[part 4 of 12: package /AUTOSAR_Dem/SwComponentTypes]
AUTOSAR XML (schema 4-2-2)
package /AUTOSAR_Dem/SwComponentTypes  (continued)
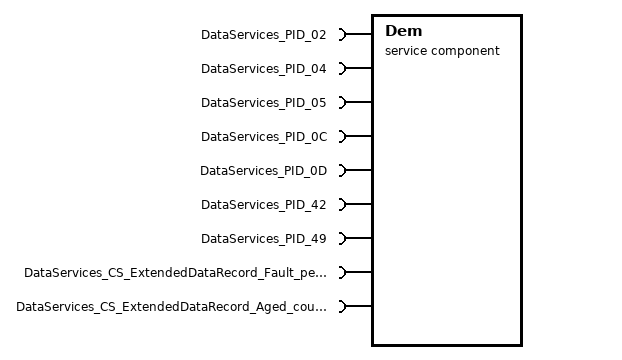
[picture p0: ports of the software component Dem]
  service sw component type Dem  (continued)
    2013 x provide port:  (continued)
      EvtInfo_DemEventParameter_ECU5_DTC09: provided-interface=DiagnosticInfo
        provided-com-specs:
          operation=DiagnosticInfo/GetEventStatus, queue-length=1
          operation=DiagnosticInfo/GetEventFailed, queue-length=1
          operation=DiagnosticInfo/GetEventTested, queue-length=1
          operation=DiagnosticInfo/GetDTCOfEvent, queue-length=1
          operation=DiagnosticInfo/GetDebouncingOfEvent, queue-length=1
          operation=DiagnosticInfo/GetFaultDetectionCounter, queue-length=1
          operation=DiagnosticInfo/GetEventExtendedDataRecord, queue-length=1
          operation=DiagnosticInfo/GetEventExtendedDataRecordEx, queue-length=1
          operation=DiagnosticInfo/GetEventFreezeFrameData, queue-length=1
          operation=DiagnosticInfo/GetEventFreezeFrameDataEx, queue-length=1
      EvtInfo_DemEventParameter_ECU5_DTC10: provided-interface=DiagnosticInfo
        provided-com-specs:
          operation=DiagnosticInfo/GetEventStatus, queue-length=1
          operation=DiagnosticInfo/GetEventFailed, queue-length=1
          operation=DiagnosticInfo/GetEventTested, queue-length=1
          operation=DiagnosticInfo/GetDTCOfEvent, queue-length=1
          operation=DiagnosticInfo/GetDebouncingOfEvent, queue-length=1
          operation=DiagnosticInfo/GetFaultDetectionCounter, queue-length=1
          operation=DiagnosticInfo/GetEventExtendedDataRecord, queue-length=1
          operation=DiagnosticInfo/GetEventExtendedDataRecordEx, queue-length=1
          operation=DiagnosticInfo/GetEventFreezeFrameData, queue-length=1
          operation=DiagnosticInfo/GetEventFreezeFrameDataEx, queue-length=1
      EvtInfo_DemEventParameter_ECU5_DTC11: provided-interface=DiagnosticInfo
        provided-com-specs:
          operation=DiagnosticInfo/GetEventStatus, queue-length=1
          operation=DiagnosticInfo/GetEventFailed, queue-length=1
          operation=DiagnosticInfo/GetEventTested, queue-length=1
          operation=DiagnosticInfo/GetDTCOfEvent, queue-length=1
          operation=DiagnosticInfo/GetDebouncingOfEvent, queue-length=1
          operation=DiagnosticInfo/GetFaultDetectionCounter, queue-length=1
          operation=DiagnosticInfo/GetEventExtendedDataRecord, queue-length=1
          operation=DiagnosticInfo/GetEventExtendedDataRecordEx, queue-length=1
          operation=DiagnosticInfo/GetEventFreezeFrameData, queue-length=1
          operation=DiagnosticInfo/GetEventFreezeFrameDataEx, queue-length=1
      EvtInfo_DemEventParameter_ECU5_DTC12: provided-interface=DiagnosticInfo
        provided-com-specs:
          operation=DiagnosticInfo/GetEventStatus, queue-length=1
          operation=DiagnosticInfo/GetEventFailed, queue-length=1
          operation=DiagnosticInfo/GetEventTested, queue-length=1
          operation=DiagnosticInfo/GetDTCOfEvent, queue-length=1
          operation=DiagnosticInfo/GetDebouncingOfEvent, queue-length=1
          operation=DiagnosticInfo/GetFaultDetectionCounter, queue-length=1
          operation=DiagnosticInfo/GetEventExtendedDataRecord, queue-length=1
          operation=DiagnosticInfo/GetEventExtendedDataRecordEx, queue-length=1
          operation=DiagnosticInfo/GetEventFreezeFrameData, queue-length=1
          operation=DiagnosticInfo/GetEventFreezeFrameDataEx, queue-length=1
      EvtInfo_DemEventParameter_ECU5_DTC13: provided-interface=DiagnosticInfo
        provided-com-specs:
          operation=DiagnosticInfo/GetEventStatus, queue-length=1
          operation=DiagnosticInfo/GetEventFailed, queue-length=1
          operation=DiagnosticInfo/GetEventTested, queue-length=1
          operation=DiagnosticInfo/GetDTCOfEvent, queue-length=1
          operation=DiagnosticInfo/GetDebouncingOfEvent, queue-length=1
          operation=DiagnosticInfo/GetFaultDetectionCounter, queue-length=1
          operation=DiagnosticInfo/GetEventExtendedDataRecord, queue-length=1
          operation=DiagnosticInfo/GetEventExtendedDataRecordEx, queue-length=1
          operation=DiagnosticInfo/GetEventFreezeFrameData, queue-length=1
          operation=DiagnosticInfo/GetEventFreezeFrameDataEx, queue-length=1
      EvtInfo_DemEventParameter_ECU5_DTC14: provided-interface=DiagnosticInfo
        provided-com-specs:
          operation=DiagnosticInfo/GetEventStatus, queue-length=1
          operation=DiagnosticInfo/GetEventFailed, queue-length=1
          operation=DiagnosticInfo/GetEventTested, queue-length=1
          operation=DiagnosticInfo/GetDTCOfEvent, queue-length=1
          operation=DiagnosticInfo/GetDebouncingOfEvent, queue-length=1
          operation=DiagnosticInfo/GetFaultDetectionCounter, queue-length=1
          operation=DiagnosticInfo/GetEventExtendedDataRecord, queue-length=1
          operation=DiagnosticInfo/GetEventExtendedDataRecordEx, queue-length=1
          operation=DiagnosticInfo/GetEventFreezeFrameData, queue-length=1
          operation=DiagnosticInfo/GetEventFreezeFrameDataEx, queue-length=1
      EvtInfo_DemEventParameter_ECU5_DTC15: provided-interface=DiagnosticInfo
        provided-com-specs:
          operation=DiagnosticInfo/GetEventStatus, queue-length=1
          operation=DiagnosticInfo/GetEventFailed, queue-length=1
          operation=DiagnosticInfo/GetEventTested, queue-length=1
          operation=DiagnosticInfo/GetDTCOfEvent, queue-length=1
          operation=DiagnosticInfo/GetDebouncingOfEvent, queue-length=1
          operation=DiagnosticInfo/GetFaultDetectionCounter, queue-length=1
          operation=DiagnosticInfo/GetEventExtendedDataRecord, queue-length=1
          operation=DiagnosticInfo/GetEventExtendedDataRecordEx, queue-length=1
          operation=DiagnosticInfo/GetEventFreezeFrameData, queue-length=1
          operation=DiagnosticInfo/GetEventFreezeFrameDataEx, queue-length=1
      EvtInfo_DemEventParameter_ECU5_DTC16: provided-interface=DiagnosticInfo
        provided-com-specs:
          operation=DiagnosticInfo/GetEventStatus, queue-length=1
          operation=DiagnosticInfo/GetEventFailed, queue-length=1
          operation=DiagnosticInfo/GetEventTested, queue-length=1
          operation=DiagnosticInfo/GetDTCOfEvent, queue-length=1
          operation=DiagnosticInfo/GetDebouncingOfEvent, queue-length=1
          operation=DiagnosticInfo/GetFaultDetectionCounter, queue-length=1
          operation=DiagnosticInfo/GetEventExtendedDataRecord, queue-length=1
          operation=DiagnosticInfo/GetEventExtendedDataRecordEx, queue-length=1
          operation=DiagnosticInfo/GetEventFreezeFrameData, queue-length=1
          operation=DiagnosticInfo/GetEventFreezeFrameDataEx, queue-length=1
      EvtInfo_DemEventParameter_ECU5_DTC17: provided-interface=DiagnosticInfo
        provided-com-specs:
          operation=DiagnosticInfo/GetEventStatus, queue-length=1
          operation=DiagnosticInfo/GetEventFailed, queue-length=1
          operation=DiagnosticInfo/GetEventTested, queue-length=1
          operation=DiagnosticInfo/GetDTCOfEvent, queue-length=1
          operation=DiagnosticInfo/GetDebouncingOfEvent, queue-length=1
          operation=DiagnosticInfo/GetFaultDetectionCounter, queue-length=1
          operation=DiagnosticInfo/GetEventExtendedDataRecord, queue-length=1
          operation=DiagnosticInfo/GetEventExtendedDataRecordEx, queue-length=1
          operation=DiagnosticInfo/GetEventFreezeFrameData, queue-length=1
          operation=DiagnosticInfo/GetEventFreezeFrameDataEx, queue-length=1
      EvtInfo_DemEventParameter_ECU5_DTC18: provided-interface=DiagnosticInfo
        provided-com-specs:
          operation=DiagnosticInfo/GetEventStatus, queue-length=1
          operation=DiagnosticInfo/GetEventFailed, queue-length=1
          operation=DiagnosticInfo/GetEventTested, queue-length=1
          operation=DiagnosticInfo/GetDTCOfEvent, queue-length=1
          operation=DiagnosticInfo/GetDebouncingOfEvent, queue-length=1
          operation=DiagnosticInfo/GetFaultDetectionCounter, queue-length=1
          operation=DiagnosticInfo/GetEventExtendedDataRecord, queue-length=1
          operation=DiagnosticInfo/GetEventExtendedDataRecordEx, queue-length=1
          operation=DiagnosticInfo/GetEventFreezeFrameData, queue-length=1
          operation=DiagnosticInfo/GetEventFreezeFrameDataEx, queue-length=1
      EvtInfo_DemEventParameter_ECU5_DTC19: provided-interface=DiagnosticInfo
        provided-com-specs:
          operation=DiagnosticInfo/GetEventStatus, queue-length=1
          operation=DiagnosticInfo/GetEventFailed, queue-length=1
          operation=DiagnosticInfo/GetEventTested, queue-length=1
          operation=DiagnosticInfo/GetDTCOfEvent, queue-length=1
          operation=DiagnosticInfo/GetDebouncingOfEvent, queue-length=1
          operation=DiagnosticInfo/GetFaultDetectionCounter, queue-length=1
          operation=DiagnosticInfo/GetEventExtendedDataRecord, queue-length=1
          operation=DiagnosticInfo/GetEventExtendedDataRecordEx, queue-length=1
          operation=DiagnosticInfo/GetEventFreezeFrameData, queue-length=1
          operation=DiagnosticInfo/GetEventFreezeFrameDataEx, queue-length=1
      EvtInfo_DemEventParameter_ECU5_DTC20: provided-interface=DiagnosticInfo
        provided-com-specs:
          operation=DiagnosticInfo/GetEventStatus, queue-length=1
          operation=DiagnosticInfo/GetEventFailed, queue-length=1
          operation=DiagnosticInfo/GetEventTested, queue-length=1
          operation=DiagnosticInfo/GetDTCOfEvent, queue-length=1
          operation=DiagnosticInfo/GetDebouncingOfEvent, queue-length=1
          operation=DiagnosticInfo/GetFaultDetectionCounter, queue-length=1
          operation=DiagnosticInfo/GetEventExtendedDataRecord, queue-length=1
          operation=DiagnosticInfo/GetEventExtendedDataRecordEx, queue-length=1
          operation=DiagnosticInfo/GetEventFreezeFrameData, queue-length=1
          operation=DiagnosticInfo/GetEventFreezeFrameDataEx, queue-length=1
      EvtInfo_DemEventParameter_ECU5_DTC21: provided-interface=DiagnosticInfo
        provided-com-specs:
          operation=DiagnosticInfo/GetEventStatus, queue-length=1
          operation=DiagnosticInfo/GetEventFailed, queue-length=1
          operation=DiagnosticInfo/GetEventTested, queue-length=1
          operation=DiagnosticInfo/GetDTCOfEvent, queue-length=1
          operation=DiagnosticInfo/GetDebouncingOfEvent, queue-length=1
          operation=DiagnosticInfo/GetFaultDetectionCounter, queue-length=1
          operation=DiagnosticInfo/GetEventExtendedDataRecord, queue-length=1
          operation=DiagnosticInfo/GetEventExtendedDataRecordEx, queue-length=1
          operation=DiagnosticInfo/GetEventFreezeFrameData, queue-length=1
          operation=DiagnosticInfo/GetEventFreezeFrameDataEx, queue-length=1
      EvtInfo_DemEventParameter_ECU5_DTC22: provided-interface=DiagnosticInfo
        provided-com-specs:
          operation=DiagnosticInfo/GetEventStatus, queue-length=1
          operation=DiagnosticInfo/GetEventFailed, queue-length=1
          operation=DiagnosticInfo/GetEventTested, queue-length=1
          operation=DiagnosticInfo/GetDTCOfEvent, queue-length=1
          operation=DiagnosticInfo/GetDebouncingOfEvent, queue-length=1
          operation=DiagnosticInfo/GetFaultDetectionCounter, queue-length=1
          operation=DiagnosticInfo/GetEventExtendedDataRecord, queue-length=1
          operation=DiagnosticInfo/GetEventExtendedDataRecordEx, queue-length=1
          operation=DiagnosticInfo/GetEventFreezeFrameData, queue-length=1
          operation=DiagnosticInfo/GetEventFreezeFrameDataEx, queue-length=1
      EvtInfo_DemEventParameter_ECU5_DTC23: provided-interface=DiagnosticInfo
        provided-com-specs:
          operation=DiagnosticInfo/GetEventStatus, queue-length=1
          operation=DiagnosticInfo/GetEventFailed, queue-length=1
          operation=DiagnosticInfo/GetEventTested, queue-length=1
          operation=DiagnosticInfo/GetDTCOfEvent, queue-length=1
          operation=DiagnosticInfo/GetDebouncingOfEvent, queue-length=1
          operation=DiagnosticInfo/GetFaultDetectionCounter, queue-length=1
          operation=DiagnosticInfo/GetEventExtendedDataRecord, queue-length=1
          operation=DiagnosticInfo/GetEventExtendedDataRecordEx, queue-length=1
          operation=DiagnosticInfo/GetEventFreezeFrameData, queue-length=1
          operation=DiagnosticInfo/GetEventFreezeFrameDataEx, queue-length=1
      EvtInfo_DemEventParameter_ECU5_DTC24: provided-interface=DiagnosticInfo
        provided-com-specs:
          operation=DiagnosticInfo/GetEventStatus, queue-length=1
          operation=DiagnosticInfo/GetEventFailed, queue-length=1
          operation=DiagnosticInfo/GetEventTested, queue-length=1
          operation=DiagnosticInfo/GetDTCOfEvent, queue-length=1
          operation=DiagnosticInfo/GetDebouncingOfEvent, queue-length=1
          operation=DiagnosticInfo/GetFaultDetectionCounter, queue-length=1
          operation=DiagnosticInfo/GetEventExtendedDataRecord, queue-length=1
          operation=DiagnosticInfo/GetEventExtendedDataRecordEx, queue-length=1
          operation=DiagnosticInfo/GetEventFreezeFrameData, queue-length=1
          operation=DiagnosticInfo/GetEventFreezeFrameDataEx, queue-length=1
      EvtInfo_DemEventParameter_ECU5_DTC25: provided-interface=DiagnosticInfo
        provided-com-specs:
          operation=DiagnosticInfo/GetEventStatus, queue-length=1
          operation=DiagnosticInfo/GetEventFailed, queue-length=1
          operation=DiagnosticInfo/GetEventTested, queue-length=1
          operation=DiagnosticInfo/GetDTCOfEvent, queue-length=1
          operation=DiagnosticInfo/GetDebouncingOfEvent, queue-length=1
          operation=DiagnosticInfo/GetFaultDetectionCounter, queue-length=1
          operation=DiagnosticInfo/GetEventExtendedDataRecord, queue-length=1
          operation=DiagnosticInfo/GetEventExtendedDataRecordEx, queue-length=1
          operation=DiagnosticInfo/GetEventFreezeFrameData, queue-length=1
          operation=DiagnosticInfo/GetEventFreezeFrameDataEx, queue-length=1
      EvtInfo_DemEventParameter_ECU5_DTC26: provided-interface=DiagnosticInfo
        provided-com-specs:
          operation=DiagnosticInfo/GetEventStatus, queue-length=1
          operation=DiagnosticInfo/GetEventFailed, queue-length=1
          operation=DiagnosticInfo/GetEventTested, queue-length=1
          operation=DiagnosticInfo/GetDTCOfEvent, queue-length=1
          operation=DiagnosticInfo/GetDebouncingOfEvent, queue-length=1
          operation=DiagnosticInfo/GetFaultDetectionCounter, queue-length=1
          operation=DiagnosticInfo/GetEventExtendedDataRecord, queue-length=1
          operation=DiagnosticInfo/GetEventExtendedDataRecordEx, queue-length=1
          operation=DiagnosticInfo/GetEventFreezeFrameData, queue-length=1
          operation=DiagnosticInfo/GetEventFreezeFrameDataEx, queue-length=1
      EvtInfo_DemEventParameter_ECU5_DTC27: provided-interface=DiagnosticInfo
        provided-com-specs:
          operation=DiagnosticInfo/GetEventStatus, queue-length=1
          operation=DiagnosticInfo/GetEventFailed, queue-length=1
          operation=DiagnosticInfo/GetEventTested, queue-length=1
          operation=DiagnosticInfo/GetDTCOfEvent, queue-length=1
          operation=DiagnosticInfo/GetDebouncingOfEvent, queue-length=1
          operation=DiagnosticInfo/GetFaultDetectionCounter, queue-length=1
          operation=DiagnosticInfo/GetEventExtendedDataRecord, queue-length=1
          operation=DiagnosticInfo/GetEventExtendedDataRecordEx, queue-length=1
          operation=DiagnosticInfo/GetEventFreezeFrameData, queue-length=1
          operation=DiagnosticInfo/GetEventFreezeFrameDataEx, queue-length=1
      EvtInfo_DemEventParameter_ECU5_DTC28: provided-interface=DiagnosticInfo
        provided-com-specs:
          operation=DiagnosticInfo/GetEventStatus, queue-length=1
          operation=DiagnosticInfo/GetEventFailed, queue-length=1
          operation=DiagnosticInfo/GetEventTested, queue-length=1
          operation=DiagnosticInfo/GetDTCOfEvent, queue-length=1
          operation=DiagnosticInfo/GetDebouncingOfEvent, queue-length=1
          operation=DiagnosticInfo/GetFaultDetectionCounter, queue-length=1
          operation=DiagnosticInfo/GetEventExtendedDataRecord, queue-length=1
          operation=DiagnosticInfo/GetEventExtendedDataRecordEx, queue-length=1
          operation=DiagnosticInfo/GetEventFreezeFrameData, queue-length=1
          operation=DiagnosticInfo/GetEventFreezeFrameDataEx, queue-length=1
      EvtInfo_DemEventParameter_ECU5_DTC29: provided-interface=DiagnosticInfo
        provided-com-specs:
          operation=DiagnosticInfo/GetEventStatus, queue-length=1
          operation=DiagnosticInfo/GetEventFailed, queue-length=1
          operation=DiagnosticInfo/GetEventTested, queue-length=1
          operation=DiagnosticInfo/GetDTCOfEvent, queue-length=1
          operation=DiagnosticInfo/GetDebouncingOfEvent, queue-length=1
          operation=DiagnosticInfo/GetFaultDetectionCounter, queue-length=1
          operation=DiagnosticInfo/GetEventExtendedDataRecord, queue-length=1
          operation=DiagnosticInfo/GetEventExtendedDataRecordEx, queue-length=1
          operation=DiagnosticInfo/GetEventFreezeFrameData, queue-length=1
          operation=DiagnosticInfo/GetEventFreezeFrameDataEx, queue-length=1
      EvtInfo_DemEventParameter_ECU5_DTC30: provided-interface=DiagnosticInfo
        provided-com-specs:
          operation=DiagnosticInfo/GetEventStatus, queue-length=1
          operation=DiagnosticInfo/GetEventFailed, queue-length=1
          operation=DiagnosticInfo/GetEventTested, queue-length=1
          operation=DiagnosticInfo/GetDTCOfEvent, queue-length=1
          operation=DiagnosticInfo/GetDebouncingOfEvent, queue-length=1
          operation=DiagnosticInfo/GetFaultDetectionCounter, queue-length=1
          operation=DiagnosticInfo/GetEventExtendedDataRecord, queue-length=1
          operation=DiagnosticInfo/GetEventExtendedDataRecordEx, queue-length=1
          operation=DiagnosticInfo/GetEventFreezeFrameData, queue-length=1
          operation=DiagnosticInfo/GetEventFreezeFrameDataEx, queue-length=1
      EvtInfo_DemEventParameter_ECU5_DTC31: provided-interface=DiagnosticInfo
        provided-com-specs:
          operation=DiagnosticInfo/GetEventStatus, queue-length=1
          operation=DiagnosticInfo/GetEventFailed, queue-length=1
          operation=DiagnosticInfo/GetEventTested, queue-length=1
          operation=DiagnosticInfo/GetDTCOfEvent, queue-length=1
          operation=DiagnosticInfo/GetDebouncingOfEvent, queue-length=1
          operation=DiagnosticInfo/GetFaultDetectionCounter, queue-length=1
          operation=DiagnosticInfo/GetEventExtendedDataRecord, queue-length=1
          operation=DiagnosticInfo/GetEventExtendedDataRecordEx, queue-length=1
          operation=DiagnosticInfo/GetEventFreezeFrameData, queue-length=1
          operation=DiagnosticInfo/GetEventFreezeFrameDataEx, queue-length=1
      EvtInfo_DemEventParameter_ECU5_DTC32: provided-interface=DiagnosticInfo
        provided-com-specs:
          operation=DiagnosticInfo/GetEventStatus, queue-length=1
          operation=DiagnosticInfo/GetEventFailed, queue-length=1
          operation=DiagnosticInfo/GetEventTested, queue-length=1
          operation=DiagnosticInfo/GetDTCOfEvent, queue-length=1
          operation=DiagnosticInfo/GetDebouncingOfEvent, queue-length=1
          operation=DiagnosticInfo/GetFaultDetectionCounter, queue-length=1
          operation=DiagnosticInfo/GetEventExtendedDataRecord, queue-length=1
          operation=DiagnosticInfo/GetEventExtendedDataRecordEx, queue-length=1
          operation=DiagnosticInfo/GetEventFreezeFrameData, queue-length=1
          operation=DiagnosticInfo/GetEventFreezeFrameDataEx, queue-length=1
      EvtInfo_DemEventParameter_ECU5_DTC33: provided-interface=DiagnosticInfo
        provided-com-specs:
          operation=DiagnosticInfo/GetEventStatus, queue-length=1
          operation=DiagnosticInfo/GetEventFailed, queue-length=1
          operation=DiagnosticInfo/GetEventTested, queue-length=1
          operation=DiagnosticInfo/GetDTCOfEvent, queue-length=1
          operation=DiagnosticInfo/GetDebouncingOfEvent, queue-length=1
          operation=DiagnosticInfo/GetFaultDetectionCounter, queue-length=1
          operation=DiagnosticInfo/GetEventExtendedDataRecord, queue-length=1
          operation=DiagnosticInfo/GetEventExtendedDataRecordEx, queue-length=1
          operation=DiagnosticInfo/GetEventFreezeFrameData, queue-length=1
          operation=DiagnosticInfo/GetEventFreezeFrameDataEx, queue-length=1
      EvtInfo_DemEventParameter_ECU5_DTC34: provided-interface=DiagnosticInfo
        provided-com-specs:
          operation=DiagnosticInfo/GetEventStatus, queue-length=1
          operation=DiagnosticInfo/GetEventFailed, queue-length=1
          operation=DiagnosticInfo/GetEventTested, queue-length=1
          operation=DiagnosticInfo/GetDTCOfEvent, queue-length=1
          operation=DiagnosticInfo/GetDebouncingOfEvent, queue-length=1
          operation=DiagnosticInfo/GetFaultDetectionCounter, queue-length=1
          operation=DiagnosticInfo/GetEventExtendedDataRecord, queue-length=1
          operation=DiagnosticInfo/GetEventExtendedDataRecordEx, queue-length=1
          operation=DiagnosticInfo/GetEventFreezeFrameData, queue-length=1
          operation=DiagnosticInfo/GetEventFreezeFrameDataEx, queue-length=1
      EvtInfo_DemEventParameter_ECU5_DTC35: provided-interface=DiagnosticInfo
        provided-com-specs:
          operation=DiagnosticInfo/GetEventStatus, queue-length=1
          operation=DiagnosticInfo/GetEventFailed, queue-length=1
          operation=DiagnosticInfo/GetEventTested, queue-length=1
          operation=DiagnosticInfo/GetDTCOfEvent, queue-length=1
          operation=DiagnosticInfo/GetDebouncingOfEvent, queue-length=1
          operation=DiagnosticInfo/GetFaultDetectionCounter, queue-length=1
          operation=DiagnosticInfo/GetEventExtendedDataRecord, queue-length=1
          operation=DiagnosticInfo/GetEventExtendedDataRecordEx, queue-length=1
          operation=DiagnosticInfo/GetEventFreezeFrameData, queue-length=1
          operation=DiagnosticInfo/GetEventFreezeFrameDataEx, queue-length=1
      EvtInfo_DemEventParameter_ECU5_DTC36: provided-interface=DiagnosticInfo
        provided-com-specs:
          operation=DiagnosticInfo/GetEventStatus, queue-length=1
          operation=DiagnosticInfo/GetEventFailed, queue-length=1
          operation=DiagnosticInfo/GetEventTested, queue-length=1
          operation=DiagnosticInfo/GetDTCOfEvent, queue-length=1
          operation=DiagnosticInfo/GetDebouncingOfEvent, queue-length=1
          operation=DiagnosticInfo/GetFaultDetectionCounter, queue-length=1
          operation=DiagnosticInfo/GetEventExtendedDataRecord, queue-length=1
          operation=DiagnosticInfo/GetEventExtendedDataRecordEx, queue-length=1
          operation=DiagnosticInfo/GetEventFreezeFrameData, queue-length=1
          operation=DiagnosticInfo/GetEventFreezeFrameDataEx, queue-length=1
      EvtInfo_DemEventParameter_ECU5_DTC37: provided-interface=DiagnosticInfo
        provided-com-specs:
          operation=DiagnosticInfo/GetEventStatus, queue-length=1
          operation=DiagnosticInfo/GetEventFailed, queue-length=1
          operation=DiagnosticInfo/GetEventTested, queue-length=1
          operation=DiagnosticInfo/GetDTCOfEvent, queue-length=1
          operation=DiagnosticInfo/GetDebouncingOfEvent, queue-length=1
          operation=DiagnosticInfo/GetFaultDetectionCounter, queue-length=1
          operation=DiagnosticInfo/GetEventExtendedDataRecord, queue-length=1
          operation=DiagnosticInfo/GetEventExtendedDataRecordEx, queue-length=1
          operation=DiagnosticInfo/GetEventFreezeFrameData, queue-length=1
          operation=DiagnosticInfo/GetEventFreezeFrameDataEx, queue-length=1
      EvtInfo_DemEventParameter_ECU5_DTC38: provided-interface=DiagnosticInfo
        provided-com-specs:
          operation=DiagnosticInfo/GetEventStatus, queue-length=1
          operation=DiagnosticInfo/GetEventFailed, queue-length=1
          operation=DiagnosticInfo/GetEventTested, queue-length=1
          operation=DiagnosticInfo/GetDTCOfEvent, queue-length=1
          operation=DiagnosticInfo/GetDebouncingOfEvent, queue-length=1
          operation=DiagnosticInfo/GetFaultDetectionCounter, queue-length=1
          operation=DiagnosticInfo/GetEventExtendedDataRecord, queue-length=1
          operation=DiagnosticInfo/GetEventExtendedDataRecordEx, queue-length=1
          operation=DiagnosticInfo/GetEventFreezeFrameData, queue-length=1
          operation=DiagnosticInfo/GetEventFreezeFrameDataEx, queue-length=1
      EvtInfo_DemEventParameter_ECU5_DTC39: provided-interface=DiagnosticInfo
        provided-com-specs:
          operation=DiagnosticInfo/GetEventStatus, queue-length=1
          operation=DiagnosticInfo/GetEventFailed, queue-length=1
          operation=DiagnosticInfo/GetEventTested, queue-length=1
          operation=DiagnosticInfo/GetDTCOfEvent, queue-length=1
          operation=DiagnosticInfo/GetDebouncingOfEvent, queue-length=1
          operation=DiagnosticInfo/GetFaultDetectionCounter, queue-length=1
          operation=DiagnosticInfo/GetEventExtendedDataRecord, queue-length=1
          operation=DiagnosticInfo/GetEventExtendedDataRecordEx, queue-length=1
          operation=DiagnosticInfo/GetEventFreezeFrameData, queue-length=1
          operation=DiagnosticInfo/GetEventFreezeFrameDataEx, queue-length=1
      EvtInfo_DemEventParameter_ECU5_DTC40: provided-interface=DiagnosticInfo
        provided-com-specs:
          operation=DiagnosticInfo/GetEventStatus, queue-length=1
          operation=DiagnosticInfo/GetEventFailed, queue-length=1
          operation=DiagnosticInfo/GetEventTested, queue-length=1
          operation=DiagnosticInfo/GetDTCOfEvent, queue-length=1
          operation=DiagnosticInfo/GetDebouncingOfEvent, queue-length=1
          operation=DiagnosticInfo/GetFaultDetectionCounter, queue-length=1
          operation=DiagnosticInfo/GetEventExtendedDataRecord, queue-length=1
          operation=DiagnosticInfo/GetEventExtendedDataRecordEx, queue-length=1
          operation=DiagnosticInfo/GetEventFreezeFrameData, queue-length=1
          operation=DiagnosticInfo/GetEventFreezeFrameDataEx, queue-length=1
      EvtInfo_DemEventParameter_ECU5_DTC41: provided-interface=DiagnosticInfo
        provided-com-specs:
          operation=DiagnosticInfo/GetEventStatus, queue-length=1
          operation=DiagnosticInfo/GetEventFailed, queue-length=1
          operation=DiagnosticInfo/GetEventTested, queue-length=1
          operation=DiagnosticInfo/GetDTCOfEvent, queue-length=1
          operation=DiagnosticInfo/GetDebouncingOfEvent, queue-length=1
          operation=DiagnosticInfo/GetFaultDetectionCounter, queue-length=1
          operation=DiagnosticInfo/GetEventExtendedDataRecord, queue-length=1
          operation=DiagnosticInfo/GetEventExtendedDataRecordEx, queue-length=1
          operation=DiagnosticInfo/GetEventFreezeFrameData, queue-length=1
          operation=DiagnosticInfo/GetEventFreezeFrameDataEx, queue-length=1
      EvtInfo_DemEventParameter_ECU5_DTC42: provided-interface=DiagnosticInfo
        provided-com-specs:
          operation=DiagnosticInfo/GetEventStatus, queue-length=1
          operation=DiagnosticInfo/GetEventFailed, queue-length=1
          operation=DiagnosticInfo/GetEventTested, queue-length=1
          operation=DiagnosticInfo/GetDTCOfEvent, queue-length=1
          operation=DiagnosticInfo/GetDebouncingOfEvent, queue-length=1
          operation=DiagnosticInfo/GetFaultDetectionCounter, queue-length=1
          operation=DiagnosticInfo/GetEventExtendedDataRecord, queue-length=1
          operation=DiagnosticInfo/GetEventExtendedDataRecordEx, queue-length=1
          operation=DiagnosticInfo/GetEventFreezeFrameData, queue-length=1
          operation=DiagnosticInfo/GetEventFreezeFrameDataEx, queue-length=1
      EvtInfo_DemEventParameter_ECU5_DTC43: provided-interface=DiagnosticInfo
        provided-com-specs:
          operation=DiagnosticInfo/GetEventStatus, queue-length=1
          operation=DiagnosticInfo/GetEventFailed, queue-length=1
          operation=DiagnosticInfo/GetEventTested, queue-length=1
          operation=DiagnosticInfo/GetDTCOfEvent, queue-length=1
          operation=DiagnosticInfo/GetDebouncingOfEvent, queue-length=1
          operation=DiagnosticInfo/GetFaultDetectionCounter, queue-length=1
          operation=DiagnosticInfo/GetEventExtendedDataRecord, queue-length=1
          operation=DiagnosticInfo/GetEventExtendedDataRecordEx, queue-length=1
          operation=DiagnosticInfo/GetEventFreezeFrameData, queue-length=1
          operation=DiagnosticInfo/GetEventFreezeFrameDataEx, queue-length=1
      EvtInfo_DemEventParameter_ECU5_DTC44: provided-interface=DiagnosticInfo
        provided-com-specs:
          operation=DiagnosticInfo/GetEventStatus, queue-length=1
          operation=DiagnosticInfo/GetEventFailed, queue-length=1
          operation=DiagnosticInfo/GetEventTested, queue-length=1
          operation=DiagnosticInfo/GetDTCOfEvent, queue-length=1
          operation=DiagnosticInfo/GetDebouncingOfEvent, queue-length=1
          operation=DiagnosticInfo/GetFaultDetectionCounter, queue-length=1
          operation=DiagnosticInfo/GetEventExtendedDataRecord, queue-length=1
          operation=DiagnosticInfo/GetEventExtendedDataRecordEx, queue-length=1
          operation=DiagnosticInfo/GetEventFreezeFrameData, queue-length=1
          operation=DiagnosticInfo/GetEventFreezeFrameDataEx, queue-length=1
      EvtInfo_DemEventParameter_ECU5_DTC45: provided-interface=DiagnosticInfo
        provided-com-specs:
          operation=DiagnosticInfo/GetEventStatus, queue-length=1
          operation=DiagnosticInfo/GetEventFailed, queue-length=1
          operation=DiagnosticInfo/GetEventTested, queue-length=1
          operation=DiagnosticInfo/GetDTCOfEvent, queue-length=1
          operation=DiagnosticInfo/GetDebouncingOfEvent, queue-length=1
          operation=DiagnosticInfo/GetFaultDetectionCounter, queue-length=1
          operation=DiagnosticInfo/GetEventExtendedDataRecord, queue-length=1
          operation=DiagnosticInfo/GetEventExtendedDataRecordEx, queue-length=1
          operation=DiagnosticInfo/GetEventFreezeFrameData, queue-length=1
          operation=DiagnosticInfo/GetEventFreezeFrameDataEx, queue-length=1
      EvtInfo_DemEventParameter_ECU5_DTC46: provided-interface=DiagnosticInfo
        provided-com-specs:
          operation=DiagnosticInfo/GetEventStatus, queue-length=1
          operation=DiagnosticInfo/GetEventFailed, queue-length=1
          operation=DiagnosticInfo/GetEventTested, queue-length=1
          operation=DiagnosticInfo/GetDTCOfEvent, queue-length=1
          operation=DiagnosticInfo/GetDebouncingOfEvent, queue-length=1
          operation=DiagnosticInfo/GetFaultDetectionCounter, queue-length=1
          operation=DiagnosticInfo/GetEventExtendedDataRecord, queue-length=1
          operation=DiagnosticInfo/GetEventExtendedDataRecordEx, queue-length=1
          operation=DiagnosticInfo/GetEventFreezeFrameData, queue-length=1
          operation=DiagnosticInfo/GetEventFreezeFrameDataEx, queue-length=1
      EvtInfo_DemEventParameter_ECU5_DTC47: provided-interface=DiagnosticInfo
        provided-com-specs:
          operation=DiagnosticInfo/GetEventStatus, queue-length=1
          operation=DiagnosticInfo/GetEventFailed, queue-length=1
          operation=DiagnosticInfo/GetEventTested, queue-length=1
          operation=DiagnosticInfo/GetDTCOfEvent, queue-length=1
          operation=DiagnosticInfo/GetDebouncingOfEvent, queue-length=1
          operation=DiagnosticInfo/GetFaultDetectionCounter, queue-length=1
          operation=DiagnosticInfo/GetEventExtendedDataRecord, queue-length=1
          operation=DiagnosticInfo/GetEventExtendedDataRecordEx, queue-length=1
          operation=DiagnosticInfo/GetEventFreezeFrameData, queue-length=1
          operation=DiagnosticInfo/GetEventFreezeFrameDataEx, queue-length=1
      EvtInfo_DemEventParameter_ECU5_DTC48: provided-interface=DiagnosticInfo
        provided-com-specs:
          operation=DiagnosticInfo/GetEventStatus, queue-length=1
          operation=DiagnosticInfo/GetEventFailed, queue-length=1
          operation=DiagnosticInfo/GetEventTested, queue-length=1
          operation=DiagnosticInfo/GetDTCOfEvent, queue-length=1
          operation=DiagnosticInfo/GetDebouncingOfEvent, queue-length=1
          operation=DiagnosticInfo/GetFaultDetectionCounter, queue-length=1
          operation=DiagnosticInfo/GetEventExtendedDataRecord, queue-length=1
          operation=DiagnosticInfo/GetEventExtendedDataRecordEx, queue-length=1
          operation=DiagnosticInfo/GetEventFreezeFrameData, queue-length=1
          operation=DiagnosticInfo/GetEventFreezeFrameDataEx, queue-length=1
      EvtInfo_DemEventParameter_ECU5_DTC49: provided-interface=DiagnosticInfo
        provided-com-specs:
          operation=DiagnosticInfo/GetEventStatus, queue-length=1
          operation=DiagnosticInfo/GetEventFailed, queue-length=1
          operation=DiagnosticInfo/GetEventTested, queue-length=1
          operation=DiagnosticInfo/GetDTCOfEvent, queue-length=1
          operation=DiagnosticInfo/GetDebouncingOfEvent, queue-length=1
          operation=DiagnosticInfo/GetFaultDetectionCounter, queue-length=1
          operation=DiagnosticInfo/GetEventExtendedDataRecord, queue-length=1
          operation=DiagnosticInfo/GetEventExtendedDataRecordEx, queue-length=1
          operation=DiagnosticInfo/GetEventFreezeFrameData, queue-length=1
          operation=DiagnosticInfo/GetEventFreezeFrameDataEx, queue-length=1
      EvtInfo_DemEventParameter_ECU5_DTC50: provided-interface=DiagnosticInfo
        provided-com-specs:
          operation=DiagnosticInfo/GetEventStatus, queue-length=1
          operation=DiagnosticInfo/GetEventFailed, queue-length=1
          operation=DiagnosticInfo/GetEventTested, queue-length=1
          operation=DiagnosticInfo/GetDTCOfEvent, queue-length=1
          operation=DiagnosticInfo/GetDebouncingOfEvent, queue-length=1
          operation=DiagnosticInfo/GetFaultDetectionCounter, queue-length=1
          operation=DiagnosticInfo/GetEventExtendedDataRecord, queue-length=1
          operation=DiagnosticInfo/GetEventExtendedDataRecordEx, queue-length=1
          operation=DiagnosticInfo/GetEventFreezeFrameData, queue-length=1
          operation=DiagnosticInfo/GetEventFreezeFrameDataEx, queue-length=1
      EvtInfo_DemEventParameter_ECU5_DTC51: provided-interface=DiagnosticInfo
        provided-com-specs:
          operation=DiagnosticInfo/GetEventStatus, queue-length=1
          operation=DiagnosticInfo/GetEventFailed, queue-length=1
          operation=DiagnosticInfo/GetEventTested, queue-length=1
          operation=DiagnosticInfo/GetDTCOfEvent, queue-length=1
          operation=DiagnosticInfo/GetDebouncingOfEvent, queue-length=1
          operation=DiagnosticInfo/GetFaultDetectionCounter, queue-length=1
          operation=DiagnosticInfo/GetEventExtendedDataRecord, queue-length=1
          operation=DiagnosticInfo/GetEventExtendedDataRecordEx, queue-length=1
          operation=DiagnosticInfo/GetEventFreezeFrameData, queue-length=1
          operation=DiagnosticInfo/GetEventFreezeFrameDataEx, queue-length=1
      EvtInfo_DemEventParameter_ECU5_DTC52: provided-interface=DiagnosticInfo
        provided-com-specs:
          operation=DiagnosticInfo/GetEventStatus, queue-length=1
          operation=DiagnosticInfo/GetEventFailed, queue-length=1
          operation=DiagnosticInfo/GetEventTested, queue-length=1
          operation=DiagnosticInfo/GetDTCOfEvent, queue-length=1
          operation=DiagnosticInfo/GetDebouncingOfEvent, queue-length=1
          operation=DiagnosticInfo/GetFaultDetectionCounter, queue-length=1
          operation=DiagnosticInfo/GetEventExtendedDataRecord, queue-length=1
          operation=DiagnosticInfo/GetEventExtendedDataRecordEx, queue-length=1
          operation=DiagnosticInfo/GetEventFreezeFrameData, queue-length=1
          operation=DiagnosticInfo/GetEventFreezeFrameDataEx, queue-length=1
      EvtInfo_DemEventParameter_ECU5_DTC53: provided-interface=DiagnosticInfo
        provided-com-specs:
          operation=DiagnosticInfo/GetEventStatus, queue-length=1
          operation=DiagnosticInfo/GetEventFailed, queue-length=1
          operation=DiagnosticInfo/GetEventTested, queue-length=1
          operation=DiagnosticInfo/GetDTCOfEvent, queue-length=1
          operation=DiagnosticInfo/GetDebouncingOfEvent, queue-length=1
          operation=DiagnosticInfo/GetFaultDetectionCounter, queue-length=1
          operation=DiagnosticInfo/GetEventExtendedDataRecord, queue-length=1
          operation=DiagnosticInfo/GetEventExtendedDataRecordEx, queue-length=1
          operation=DiagnosticInfo/GetEventFreezeFrameData, queue-length=1
          operation=DiagnosticInfo/GetEventFreezeFrameDataEx, queue-length=1
      EvtInfo_DemEventParameter_ECU5_DTC54: provided-interface=DiagnosticInfo
        provided-com-specs:
          operation=DiagnosticInfo/GetEventStatus, queue-length=1
          operation=DiagnosticInfo/GetEventFailed, queue-length=1
          operation=DiagnosticInfo/GetEventTested, queue-length=1
          operation=DiagnosticInfo/GetDTCOfEvent, queue-length=1
          operation=DiagnosticInfo/GetDebouncingOfEvent, queue-length=1
          operation=DiagnosticInfo/GetFaultDetectionCounter, queue-length=1
          operation=DiagnosticInfo/GetEventExtendedDataRecord, queue-length=1
          operation=DiagnosticInfo/GetEventExtendedDataRecordEx, queue-length=1
          operation=DiagnosticInfo/GetEventFreezeFrameData, queue-length=1
          operation=DiagnosticInfo/GetEventFreezeFrameDataEx, queue-length=1
      EvtInfo_DemEventParameter_ECU5_DTC55: provided-interface=DiagnosticInfo
        provided-com-specs:
          operation=DiagnosticInfo/GetEventStatus, queue-length=1
          operation=DiagnosticInfo/GetEventFailed, queue-length=1
          operation=DiagnosticInfo/GetEventTested, queue-length=1
          operation=DiagnosticInfo/GetDTCOfEvent, queue-length=1
          operation=DiagnosticInfo/GetDebouncingOfEvent, queue-length=1
          operation=DiagnosticInfo/GetFaultDetectionCounter, queue-length=1
          operation=DiagnosticInfo/GetEventExtendedDataRecord, queue-length=1
          operation=DiagnosticInfo/GetEventExtendedDataRecordEx, queue-length=1
          operation=DiagnosticInfo/GetEventFreezeFrameData, queue-length=1
          operation=DiagnosticInfo/GetEventFreezeFrameDataEx, queue-length=1
      EvtInfo_DemEventParameter_ECU5_DTC56: provided-interface=DiagnosticInfo
        provided-com-specs:
          operation=DiagnosticInfo/GetEventStatus, queue-length=1
          operation=DiagnosticInfo/GetEventFailed, queue-length=1
          operation=DiagnosticInfo/GetEventTested, queue-length=1
          operation=DiagnosticInfo/GetDTCOfEvent, queue-length=1
          operation=DiagnosticInfo/GetDebouncingOfEvent, queue-length=1
          operation=DiagnosticInfo/GetFaultDetectionCounter, queue-length=1
          operation=DiagnosticInfo/GetEventExtendedDataRecord, queue-length=1
          operation=DiagnosticInfo/GetEventExtendedDataRecordEx, queue-length=1
          operation=DiagnosticInfo/GetEventFreezeFrameData, queue-length=1
          operation=DiagnosticInfo/GetEventFreezeFrameDataEx, queue-length=1
      EvtInfo_DemEventParameter_ECU5_DTC57: provided-interface=DiagnosticInfo
        provided-com-specs:
          operation=DiagnosticInfo/GetEventStatus, queue-length=1
          operation=DiagnosticInfo/GetEventFailed, queue-length=1
          operation=DiagnosticInfo/GetEventTested, queue-length=1
          operation=DiagnosticInfo/GetDTCOfEvent, queue-length=1
          operation=DiagnosticInfo/GetDebouncingOfEvent, queue-length=1
          operation=DiagnosticInfo/GetFaultDetectionCounter, queue-length=1
          operation=DiagnosticInfo/GetEventExtendedDataRecord, queue-length=1
          operation=DiagnosticInfo/GetEventExtendedDataRecordEx, queue-length=1
          operation=DiagnosticInfo/GetEventFreezeFrameData, queue-length=1
          operation=DiagnosticInfo/GetEventFreezeFrameDataEx, queue-length=1
      EvtInfo_DemEventParameter_ECU5_DTC58: provided-interface=DiagnosticInfo
        provided-com-specs:
          operation=DiagnosticInfo/GetEventStatus, queue-length=1
          operation=DiagnosticInfo/GetEventFailed, queue-length=1
          operation=DiagnosticInfo/GetEventTested, queue-length=1
          operation=DiagnosticInfo/GetDTCOfEvent, queue-length=1
          operation=DiagnosticInfo/GetDebouncingOfEvent, queue-length=1
          operation=DiagnosticInfo/GetFaultDetectionCounter, queue-length=1
          operation=DiagnosticInfo/GetEventExtendedDataRecord, queue-length=1
          operation=DiagnosticInfo/GetEventExtendedDataRecordEx, queue-length=1
          operation=DiagnosticInfo/GetEventFreezeFrameData, queue-length=1
          operation=DiagnosticInfo/GetEventFreezeFrameDataEx, queue-length=1
      EvtInfo_DemEventParameter_ECU5_DTC59: provided-interface=DiagnosticInfo
        provided-com-specs:
          operation=DiagnosticInfo/GetEventStatus, queue-length=1
          operation=DiagnosticInfo/GetEventFailed, queue-length=1
          operation=DiagnosticInfo/GetEventTested, queue-length=1
          operation=DiagnosticInfo/GetDTCOfEvent, queue-length=1
          operation=DiagnosticInfo/GetDebouncingOfEvent, queue-length=1
          operation=DiagnosticInfo/GetFaultDetectionCounter, queue-length=1
          operation=DiagnosticInfo/GetEventExtendedDataRecord, queue-length=1
          operation=DiagnosticInfo/GetEventExtendedDataRecordEx, queue-length=1
          operation=DiagnosticInfo/GetEventFreezeFrameData, queue-length=1
          operation=DiagnosticInfo/GetEventFreezeFrameDataEx, queue-length=1
      EvtInfo_DemEventParameter_ECU5_DTC60: provided-interface=DiagnosticInfo
        provided-com-specs:
          operation=DiagnosticInfo/GetEventStatus, queue-length=1
          operation=DiagnosticInfo/GetEventFailed, queue-length=1
          operation=DiagnosticInfo/GetEventTested, queue-length=1
          operation=DiagnosticInfo/GetDTCOfEvent, queue-length=1
          operation=DiagnosticInfo/GetDebouncingOfEvent, queue-length=1
          operation=DiagnosticInfo/GetFaultDetectionCounter, queue-length=1
          operation=DiagnosticInfo/GetEventExtendedDataRecord, queue-length=1
          operation=DiagnosticInfo/GetEventExtendedDataRecordEx, queue-length=1
          operation=DiagnosticInfo/GetEventFreezeFrameData, queue-length=1
          operation=DiagnosticInfo/GetEventFreezeFrameDataEx, queue-length=1
      EvtInfo_DemEventParameter_ECU5_DTC61: provided-interface=DiagnosticInfo
        provided-com-specs:
          operation=DiagnosticInfo/GetEventStatus, queue-length=1
          operation=DiagnosticInfo/GetEventFailed, queue-length=1
          operation=DiagnosticInfo/GetEventTested, queue-length=1
          operation=DiagnosticInfo/GetDTCOfEvent, queue-length=1
          operation=DiagnosticInfo/GetDebouncingOfEvent, queue-length=1
          operation=DiagnosticInfo/GetFaultDetectionCounter, queue-length=1
          operation=DiagnosticInfo/GetEventExtendedDataRecord, queue-length=1
          operation=DiagnosticInfo/GetEventExtendedDataRecordEx, queue-length=1
          operation=DiagnosticInfo/GetEventFreezeFrameData, queue-length=1
          operation=DiagnosticInfo/GetEventFreezeFrameDataEx, queue-length=1
      EvtInfo_DemEventParameter_ECU5_DTC62: provided-interface=DiagnosticInfo
        provided-com-specs:
          operation=DiagnosticInfo/GetEventStatus, queue-length=1
          operation=DiagnosticInfo/GetEventFailed, queue-length=1
          operation=DiagnosticInfo/GetEventTested, queue-length=1
          operation=DiagnosticInfo/GetDTCOfEvent, queue-length=1
          operation=DiagnosticInfo/GetDebouncingOfEvent, queue-length=1
          operation=DiagnosticInfo/GetFaultDetectionCounter, queue-length=1
          operation=DiagnosticInfo/GetEventExtendedDataRecord, queue-length=1
          operation=DiagnosticInfo/GetEventExtendedDataRecordEx, queue-length=1
          operation=DiagnosticInfo/GetEventFreezeFrameData, queue-length=1
          operation=DiagnosticInfo/GetEventFreezeFrameDataEx, queue-length=1
      EvtInfo_DemEventParameter_ECU5_DTC63: provided-interface=DiagnosticInfo
        provided-com-specs:
          operation=DiagnosticInfo/GetEventStatus, queue-length=1
          operation=DiagnosticInfo/GetEventFailed, queue-length=1
          operation=DiagnosticInfo/GetEventTested, queue-length=1
          operation=DiagnosticInfo/GetDTCOfEvent, queue-length=1
          operation=DiagnosticInfo/GetDebouncingOfEvent, queue-length=1
          operation=DiagnosticInfo/GetFaultDetectionCounter, queue-length=1
          operation=DiagnosticInfo/GetEventExtendedDataRecord, queue-length=1
          operation=DiagnosticInfo/GetEventExtendedDataRecordEx, queue-length=1
          operation=DiagnosticInfo/GetEventFreezeFrameData, queue-length=1
          operation=DiagnosticInfo/GetEventFreezeFrameDataEx, queue-length=1
      EvtInfo_DemEventParameter_ECU5_DTC64: provided-interface=DiagnosticInfo
        provided-com-specs:
          operation=DiagnosticInfo/GetEventStatus, queue-length=1
          operation=DiagnosticInfo/GetEventFailed, queue-length=1
          operation=DiagnosticInfo/GetEventTested, queue-length=1
          operation=DiagnosticInfo/GetDTCOfEvent, queue-length=1
          operation=DiagnosticInfo/GetDebouncingOfEvent, queue-length=1
          operation=DiagnosticInfo/GetFaultDetectionCounter, queue-length=1
          operation=DiagnosticInfo/GetEventExtendedDataRecord, queue-length=1
          operation=DiagnosticInfo/GetEventExtendedDataRecordEx, queue-length=1
          operation=DiagnosticInfo/GetEventFreezeFrameData, queue-length=1
          operation=DiagnosticInfo/GetEventFreezeFrameDataEx, queue-length=1
      EvtInfo_DemEventParameter_ECU5_DTC65: provided-interface=DiagnosticInfo
        provided-com-specs:
          operation=DiagnosticInfo/GetEventStatus, queue-length=1
          operation=DiagnosticInfo/GetEventFailed, queue-length=1
          operation=DiagnosticInfo/GetEventTested, queue-length=1
          operation=DiagnosticInfo/GetDTCOfEvent, queue-length=1
          operation=DiagnosticInfo/GetDebouncingOfEvent, queue-length=1
          operation=DiagnosticInfo/GetFaultDetectionCounter, queue-length=1
          operation=DiagnosticInfo/GetEventExtendedDataRecord, queue-length=1
          operation=DiagnosticInfo/GetEventExtendedDataRecordEx, queue-length=1
          operation=DiagnosticInfo/GetEventFreezeFrameData, queue-length=1
          operation=DiagnosticInfo/GetEventFreezeFrameDataEx, queue-length=1
      EvtInfo_DemEventParameter_ECU5_DTC66: provided-interface=DiagnosticInfo
        provided-com-specs:
          operation=DiagnosticInfo/GetEventStatus, queue-length=1
          operation=DiagnosticInfo/GetEventFailed, queue-length=1
          operation=DiagnosticInfo/GetEventTested, queue-length=1
          operation=DiagnosticInfo/GetDTCOfEvent, queue-length=1
          operation=DiagnosticInfo/GetDebouncingOfEvent, queue-length=1
          operation=DiagnosticInfo/GetFaultDetectionCounter, queue-length=1
          operation=DiagnosticInfo/GetEventExtendedDataRecord, queue-length=1
          operation=DiagnosticInfo/GetEventExtendedDataRecordEx, queue-length=1
          operation=DiagnosticInfo/GetEventFreezeFrameData, queue-length=1
          operation=DiagnosticInfo/GetEventFreezeFrameDataEx, queue-length=1
      EvtInfo_DemEventParameter_ECU5_DTC67: provided-interface=DiagnosticInfo
        provided-com-specs:
          operation=DiagnosticInfo/GetEventStatus, queue-length=1
          operation=DiagnosticInfo/GetEventFailed, queue-length=1
          operation=DiagnosticInfo/GetEventTested, queue-length=1
          operation=DiagnosticInfo/GetDTCOfEvent, queue-length=1
          operation=DiagnosticInfo/GetDebouncingOfEvent, queue-length=1
          operation=DiagnosticInfo/GetFaultDetectionCounter, queue-length=1
          operation=DiagnosticInfo/GetEventExtendedDataRecord, queue-length=1
          operation=DiagnosticInfo/GetEventExtendedDataRecordEx, queue-length=1
          operation=DiagnosticInfo/GetEventFreezeFrameData, queue-length=1
          operation=DiagnosticInfo/GetEventFreezeFrameDataEx, queue-length=1
      EvtInfo_DemEventParameter_ECU5_DTC68: provided-interface=DiagnosticInfo
        provided-com-specs:
          operation=DiagnosticInfo/GetEventStatus, queue-length=1
          operation=DiagnosticInfo/GetEventFailed, queue-length=1
          operation=DiagnosticInfo/GetEventTested, queue-length=1
          operation=DiagnosticInfo/GetDTCOfEvent, queue-length=1
          operation=DiagnosticInfo/GetDebouncingOfEvent, queue-length=1
          operation=DiagnosticInfo/GetFaultDetectionCounter, queue-length=1
          operation=DiagnosticInfo/GetEventExtendedDataRecord, queue-length=1
          operation=DiagnosticInfo/GetEventExtendedDataRecordEx, queue-length=1
          operation=DiagnosticInfo/GetEventFreezeFrameData, queue-length=1
          operation=DiagnosticInfo/GetEventFreezeFrameDataEx, queue-length=1
      EvtInfo_DemEventParameter_ECU5_DTC69: provided-interface=DiagnosticInfo
        provided-com-specs:
          operation=DiagnosticInfo/GetEventStatus, queue-length=1
          operation=DiagnosticInfo/GetEventFailed, queue-length=1
          operation=DiagnosticInfo/GetEventTested, queue-length=1
          operation=DiagnosticInfo/GetDTCOfEvent, queue-length=1
          operation=DiagnosticInfo/GetDebouncingOfEvent, queue-length=1
          operation=DiagnosticInfo/GetFaultDetectionCounter, queue-length=1
          operation=DiagnosticInfo/GetEventExtendedDataRecord, queue-length=1
          operation=DiagnosticInfo/GetEventExtendedDataRecordEx, queue-length=1
          operation=DiagnosticInfo/GetEventFreezeFrameData, queue-length=1
          operation=DiagnosticInfo/GetEventFreezeFrameDataEx, queue-length=1
      EvtInfo_DemEventParameter_ECU5_DTC70: provided-interface=DiagnosticInfo
        provided-com-specs:
          operation=DiagnosticInfo/GetEventStatus, queue-length=1
          operation=DiagnosticInfo/GetEventFailed, queue-length=1
          operation=DiagnosticInfo/GetEventTested, queue-length=1
          operation=DiagnosticInfo/GetDTCOfEvent, queue-length=1
          operation=DiagnosticInfo/GetDebouncingOfEvent, queue-length=1
          operation=DiagnosticInfo/GetFaultDetectionCounter, queue-length=1
          operation=DiagnosticInfo/GetEventExtendedDataRecord, queue-length=1
          operation=DiagnosticInfo/GetEventExtendedDataRecordEx, queue-length=1
          operation=DiagnosticInfo/GetEventFreezeFrameData, queue-length=1
          operation=DiagnosticInfo/GetEventFreezeFrameDataEx, queue-length=1
      EvtInfo_DemEventParameter_ECU5_DTC71: provided-interface=DiagnosticInfo
        provided-com-specs:
          operation=DiagnosticInfo/GetEventStatus, queue-length=1
          operation=DiagnosticInfo/GetEventFailed, queue-length=1
          operation=DiagnosticInfo/GetEventTested, queue-length=1
          operation=DiagnosticInfo/GetDTCOfEvent, queue-length=1
          operation=DiagnosticInfo/GetDebouncingOfEvent, queue-length=1
          operation=DiagnosticInfo/GetFaultDetectionCounter, queue-length=1
          operation=DiagnosticInfo/GetEventExtendedDataRecord, queue-length=1
          operation=DiagnosticInfo/GetEventExtendedDataRecordEx, queue-length=1
          operation=DiagnosticInfo/GetEventFreezeFrameData, queue-length=1
          operation=DiagnosticInfo/GetEventFreezeFrameDataEx, queue-length=1
      EvtInfo_DemEventParameter_ECU5_DTC72: provided-interface=DiagnosticInfo
        provided-com-specs:
          operation=DiagnosticInfo/GetEventStatus, queue-length=1
          operation=DiagnosticInfo/GetEventFailed, queue-length=1
          operation=DiagnosticInfo/GetEventTested, queue-length=1
          operation=DiagnosticInfo/GetDTCOfEvent, queue-length=1
          operation=DiagnosticInfo/GetDebouncingOfEvent, queue-length=1
          operation=DiagnosticInfo/GetFaultDetectionCounter, queue-length=1
          operation=DiagnosticInfo/GetEventExtendedDataRecord, queue-length=1
          operation=DiagnosticInfo/GetEventExtendedDataRecordEx, queue-length=1
          operation=DiagnosticInfo/GetEventFreezeFrameData, queue-length=1
          operation=DiagnosticInfo/GetEventFreezeFrameDataEx, queue-length=1
      EvtInfo_DemEventParameter_ECU5_DTC73: provided-interface=DiagnosticInfo
        provided-com-specs:
          operation=DiagnosticInfo/GetEventStatus, queue-length=1
          operation=DiagnosticInfo/GetEventFailed, queue-length=1
          operation=DiagnosticInfo/GetEventTested, queue-length=1
          operation=DiagnosticInfo/GetDTCOfEvent, queue-length=1
          operation=DiagnosticInfo/GetDebouncingOfEvent, queue-length=1
          operation=DiagnosticInfo/GetFaultDetectionCounter, queue-length=1
          operation=DiagnosticInfo/GetEventExtendedDataRecord, queue-length=1
          operation=DiagnosticInfo/GetEventExtendedDataRecordEx, queue-length=1
          operation=DiagnosticInfo/GetEventFreezeFrameData, queue-length=1
          operation=DiagnosticInfo/GetEventFreezeFrameDataEx, queue-length=1
      EvtInfo_DemEventParameter_ECU5_DTC74: provided-interface=DiagnosticInfo
        provided-com-specs:
          operation=DiagnosticInfo/GetEventStatus, queue-length=1
          operation=DiagnosticInfo/GetEventFailed, queue-length=1
          operation=DiagnosticInfo/GetEventTested, queue-length=1
          operation=DiagnosticInfo/GetDTCOfEvent, queue-length=1
          operation=DiagnosticInfo/GetDebouncingOfEvent, queue-length=1
          operation=DiagnosticInfo/GetFaultDetectionCounter, queue-length=1
          operation=DiagnosticInfo/GetEventExtendedDataRecord, queue-length=1
          operation=DiagnosticInfo/GetEventExtendedDataRecordEx, queue-length=1
          operation=DiagnosticInfo/GetEventFreezeFrameData, queue-length=1
          operation=DiagnosticInfo/GetEventFreezeFrameDataEx, queue-length=1
      EvtInfo_DemEventParameter_ECU5_DTC75: provided-interface=DiagnosticInfo
        provided-com-specs:
          operation=DiagnosticInfo/GetEventStatus, queue-length=1
          operation=DiagnosticInfo/GetEventFailed, queue-length=1
          operation=DiagnosticInfo/GetEventTested, queue-length=1
          operation=DiagnosticInfo/GetDTCOfEvent, queue-length=1
          operation=DiagnosticInfo/GetDebouncingOfEvent, queue-length=1
          operation=DiagnosticInfo/GetFaultDetectionCounter, queue-length=1
          operation=DiagnosticInfo/GetEventExtendedDataRecord, queue-length=1
          operation=DiagnosticInfo/GetEventExtendedDataRecordEx, queue-length=1
          operation=DiagnosticInfo/GetEventFreezeFrameData, queue-length=1
          operation=DiagnosticInfo/GetEventFreezeFrameDataEx, queue-length=1
      EvtInfo_DemEventParameter_ECU5_DTC76: provided-interface=DiagnosticInfo
        provided-com-specs:
          operation=DiagnosticInfo/GetEventStatus, queue-length=1
          operation=DiagnosticInfo/GetEventFailed, queue-length=1
          operation=DiagnosticInfo/GetEventTested, queue-length=1
          operation=DiagnosticInfo/GetDTCOfEvent, queue-length=1
          operation=DiagnosticInfo/GetDebouncingOfEvent, queue-length=1
          operation=DiagnosticInfo/GetFaultDetectionCounter, queue-length=1
          operation=DiagnosticInfo/GetEventExtendedDataRecord, queue-length=1
          operation=DiagnosticInfo/GetEventExtendedDataRecordEx, queue-length=1
          operation=DiagnosticInfo/GetEventFreezeFrameData, queue-length=1
          operation=DiagnosticInfo/GetEventFreezeFrameDataEx, queue-length=1
      EvtInfo_DemEventParameter_ECU5_DTC77: provided-interface=DiagnosticInfo
        provided-com-specs:
          operation=DiagnosticInfo/GetEventStatus, queue-length=1
          operation=DiagnosticInfo/GetEventFailed, queue-length=1
          operation=DiagnosticInfo/GetEventTested, queue-length=1
          operation=DiagnosticInfo/GetDTCOfEvent, queue-length=1
          operation=DiagnosticInfo/GetDebouncingOfEvent, queue-length=1
          operation=DiagnosticInfo/GetFaultDetectionCounter, queue-length=1
          operation=DiagnosticInfo/GetEventExtendedDataRecord, queue-length=1
          operation=DiagnosticInfo/GetEventExtendedDataRecordEx, queue-length=1
          operation=DiagnosticInfo/GetEventFreezeFrameData, queue-length=1
          operation=DiagnosticInfo/GetEventFreezeFrameDataEx, queue-length=1
      EvtInfo_DemEventParameter_ECU5_DTC78: provided-interface=DiagnosticInfo
        provided-com-specs:
          operation=DiagnosticInfo/GetEventStatus, queue-length=1
          operation=DiagnosticInfo/GetEventFailed, queue-length=1
          operation=DiagnosticInfo/GetEventTested, queue-length=1
          operation=DiagnosticInfo/GetDTCOfEvent, queue-length=1
          operation=DiagnosticInfo/GetDebouncingOfEvent, queue-length=1
          operation=DiagnosticInfo/GetFaultDetectionCounter, queue-length=1
          operation=DiagnosticInfo/GetEventExtendedDataRecord, queue-length=1
          operation=DiagnosticInfo/GetEventExtendedDataRecordEx, queue-length=1
          operation=DiagnosticInfo/GetEventFreezeFrameData, queue-length=1
          operation=DiagnosticInfo/GetEventFreezeFrameDataEx, queue-length=1
      EvtInfo_DemEventParameter_ECU5_DTC79: provided-interface=DiagnosticInfo
        provided-com-specs:
          operation=DiagnosticInfo/GetEventStatus, queue-length=1
          operation=DiagnosticInfo/GetEventFailed, queue-length=1
          operation=DiagnosticInfo/GetEventTested, queue-length=1
          operation=DiagnosticInfo/GetDTCOfEvent, queue-length=1
          operation=DiagnosticInfo/GetDebouncingOfEvent, queue-length=1
          operation=DiagnosticInfo/GetFaultDetectionCounter, queue-length=1
          operation=DiagnosticInfo/GetEventExtendedDataRecord, queue-length=1
          operation=DiagnosticInfo/GetEventExtendedDataRecordEx, queue-length=1
          operation=DiagnosticInfo/GetEventFreezeFrameData, queue-length=1
          operation=DiagnosticInfo/GetEventFreezeFrameDataEx, queue-length=1
      EvtInfo_DemEventParameter_ECU5_DTC80: provided-interface=DiagnosticInfo
        provided-com-specs:
          operation=DiagnosticInfo/GetEventStatus, queue-length=1
          operation=DiagnosticInfo/GetEventFailed, queue-length=1
          operation=DiagnosticInfo/GetEventTested, queue-length=1
          operation=DiagnosticInfo/GetDTCOfEvent, queue-length=1
          operation=DiagnosticInfo/GetDebouncingOfEvent, queue-length=1
          operation=DiagnosticInfo/GetFaultDetectionCounter, queue-length=1
          operation=DiagnosticInfo/GetEventExtendedDataRecord, queue-length=1
          operation=DiagnosticInfo/GetEventExtendedDataRecordEx, queue-length=1
          operation=DiagnosticInfo/GetEventFreezeFrameData, queue-length=1
          operation=DiagnosticInfo/GetEventFreezeFrameDataEx, queue-length=1
      EvtInfo_DemEventParameter_ECU5_DTC81: provided-interface=DiagnosticInfo
        provided-com-specs:
          operation=DiagnosticInfo/GetEventStatus, queue-length=1
          operation=DiagnosticInfo/GetEventFailed, queue-length=1
          operation=DiagnosticInfo/GetEventTested, queue-length=1
          operation=DiagnosticInfo/GetDTCOfEvent, queue-length=1
          operation=DiagnosticInfo/GetDebouncingOfEvent, queue-length=1
          operation=DiagnosticInfo/GetFaultDetectionCounter, queue-length=1
          operation=DiagnosticInfo/GetEventExtendedDataRecord, queue-length=1
          operation=DiagnosticInfo/GetEventExtendedDataRecordEx, queue-length=1
          operation=DiagnosticInfo/GetEventFreezeFrameData, queue-length=1
          operation=DiagnosticInfo/GetEventFreezeFrameDataEx, queue-length=1
      EvtInfo_DemEventParameter_ECU5_DTC82: provided-interface=DiagnosticInfo
        provided-com-specs:
          operation=DiagnosticInfo/GetEventStatus, queue-length=1
          operation=DiagnosticInfo/GetEventFailed, queue-length=1
          operation=DiagnosticInfo/GetEventTested, queue-length=1
          operation=DiagnosticInfo/GetDTCOfEvent, queue-length=1
          operation=DiagnosticInfo/GetDebouncingOfEvent, queue-length=1
          operation=DiagnosticInfo/GetFaultDetectionCounter, queue-length=1
          operation=DiagnosticInfo/GetEventExtendedDataRecord, queue-length=1
          operation=DiagnosticInfo/GetEventExtendedDataRecordEx, queue-length=1
          operation=DiagnosticInfo/GetEventFreezeFrameData, queue-length=1
          operation=DiagnosticInfo/GetEventFreezeFrameDataEx, queue-length=1
      EvtInfo_DemEventParameter_ECU5_DTC83: provided-interface=DiagnosticInfo
        provided-com-specs:
          operation=DiagnosticInfo/GetEventStatus, queue-length=1
          operation=DiagnosticInfo/GetEventFailed, queue-length=1
          operation=DiagnosticInfo/GetEventTested, queue-length=1
          operation=DiagnosticInfo/GetDTCOfEvent, queue-length=1
          operation=DiagnosticInfo/GetDebouncingOfEvent, queue-length=1
          operation=DiagnosticInfo/GetFaultDetectionCounter, queue-length=1
          operation=DiagnosticInfo/GetEventExtendedDataRecord, queue-length=1
          operation=DiagnosticInfo/GetEventExtendedDataRecordEx, queue-length=1
          operation=DiagnosticInfo/GetEventFreezeFrameData, queue-length=1
          operation=DiagnosticInfo/GetEventFreezeFrameDataEx, queue-length=1
      EvtInfo_DemEventParameter_ECU5_DTC84: provided-interface=DiagnosticInfo
        provided-com-specs:
          operation=DiagnosticInfo/GetEventStatus, queue-length=1
          operation=DiagnosticInfo/GetEventFailed, queue-length=1
          operation=DiagnosticInfo/GetEventTested, queue-length=1
          operation=DiagnosticInfo/GetDTCOfEvent, queue-length=1
          operation=DiagnosticInfo/GetDebouncingOfEvent, queue-length=1
          operation=DiagnosticInfo/GetFaultDetectionCounter, queue-length=1
          operation=DiagnosticInfo/GetEventExtendedDataRecord, queue-length=1
          operation=DiagnosticInfo/GetEventExtendedDataRecordEx, queue-length=1
          operation=DiagnosticInfo/GetEventFreezeFrameData, queue-length=1
          operation=DiagnosticInfo/GetEventFreezeFrameDataEx, queue-length=1
      EvtInfo_DemEventParameter_ECU5_DTC85: provided-interface=DiagnosticInfo
        provided-com-specs:
          operation=DiagnosticInfo/GetEventStatus, queue-length=1
          operation=DiagnosticInfo/GetEventFailed, queue-length=1
          operation=DiagnosticInfo/GetEventTested, queue-length=1
          operation=DiagnosticInfo/GetDTCOfEvent, queue-length=1
          operation=DiagnosticInfo/GetDebouncingOfEvent, queue-length=1
          operation=DiagnosticInfo/GetFaultDetectionCounter, queue-length=1
          operation=DiagnosticInfo/GetEventExtendedDataRecord, queue-length=1
          operation=DiagnosticInfo/GetEventExtendedDataRecordEx, queue-length=1
          operation=DiagnosticInfo/GetEventFreezeFrameData, queue-length=1
          operation=DiagnosticInfo/GetEventFreezeFrameDataEx, queue-length=1
      EvtInfo_DemEventParameter_ECU5_DTC86: provided-interface=DiagnosticInfo
        provided-com-specs:
          operation=DiagnosticInfo/GetEventStatus, queue-length=1
          operation=DiagnosticInfo/GetEventFailed, queue-length=1
          operation=DiagnosticInfo/GetEventTested, queue-length=1
          operation=DiagnosticInfo/GetDTCOfEvent, queue-length=1
          operation=DiagnosticInfo/GetDebouncingOfEvent, queue-length=1
          operation=DiagnosticInfo/GetFaultDetectionCounter, queue-length=1
          operation=DiagnosticInfo/GetEventExtendedDataRecord, queue-length=1
          operation=DiagnosticInfo/GetEventExtendedDataRecordEx, queue-length=1
          operation=DiagnosticInfo/GetEventFreezeFrameData, queue-length=1
          operation=DiagnosticInfo/GetEventFreezeFrameDataEx, queue-length=1
      EvtInfo_DemEventParameter_ECU5_DTC87: provided-interface=DiagnosticInfo
        provided-com-specs:
          operation=DiagnosticInfo/GetEventStatus, queue-length=1
          operation=DiagnosticInfo/GetEventFailed, queue-length=1
          operation=DiagnosticInfo/GetEventTested, queue-length=1
          operation=DiagnosticInfo/GetDTCOfEvent, queue-length=1
          operation=DiagnosticInfo/GetDebouncingOfEvent, queue-length=1
          operation=DiagnosticInfo/GetFaultDetectionCounter, queue-length=1
          operation=DiagnosticInfo/GetEventExtendedDataRecord, queue-length=1
          operation=DiagnosticInfo/GetEventExtendedDataRecordEx, queue-length=1
          operation=DiagnosticInfo/GetEventFreezeFrameData, queue-length=1
          operation=DiagnosticInfo/GetEventFreezeFrameDataEx, queue-length=1
      EvtInfo_DemEventParameter_ECU5_DTC88: provided-interface=DiagnosticInfo
        provided-com-specs:
          operation=DiagnosticInfo/GetEventStatus, queue-length=1
          operation=DiagnosticInfo/GetEventFailed, queue-length=1
          operation=DiagnosticInfo/GetEventTested, queue-length=1
          operation=DiagnosticInfo/GetDTCOfEvent, queue-length=1
          operation=DiagnosticInfo/GetDebouncingOfEvent, queue-length=1
          operation=DiagnosticInfo/GetFaultDetectionCounter, queue-length=1
          operation=DiagnosticInfo/GetEventExtendedDataRecord, queue-length=1
          operation=DiagnosticInfo/GetEventExtendedDataRecordEx, queue-length=1
          operation=DiagnosticInfo/GetEventFreezeFrameData, queue-length=1
          operation=DiagnosticInfo/GetEventFreezeFrameDataEx, queue-length=1
      EvtInfo_DemEventParameter_ECU5_DTC89: provided-interface=DiagnosticInfo
        provided-com-specs:
          operation=DiagnosticInfo/GetEventStatus, queue-length=1
          operation=DiagnosticInfo/GetEventFailed, queue-length=1
          operation=DiagnosticInfo/GetEventTested, queue-length=1
          operation=DiagnosticInfo/GetDTCOfEvent, queue-length=1
          operation=DiagnosticInfo/GetDebouncingOfEvent, queue-length=1
          operation=DiagnosticInfo/GetFaultDetectionCounter, queue-length=1
          operation=DiagnosticInfo/GetEventExtendedDataRecord, queue-length=1
          operation=DiagnosticInfo/GetEventExtendedDataRecordEx, queue-length=1
          operation=DiagnosticInfo/GetEventFreezeFrameData, queue-length=1
          operation=DiagnosticInfo/GetEventFreezeFrameDataEx, queue-length=1
      EvtInfo_DemEventParameter_ECU5_DTC90: provided-interface=DiagnosticInfo
        provided-com-specs:
          operation=DiagnosticInfo/GetEventStatus, queue-length=1
          operation=DiagnosticInfo/GetEventFailed, queue-length=1
          operation=DiagnosticInfo/GetEventTested, queue-length=1
          operation=DiagnosticInfo/GetDTCOfEvent, queue-length=1
          operation=DiagnosticInfo/GetDebouncingOfEvent, queue-length=1
          operation=DiagnosticInfo/GetFaultDetectionCounter, queue-length=1
          operation=DiagnosticInfo/GetEventExtendedDataRecord, queue-length=1
          operation=DiagnosticInfo/GetEventExtendedDataRecordEx, queue-length=1
          operation=DiagnosticInfo/GetEventFreezeFrameData, queue-length=1
          operation=DiagnosticInfo/GetEventFreezeFrameDataEx, queue-length=1
      EvtInfo_DemEventParameter_ECU5_DTC91: provided-interface=DiagnosticInfo
        provided-com-specs:
          operation=DiagnosticInfo/GetEventStatus, queue-length=1
          operation=DiagnosticInfo/GetEventFailed, queue-length=1
          operation=DiagnosticInfo/GetEventTested, queue-length=1
          operation=DiagnosticInfo/GetDTCOfEvent, queue-length=1
          operation=DiagnosticInfo/GetDebouncingOfEvent, queue-length=1
          operation=DiagnosticInfo/GetFaultDetectionCounter, queue-length=1
          operation=DiagnosticInfo/GetEventExtendedDataRecord, queue-length=1
          operation=DiagnosticInfo/GetEventExtendedDataRecordEx, queue-length=1
          operation=DiagnosticInfo/GetEventFreezeFrameData, queue-length=1
          operation=DiagnosticInfo/GetEventFreezeFrameDataEx, queue-length=1
      EvtInfo_DemEventParameter_ECU5_DTC92: provided-interface=DiagnosticInfo
        provided-com-specs:
          operation=DiagnosticInfo/GetEventStatus, queue-length=1
          operation=DiagnosticInfo/GetEventFailed, queue-length=1
          operation=DiagnosticInfo/GetEventTested, queue-length=1
          operation=DiagnosticInfo/GetDTCOfEvent, queue-length=1
          operation=DiagnosticInfo/GetDebouncingOfEvent, queue-length=1
          operation=DiagnosticInfo/GetFaultDetectionCounter, queue-length=1
          operation=DiagnosticInfo/GetEventExtendedDataRecord, queue-length=1
          operation=DiagnosticInfo/GetEventExtendedDataRecordEx, queue-length=1
          operation=DiagnosticInfo/GetEventFreezeFrameData, queue-length=1
          operation=DiagnosticInfo/GetEventFreezeFrameDataEx, queue-length=1
      EvtInfo_DemEventParameter_ECU5_DTC93: provided-interface=DiagnosticInfo
        provided-com-specs:
          operation=DiagnosticInfo/GetEventStatus, queue-length=1
          operation=DiagnosticInfo/GetEventFailed, queue-length=1
          operation=DiagnosticInfo/GetEventTested, queue-length=1
          operation=DiagnosticInfo/GetDTCOfEvent, queue-length=1
          operation=DiagnosticInfo/GetDebouncingOfEvent, queue-length=1
          operation=DiagnosticInfo/GetFaultDetectionCounter, queue-length=1
          operation=DiagnosticInfo/GetEventExtendedDataRecord, queue-length=1
          operation=DiagnosticInfo/GetEventExtendedDataRecordEx, queue-length=1
          operation=DiagnosticInfo/GetEventFreezeFrameData, queue-length=1
          operation=DiagnosticInfo/GetEventFreezeFrameDataEx, queue-length=1
      EvtInfo_DemEventParameter_ECU5_DTC94: provided-interface=DiagnosticInfo
        provided-com-specs:
          operation=DiagnosticInfo/GetEventStatus, queue-length=1
          operation=DiagnosticInfo/GetEventFailed, queue-length=1
          operation=DiagnosticInfo/GetEventTested, queue-length=1
          operation=DiagnosticInfo/GetDTCOfEvent, queue-length=1
          operation=DiagnosticInfo/GetDebouncingOfEvent, queue-length=1
          operation=DiagnosticInfo/GetFaultDetectionCounter, queue-length=1
          operation=DiagnosticInfo/GetEventExtendedDataRecord, queue-length=1
          operation=DiagnosticInfo/GetEventExtendedDataRecordEx, queue-length=1
          operation=DiagnosticInfo/GetEventFreezeFrameData, queue-length=1
          operation=DiagnosticInfo/GetEventFreezeFrameDataEx, queue-length=1
      EvtInfo_DemEventParameter_ECU5_DTC95: provided-interface=DiagnosticInfo
        provided-com-specs:
          operation=DiagnosticInfo/GetEventStatus, queue-length=1
          operation=DiagnosticInfo/GetEventFailed, queue-length=1
          operation=DiagnosticInfo/GetEventTested, queue-length=1
          operation=DiagnosticInfo/GetDTCOfEvent, queue-length=1
          operation=DiagnosticInfo/GetDebouncingOfEvent, queue-length=1
          operation=DiagnosticInfo/GetFaultDetectionCounter, queue-length=1
          operation=DiagnosticInfo/GetEventExtendedDataRecord, queue-length=1
          operation=DiagnosticInfo/GetEventExtendedDataRecordEx, queue-length=1
          operation=DiagnosticInfo/GetEventFreezeFrameData, queue-length=1
          operation=DiagnosticInfo/GetEventFreezeFrameDataEx, queue-length=1
      EvtInfo_DemEventParameter_ECU5_DTC96: provided-interface=DiagnosticInfo
        provided-com-specs:
          operation=DiagnosticInfo/GetEventStatus, queue-length=1
          operation=DiagnosticInfo/GetEventFailed, queue-length=1
          operation=DiagnosticInfo/GetEventTested, queue-length=1
          operation=DiagnosticInfo/GetDTCOfEvent, queue-length=1
          operation=DiagnosticInfo/GetDebouncingOfEvent, queue-length=1
          operation=DiagnosticInfo/GetFaultDetectionCounter, queue-length=1
          operation=DiagnosticInfo/GetEventExtendedDataRecord, queue-length=1
          operation=DiagnosticInfo/GetEventExtendedDataRecordEx, queue-length=1
          operation=DiagnosticInfo/GetEventFreezeFrameData, queue-length=1
          operation=DiagnosticInfo/GetEventFreezeFrameDataEx, queue-length=1
      EvtInfo_DemEventParameter_ECU5_DTC97: provided-interface=DiagnosticInfo
        provided-com-specs:
          operation=DiagnosticInfo/GetEventStatus, queue-length=1
          operation=DiagnosticInfo/GetEventFailed, queue-length=1
          operation=DiagnosticInfo/GetEventTested, queue-length=1
          operation=DiagnosticInfo/GetDTCOfEvent, queue-length=1
          operation=DiagnosticInfo/GetDebouncingOfEvent, queue-length=1
          operation=DiagnosticInfo/GetFaultDetectionCounter, queue-length=1
          operation=DiagnosticInfo/GetEventExtendedDataRecord, queue-length=1
          operation=DiagnosticInfo/GetEventExtendedDataRecordEx, queue-length=1
          operation=DiagnosticInfo/GetEventFreezeFrameData, queue-length=1
          operation=DiagnosticInfo/GetEventFreezeFrameDataEx, queue-length=1
      EvtInfo_DemEventParameter_ECU5_DTC98: provided-interface=DiagnosticInfo
        provided-com-specs:
          operation=DiagnosticInfo/GetEventStatus, queue-length=1
          operation=DiagnosticInfo/GetEventFailed, queue-length=1
          operation=DiagnosticInfo/GetEventTested, queue-length=1
          operation=DiagnosticInfo/GetDTCOfEvent, queue-length=1
          operation=DiagnosticInfo/GetDebouncingOfEvent, queue-length=1
          operation=DiagnosticInfo/GetFaultDetectionCounter, queue-length=1
          operation=DiagnosticInfo/GetEventExtendedDataRecord, queue-length=1
          operation=DiagnosticInfo/GetEventExtendedDataRecordEx, queue-length=1
          operation=DiagnosticInfo/GetEventFreezeFrameData, queue-length=1
          operation=DiagnosticInfo/GetEventFreezeFrameDataEx, queue-length=1
      EvtInfo_DemEventParameter_ECU5_DTC99: provided-interface=DiagnosticInfo
        provided-com-specs:
          operation=DiagnosticInfo/GetEventStatus, queue-length=1
          operation=DiagnosticInfo/GetEventFailed, queue-length=1
          operation=DiagnosticInfo/GetEventTested, queue-length=1
          operation=DiagnosticInfo/GetDTCOfEvent, queue-length=1
          operation=DiagnosticInfo/GetDebouncingOfEvent, queue-length=1
          operation=DiagnosticInfo/GetFaultDetectionCounter, queue-length=1
          operation=DiagnosticInfo/GetEventExtendedDataRecord, queue-length=1
          operation=DiagnosticInfo/GetEventExtendedDataRecordEx, queue-length=1
          operation=DiagnosticInfo/GetEventFreezeFrameData, queue-length=1
          operation=DiagnosticInfo/GetEventFreezeFrameDataEx, queue-length=1
      GeneralEvtInfo: provided-interface=GeneralDiagnosticInfo
        provided-com-specs:
          operation=GeneralDiagnosticInfo/GetEventStatus, queue-length=1
          operation=GeneralDiagnosticInfo/GetEventFailed, queue-length=1
          operation=GeneralDiagnosticInfo/GetEventTested, queue-length=1
          operation=GeneralDiagnosticInfo/GetDTCOfEvent, queue-length=1
          operation=GeneralDiagnosticInfo/GetDebouncingOfEvent, queue-length=1
          operation=GeneralDiagnosticInfo/GetFaultDetectionCounter, queue-length=1
          operation=GeneralDiagnosticInfo/GetEventExtendedDataRecord, queue-length=1
          operation=GeneralDiagnosticInfo/GetEventFreezeFrameData, queue-length=1
          operation=GeneralDiagnosticInfo/GetEventExtendedDataRecordEx, queue-length=1
          operation=GeneralDiagnosticInfo/GetEventFreezeFrameDataEx, queue-length=1
          operation=GetEventIdCausingLastDetError, queue-length=1
      OpCycle_DemOperationCycle_Power: provided-interface=OperationCycle
        provided-com-specs:
          operation=SetOperationCycleState, queue-length=1
          operation=GetOperationCycleState, queue-length=1
          operation=GetCycleQualified, queue-length=1
          operation=SetCycleQualified, queue-length=1
      OpCycle_DemOperationCycle_Ignition: provided-interface=OperationCycle
        provided-com-specs:
          operation=SetOperationCycleState, queue-length=1
          operation=GetOperationCycleState, queue-length=1
          operation=GetCycleQualified, queue-length=1
          operation=SetCycleQualified, queue-length=1
      OpCycle_WARM_UP: provided-interface=OperationCycle
        provided-com-specs:
          operation=SetOperationCycleState, queue-length=1
          operation=GetOperationCycleState, queue-length=1
          operation=GetCycleQualified, queue-length=1
          operation=SetCycleQualified, queue-length=1
      OpCycle_DEM_OPCYC_WARMUP: provided-interface=OperationCycle
        provided-com-specs:
          operation=SetOperationCycleState, queue-length=1
          operation=GetOperationCycleState, queue-length=1
          operation=GetCycleQualified, queue-length=1
          operation=SetCycleQualified, queue-length=1
      OpCycle_DEM_OPCYC_PFC: provided-interface=OperationCycle
        provided-com-specs:
          operation=SetOperationCycleState, queue-length=1
          operation=GetOperationCycleState, queue-length=1
          operation=GetCycleQualified, queue-length=1
          operation=SetCycleQualified, queue-length=1
      IndStatus_MIL: server-com-spec{operation=GetIndicatorStatus, queue-length=1}, provided-interface=IndicatorStatus
      IndStatus_MIL_Indicator: server-com-spec{operation=GetIndicatorStatus, queue-length=1}, provided-interface=IndicatorStatus
      ControlEventAvailable_DemEventParameter_ECU1_DTC{00..99}: server-com-spec{operation=SetEventAvailable, queue-length=1}, provided-interface=EventAvailable
      ControlEventAvailable_DemEventParameter_ECU2_DTC{00..99}: server-com-spec{operation=SetEventAvailable, queue-length=1}, provided-interface=EventAvailable
      ControlEventAvailable_DemEventParameter_ECU3_DTC{00..99}: server-com-spec{operation=SetEventAvailable, queue-length=1}, provided-interface=EventAvailable
      ControlEventAvailable_DemEventParameter_ECU4_DTC{00..99}: server-com-spec{operation=SetEventAvailable, queue-length=1}, provided-interface=EventAvailable
      ControlEventAvailable_DemEventParameter_ECU5_DTC{00..99}: server-com-spec{operation=SetEventAvailable, queue-length=1}, provided-interface=EventAvailable
      EventStatus_DemEventParameter_ECU1_DTC{00..99}: server-com-spec{operation=SetWIRStatus, queue-length=1}, provided-interface=EventStatus
      EventStatus_DemEventParameter_ECU2_DTC{00..99}: server-com-spec{operation=SetWIRStatus, queue-length=1}, provided-interface=EventStatus
      EventStatus_DemEventParameter_ECU3_DTC{00..99}: server-com-spec{operation=SetWIRStatus, queue-length=1}, provided-interface=EventStatus
      EventStatus_DemEventParameter_ECU4_DTC{00..99}: server-com-spec{operation=SetWIRStatus, queue-length=1}, provided-interface=EventStatus
      EventStatus_DemEventParameter_ECU5_DTC{00..99}: server-com-spec{operation=SetWIRStatus, queue-length=1}, provided-interface=EventStatus
      IUMPRDenominatorCondition_DEM_IUMPR_GENERAL_DENOMINATOR: server-com-spec{operation=SetIUMPRDenCondition, queue-length=1}, provided-interface=IUMPRDenominatorCondition
      IUMPRDenominatorCondition_DEM_IUMPR_DEN_COND_COLDSTART: server-com-spec{operation=SetIUMPRDenCondition, queue-length=1}, provided-interface=IUMPRDenominatorCondition
      IUMPRDenominatorCondition_DEM_IUMPR_DEN_COND_EVAP: server-com-spec{operation=SetIUMPRDenCondition, queue-length=1}, provided-interface=IUMPRDenominatorCondition
      IUMPRDenominatorCondition_DEM_IUMPR_DEN_COND_500MI: server-com-spec{operation=SetIUMPRDenCondition, queue-length=1}, provided-interface=IUMPRDenominatorCondition
      DTRCentralReport_Mid01: server-com-spec{operation=SetDTR, queue-length=1}, provided-interface=DTRCentralReport
    9 x require port:
      DataServices_PID_02: required-interface=DataServices_PID_02
      DataServices_PID_04: required-interface=DataServices_PID_04
      DataServices_PID_05: required-interface=DataServices_PID_05
      DataServices_PID_0C: required-interface=DataServices_PID_0C
      DataServices_PID_0D: required-interface=DataServices_PID_0D
      DataServices_PID_42: required-interface=DataServices_PID_42
      DataServices_PID_49: required-interface=DataServices_PID_49
      DataServices_CS_ExtendedDataRecord_Fault_pending_counter: required-interface=DataServices_CS_ExtendedDataRecord_Fault_pending_counter
      DataServices_CS_ExtendedDataRecord_Aged_counter: required-interface=DataServices_CS_ExtendedDataRecord_Aged_counter
    behavior IntBeh_Dem: handle-termination-and-restart=NO-SUPPORT, included-data-type-set=data-type=[Dem_DTCFormatType, Dem_DTCOriginType, Dem_EventIdType, Dem_UdsStatusByteType, Dem_EventStatusType, Dem_DebugDataType, Dem_IndicatorIdType, Dem_IndicatorStatusType, Dem_InitMonitorReasonType, Dem_MaxDataValueType, Dem_OperationCycleIdType, Dem_OperationCycleStateType, Dem_DebouncingStateType, Dem_DebounceResetStatusType, Dem_IumprDenomCondIdType, Dem_IumprDenomCondStatusType]
      9538 x operation invoked event:
        Ev_SES_DemEventParameter_ECU1_DTC00: start-on-event=SetEventStatus, operation=Event_DemEventParameter_ECU1_DTC00.SetEventStatus
        Ev_SESWE_DemEventParameter_ECU1_DTC00: start-on-event=SetEventStatusWithEnvdata, operation=Event_DemEventParameter_ECU1_DTC00.SetEventStatusWithEnvdata
        Ev_RES_DemEventParameter_ECU1_DTC00: start-on-event=ResetEventStatus, operation=Event_DemEventParameter_ECU1_DTC00.ResetEventStatus
        Ev_CPFF_DemEventParameter_ECU1_DTC00: start-on-event=ClearPrestoredFreezeFrame, operation=Event_DemEventParameter_ECU1_DTC00.ClearPrestoredFreezeFrame
        Ev_PFF_DemEventParameter_ECU1_DTC00: start-on-event=PrestoreFreezeFrame, operation=Event_DemEventParameter_ECU1_DTC00.PrestoreFreezeFrame
        Ev_RDS_DemEventParameter_ECU1_DTC00: start-on-event=ResetEventDebounceStatus, operation=Event_DemEventParameter_ECU1_DTC00.ResetEventDebounceStatus
        Ev_SES_DemEventParameter_ECU1_DTC01: start-on-event=SetEventStatus, operation=Event_DemEventParameter_ECU1_DTC01.SetEventStatus
        Ev_SESWE_DemEventParameter_ECU1_DTC01: start-on-event=SetEventStatusWithEnvdata, operation=Event_DemEventParameter_ECU1_DTC01.SetEventStatusWithEnvdata
        Ev_RES_DemEventParameter_ECU1_DTC01: start-on-event=ResetEventStatus, operation=Event_DemEventParameter_ECU1_DTC01.ResetEventStatus
        Ev_CPFF_DemEventParameter_ECU1_DTC01: start-on-event=ClearPrestoredFreezeFrame, operation=Event_DemEventParameter_ECU1_DTC01.ClearPrestoredFreezeFrame
        Ev_PFF_DemEventParameter_ECU1_DTC01: start-on-event=PrestoreFreezeFrame, operation=Event_DemEventParameter_ECU1_DTC01.PrestoreFreezeFrame
        Ev_RDS_DemEventParameter_ECU1_DTC01: start-on-event=ResetEventDebounceStatus, operation=Event_DemEventParameter_ECU1_DTC01.ResetEventDebounceStatus
        Ev_SES_DemEventParameter_ECU1_DTC02: start-on-event=SetEventStatus, operation=Event_DemEventParameter_ECU1_DTC02.SetEventStatus
        Ev_SESWE_DemEventParameter_ECU1_DTC02: start-on-event=SetEventStatusWithEnvdata, operation=Event_DemEventParameter_ECU1_DTC02.SetEventStatusWithEnvdata
        Ev_RES_DemEventParameter_ECU1_DTC02: start-on-event=ResetEventStatus, operation=Event_DemEventParameter_ECU1_DTC02.ResetEventStatus
        Ev_CPFF_DemEventParameter_ECU1_DTC02: start-on-event=ClearPrestoredFreezeFrame, operation=Event_DemEventParameter_ECU1_DTC02.ClearPrestoredFreezeFrame
        Ev_PFF_DemEventParameter_ECU1_DTC02: start-on-event=PrestoreFreezeFrame, operation=Event_DemEventParameter_ECU1_DTC02.PrestoreFreezeFrame
        Ev_RDS_DemEventParameter_ECU1_DTC02: start-on-event=ResetEventDebounceStatus, operation=Event_DemEventParameter_ECU1_DTC02.ResetEventDebounceStatus
        Ev_SES_DemEventParameter_ECU1_DTC03: start-on-event=SetEventStatus, operation=Event_DemEventParameter_ECU1_DTC03.SetEventStatus
        Ev_SESWE_DemEventParameter_ECU1_DTC03: start-on-event=SetEventStatusWithEnvdata, operation=Event_DemEventParameter_ECU1_DTC03.SetEventStatusWithEnvdata
        Ev_RES_DemEventParameter_ECU1_DTC03: start-on-event=ResetEventStatus, operation=Event_DemEventParameter_ECU1_DTC03.ResetEventStatus
        Ev_CPFF_DemEventParameter_ECU1_DTC03: start-on-event=ClearPrestoredFreezeFrame, operation=Event_DemEventParameter_ECU1_DTC03.ClearPrestoredFreezeFrame
        Ev_PFF_DemEventParameter_ECU1_DTC03: start-on-event=PrestoreFreezeFrame, operation=Event_DemEventParameter_ECU1_DTC03.PrestoreFreezeFrame
        Ev_RDS_DemEventParameter_ECU1_DTC03: start-on-event=ResetEventDebounceStatus, operation=Event_DemEventParameter_ECU1_DTC03.ResetEventDebounceStatus
        Ev_SES_DemEventParameter_ECU1_DTC04: start-on-event=SetEventStatus, operation=Event_DemEventParameter_ECU1_DTC04.SetEventStatus
        Ev_SESWE_DemEventParameter_ECU1_DTC04: start-on-event=SetEventStatusWithEnvdata, operation=Event_DemEventParameter_ECU1_DTC04.SetEventStatusWithEnvdata
        Ev_RES_DemEventParameter_ECU1_DTC04: start-on-event=ResetEventStatus, operation=Event_DemEventParameter_ECU1_DTC04.ResetEventStatus
        Ev_CPFF_DemEventParameter_ECU1_DTC04: start-on-event=ClearPrestoredFreezeFrame, operation=Event_DemEventParameter_ECU1_DTC04.ClearPrestoredFreezeFrame
        Ev_PFF_DemEventParameter_ECU1_DTC04: start-on-event=PrestoreFreezeFrame, operation=Event_DemEventParameter_ECU1_DTC04.PrestoreFreezeFrame
        Ev_RDS_DemEventParameter_ECU1_DTC04: start-on-event=ResetEventDebounceStatus, operation=Event_DemEventParameter_ECU1_DTC04.ResetEventDebounceStatus
        Ev_SES_DemEventParameter_ECU1_DTC05: start-on-event=SetEventStatus, operation=Event_DemEventParameter_ECU1_DTC05.SetEventStatus
        Ev_SESWE_DemEventParameter_ECU1_DTC05: start-on-event=SetEventStatusWithEnvdata, operation=Event_DemEventParameter_ECU1_DTC05.SetEventStatusWithEnvdata
        Ev_RES_DemEventParameter_ECU1_DTC05: start-on-event=ResetEventStatus, operation=Event_DemEventParameter_ECU1_DTC05.ResetEventStatus
        Ev_CPFF_DemEventParameter_ECU1_DTC05: start-on-event=ClearPrestoredFreezeFrame, operation=Event_DemEventParameter_ECU1_DTC05.ClearPrestoredFreezeFrame
        Ev_PFF_DemEventParameter_ECU1_DTC05: start-on-event=PrestoreFreezeFrame, operation=Event_DemEventParameter_ECU1_DTC05.PrestoreFreezeFrame
        Ev_RDS_DemEventParameter_ECU1_DTC05: start-on-event=ResetEventDebounceStatus, operation=Event_DemEventParameter_ECU1_DTC05.ResetEventDebounceStatus
        Ev_SES_DemEventParameter_ECU1_DTC06: start-on-event=SetEventStatus, operation=Event_DemEventParameter_ECU1_DTC06.SetEventStatus
        Ev_SESWE_DemEventParameter_ECU1_DTC06: start-on-event=SetEventStatusWithEnvdata, operation=Event_DemEventParameter_ECU1_DTC06.SetEventStatusWithEnvdata
        Ev_RES_DemEventParameter_ECU1_DTC06: start-on-event=ResetEventStatus, operation=Event_DemEventParameter_ECU1_DTC06.ResetEventStatus
        Ev_CPFF_DemEventParameter_ECU1_DTC06: start-on-event=ClearPrestoredFreezeFrame, operation=Event_DemEventParameter_ECU1_DTC06.ClearPrestoredFreezeFrame
        Ev_PFF_DemEventParameter_ECU1_DTC06: start-on-event=PrestoreFreezeFrame, operation=Event_DemEventParameter_ECU1_DTC06.PrestoreFreezeFrame
        Ev_RDS_DemEventParameter_ECU1_DTC06: start-on-event=ResetEventDebounceStatus, operation=Event_DemEventParameter_ECU1_DTC06.ResetEventDebounceStatus
        Ev_SES_DemEventParameter_ECU1_DTC07: start-on-event=SetEventStatus, operation=Event_DemEventParameter_ECU1_DTC07.SetEventStatus
        Ev_SESWE_DemEventParameter_ECU1_DTC07: start-on-event=SetEventStatusWithEnvdata, operation=Event_DemEventParameter_ECU1_DTC07.SetEventStatusWithEnvdata
        Ev_RES_DemEventParameter_ECU1_DTC07: start-on-event=ResetEventStatus, operation=Event_DemEventParameter_ECU1_DTC07.ResetEventStatus
        Ev_CPFF_DemEventParameter_ECU1_DTC07: start-on-event=ClearPrestoredFreezeFrame, operation=Event_DemEventParameter_ECU1_DTC07.ClearPrestoredFreezeFrame
        Ev_PFF_DemEventParameter_ECU1_DTC07: start-on-event=PrestoreFreezeFrame, operation=Event_DemEventParameter_ECU1_DTC07.PrestoreFreezeFrame
        Ev_RDS_DemEventParameter_ECU1_DTC07: start-on-event=ResetEventDebounceStatus, operation=Event_DemEventParameter_ECU1_DTC07.ResetEventDebounceStatus
        Ev_SES_DemEventParameter_ECU1_DTC08: start-on-event=SetEventStatus, operation=Event_DemEventParameter_ECU1_DTC08.SetEventStatus
        Ev_SESWE_DemEventParameter_ECU1_DTC08: start-on-event=SetEventStatusWithEnvdata, operation=Event_DemEventParameter_ECU1_DTC08.SetEventStatusWithEnvdata
        Ev_RES_DemEventParameter_ECU1_DTC08: start-on-event=ResetEventStatus, operation=Event_DemEventParameter_ECU1_DTC08.ResetEventStatus
        Ev_CPFF_DemEventParameter_ECU1_DTC08: start-on-event=ClearPrestoredFreezeFrame, operation=Event_DemEventParameter_ECU1_DTC08.ClearPrestoredFreezeFrame
        Ev_PFF_DemEventParameter_ECU1_DTC08: start-on-event=PrestoreFreezeFrame, operation=Event_DemEventParameter_ECU1_DTC08.PrestoreFreezeFrame
        Ev_RDS_DemEventParameter_ECU1_DTC08: start-on-event=ResetEventDebounceStatus, operation=Event_DemEventParameter_ECU1_DTC08.ResetEventDebounceStatus
        Ev_SES_DemEventParameter_ECU1_DTC09: start-on-event=SetEventStatus, operation=Event_DemEventParameter_ECU1_DTC09.SetEventStatus
        Ev_SESWE_DemEventParameter_ECU1_DTC09: start-on-event=SetEventStatusWithEnvdata, operation=Event_DemEventParameter_ECU1_DTC09.SetEventStatusWithEnvdata
        Ev_RES_DemEventParameter_ECU1_DTC09: start-on-event=ResetEventStatus, operation=Event_DemEventParameter_ECU1_DTC09.ResetEventStatus
        Ev_CPFF_DemEventParameter_ECU1_DTC09: start-on-event=ClearPrestoredFreezeFrame, operation=Event_DemEventParameter_ECU1_DTC09.ClearPrestoredFreezeFrame
        Ev_PFF_DemEventParameter_ECU1_DTC09: start-on-event=PrestoreFreezeFrame, operation=Event_DemEventParameter_ECU1_DTC09.PrestoreFreezeFrame
        Ev_RDS_DemEventParameter_ECU1_DTC09: start-on-event=ResetEventDebounceStatus, operation=Event_DemEventParameter_ECU1_DTC09.ResetEventDebounceStatus
        Ev_SES_DemEventParameter_ECU1_DTC10: start-on-event=SetEventStatus, operation=Event_DemEventParameter_ECU1_DTC10.SetEventStatus
        Ev_SESWE_DemEventParameter_ECU1_DTC10: start-on-event=SetEventStatusWithEnvdata, operation=Event_DemEventParameter_ECU1_DTC10.SetEventStatusWithEnvdata
        Ev_RES_DemEventParameter_ECU1_DTC10: start-on-event=ResetEventStatus, operation=Event_DemEventParameter_ECU1_DTC10.ResetEventStatus
        Ev_CPFF_DemEventParameter_ECU1_DTC10: start-on-event=ClearPrestoredFreezeFrame, operation=Event_DemEventParameter_ECU1_DTC10.ClearPrestoredFreezeFrame
        Ev_PFF_DemEventParameter_ECU1_DTC10: start-on-event=PrestoreFreezeFrame, operation=Event_DemEventParameter_ECU1_DTC10.PrestoreFreezeFrame
        Ev_RDS_DemEventParameter_ECU1_DTC10: start-on-event=ResetEventDebounceStatus, operation=Event_DemEventParameter_ECU1_DTC10.ResetEventDebounceStatus
        Ev_SES_DemEventParameter_ECU1_DTC11: start-on-event=SetEventStatus, operation=Event_DemEventParameter_ECU1_DTC11.SetEventStatus
        Ev_SESWE_DemEventParameter_ECU1_DTC11: start-on-event=SetEventStatusWithEnvdata, operation=Event_DemEventParameter_ECU1_DTC11.SetEventStatusWithEnvdata
        Ev_RES_DemEventParameter_ECU1_DTC11: start-on-event=ResetEventStatus, operation=Event_DemEventParameter_ECU1_DTC11.ResetEventStatus
        Ev_CPFF_DemEventParameter_ECU1_DTC11: start-on-event=ClearPrestoredFreezeFrame, operation=Event_DemEventParameter_ECU1_DTC11.ClearPrestoredFreezeFrame
        Ev_PFF_DemEventParameter_ECU1_DTC11: start-on-event=PrestoreFreezeFrame, operation=Event_DemEventParameter_ECU1_DTC11.PrestoreFreezeFrame
        Ev_RDS_DemEventParameter_ECU1_DTC11: start-on-event=ResetEventDebounceStatus, operation=Event_DemEventParameter_ECU1_DTC11.ResetEventDebounceStatus
        Ev_SES_DemEventParameter_ECU1_DTC12: start-on-event=SetEventStatus, operation=Event_DemEventParameter_ECU1_DTC12.SetEventStatus
        Ev_SESWE_DemEventParameter_ECU1_DTC12: start-on-event=SetEventStatusWithEnvdata, operation=Event_DemEventParameter_ECU1_DTC12.SetEventStatusWithEnvdata
        Ev_RES_DemEventParameter_ECU1_DTC12: start-on-event=ResetEventStatus, operation=Event_DemEventParameter_ECU1_DTC12.ResetEventStatus
        Ev_CPFF_DemEventParameter_ECU1_DTC12: start-on-event=ClearPrestoredFreezeFrame, operation=Event_DemEventParameter_ECU1_DTC12.ClearPrestoredFreezeFrame
        Ev_PFF_DemEventParameter_ECU1_DTC12: start-on-event=PrestoreFreezeFrame, operation=Event_DemEventParameter_ECU1_DTC12.PrestoreFreezeFrame
        Ev_RDS_DemEventParameter_ECU1_DTC12: start-on-event=ResetEventDebounceStatus, operation=Event_DemEventParameter_ECU1_DTC12.ResetEventDebounceStatus
        Ev_SES_DemEventParameter_ECU1_DTC13: start-on-event=SetEventStatus, operation=Event_DemEventParameter_ECU1_DTC13.SetEventStatus
        Ev_SESWE_DemEventParameter_ECU1_DTC13: start-on-event=SetEventStatusWithEnvdata, operation=Event_DemEventParameter_ECU1_DTC13.SetEventStatusWithEnvdata
        Ev_RES_DemEventParameter_ECU1_DTC13: start-on-event=ResetEventStatus, operation=Event_DemEventParameter_ECU1_DTC13.ResetEventStatus
        Ev_CPFF_DemEventParameter_ECU1_DTC13: start-on-event=ClearPrestoredFreezeFrame, operation=Event_DemEventParameter_ECU1_DTC13.ClearPrestoredFreezeFrame
        Ev_PFF_DemEventParameter_ECU1_DTC13: start-on-event=PrestoreFreezeFrame, operation=Event_DemEventParameter_ECU1_DTC13.PrestoreFreezeFrame
        Ev_RDS_DemEventParameter_ECU1_DTC13: start-on-event=ResetEventDebounceStatus, operation=Event_DemEventParameter_ECU1_DTC13.ResetEventDebounceStatus
        Ev_SES_DemEventParameter_ECU1_DTC14: start-on-event=SetEventStatus, operation=Event_DemEventParameter_ECU1_DTC14.SetEventStatus
        Ev_SESWE_DemEventParameter_ECU1_DTC14: start-on-event=SetEventStatusWithEnvdata, operation=Event_DemEventParameter_ECU1_DTC14.SetEventStatusWithEnvdata
        Ev_RES_DemEventParameter_ECU1_DTC14: start-on-event=ResetEventStatus, operation=Event_DemEventParameter_ECU1_DTC14.ResetEventStatus
        Ev_CPFF_DemEventParameter_ECU1_DTC14: start-on-event=ClearPrestoredFreezeFrame, operation=Event_DemEventParameter_ECU1_DTC14.ClearPrestoredFreezeFrame
        Ev_PFF_DemEventParameter_ECU1_DTC14: start-on-event=PrestoreFreezeFrame, operation=Event_DemEventParameter_ECU1_DTC14.PrestoreFreezeFrame
        Ev_RDS_DemEventParameter_ECU1_DTC14: start-on-event=ResetEventDebounceStatus, operation=Event_DemEventParameter_ECU1_DTC14.ResetEventDebounceStatus
        Ev_SES_DemEventParameter_ECU1_DTC15: start-on-event=SetEventStatus, operation=Event_DemEventParameter_ECU1_DTC15.SetEventStatus
        Ev_SESWE_DemEventParameter_ECU1_DTC15: start-on-event=SetEventStatusWithEnvdata, operation=Event_DemEventParameter_ECU1_DTC15.SetEventStatusWithEnvdata
        Ev_RES_DemEventParameter_ECU1_DTC15: start-on-event=ResetEventStatus, operation=Event_DemEventParameter_ECU1_DTC15.ResetEventStatus
        Ev_CPFF_DemEventParameter_ECU1_DTC15: start-on-event=ClearPrestoredFreezeFrame, operation=Event_DemEventParameter_ECU1_DTC15.ClearPrestoredFreezeFrame
        Ev_PFF_DemEventParameter_ECU1_DTC15: start-on-event=PrestoreFreezeFrame, operation=Event_DemEventParameter_ECU1_DTC15.PrestoreFreezeFrame
        Ev_RDS_DemEventParameter_ECU1_DTC15: start-on-event=ResetEventDebounceStatus, operation=Event_DemEventParameter_ECU1_DTC15.ResetEventDebounceStatus
        Ev_SES_DemEventParameter_ECU1_DTC16: start-on-event=SetEventStatus, operation=Event_DemEventParameter_ECU1_DTC16.SetEventStatus
        Ev_SESWE_DemEventParameter_ECU1_DTC16: start-on-event=SetEventStatusWithEnvdata, operation=Event_DemEventParameter_ECU1_DTC16.SetEventStatusWithEnvdata
        Ev_RES_DemEventParameter_ECU1_DTC16: start-on-event=ResetEventStatus, operation=Event_DemEventParameter_ECU1_DTC16.ResetEventStatus
        Ev_CPFF_DemEventParameter_ECU1_DTC16: start-on-event=ClearPrestoredFreezeFrame, operation=Event_DemEventParameter_ECU1_DTC16.ClearPrestoredFreezeFrame
        Ev_PFF_DemEventParameter_ECU1_DTC16: start-on-event=PrestoreFreezeFrame, operation=Event_DemEventParameter_ECU1_DTC16.PrestoreFreezeFrame
        Ev_RDS_DemEventParameter_ECU1_DTC16: start-on-event=ResetEventDebounceStatus, operation=Event_DemEventParameter_ECU1_DTC16.ResetEventDebounceStatus
        Ev_SES_DemEventParameter_ECU1_DTC17: start-on-event=SetEventStatus, operation=Event_DemEventParameter_ECU1_DTC17.SetEventStatus
        Ev_SESWE_DemEventParameter_ECU1_DTC17: start-on-event=SetEventStatusWithEnvdata, operation=Event_DemEventParameter_ECU1_DTC17.SetEventStatusWithEnvdata
        Ev_RES_DemEventParameter_ECU1_DTC17: start-on-event=ResetEventStatus, operation=Event_DemEventParameter_ECU1_DTC17.ResetEventStatus
        Ev_CPFF_DemEventParameter_ECU1_DTC17: start-on-event=ClearPrestoredFreezeFrame, operation=Event_DemEventParameter_ECU1_DTC17.ClearPrestoredFreezeFrame
        Ev_PFF_DemEventParameter_ECU1_DTC17: start-on-event=PrestoreFreezeFrame, operation=Event_DemEventParameter_ECU1_DTC17.PrestoreFreezeFrame
        Ev_RDS_DemEventParameter_ECU1_DTC17: start-on-event=ResetEventDebounceStatus, operation=Event_DemEventParameter_ECU1_DTC17.ResetEventDebounceStatus
        Ev_SES_DemEventParameter_ECU1_DTC18: start-on-event=SetEventStatus, operation=Event_DemEventParameter_ECU1_DTC18.SetEventStatus
        Ev_SESWE_DemEventParameter_ECU1_DTC18: start-on-event=SetEventStatusWithEnvdata, operation=Event_DemEventParameter_ECU1_DTC18.SetEventStatusWithEnvdata
        Ev_RES_DemEventParameter_ECU1_DTC18: start-on-event=ResetEventStatus, operation=Event_DemEventParameter_ECU1_DTC18.ResetEventStatus
        Ev_CPFF_DemEventParameter_ECU1_DTC18: start-on-event=ClearPrestoredFreezeFrame, operation=Event_DemEventParameter_ECU1_DTC18.ClearPrestoredFreezeFrame
        Ev_PFF_DemEventParameter_ECU1_DTC18: start-on-event=PrestoreFreezeFrame, operation=Event_DemEventParameter_ECU1_DTC18.PrestoreFreezeFrame
        Ev_RDS_DemEventParameter_ECU1_DTC18: start-on-event=ResetEventDebounceStatus, operation=Event_DemEventParameter_ECU1_DTC18.ResetEventDebounceStatus
        Ev_SES_DemEventParameter_ECU1_DTC19: start-on-event=SetEventStatus, operation=Event_DemEventParameter_ECU1_DTC19.SetEventStatus
        Ev_SESWE_DemEventParameter_ECU1_DTC19: start-on-event=SetEventStatusWithEnvdata, operation=Event_DemEventParameter_ECU1_DTC19.SetEventStatusWithEnvdata
        Ev_RES_DemEventParameter_ECU1_DTC19: start-on-event=ResetEventStatus, operation=Event_DemEventParameter_ECU1_DTC19.ResetEventStatus
        Ev_CPFF_DemEventParameter_ECU1_DTC19: start-on-event=ClearPrestoredFreezeFrame, operation=Event_DemEventParameter_ECU1_DTC19.ClearPrestoredFreezeFrame
        Ev_PFF_DemEventParameter_ECU1_DTC19: start-on-event=PrestoreFreezeFrame, operation=Event_DemEventParameter_ECU1_DTC19.PrestoreFreezeFrame
        Ev_RDS_DemEventParameter_ECU1_DTC19: start-on-event=ResetEventDebounceStatus, operation=Event_DemEventParameter_ECU1_DTC19.ResetEventDebounceStatus
        Ev_SES_DemEventParameter_ECU1_DTC20: start-on-event=SetEventStatus, operation=Event_DemEventParameter_ECU1_DTC20.SetEventStatus
        Ev_SESWE_DemEventParameter_ECU1_DTC20: start-on-event=SetEventStatusWithEnvdata, operation=Event_DemEventParameter_ECU1_DTC20.SetEventStatusWithEnvdata
        Ev_RES_DemEventParameter_ECU1_DTC20: start-on-event=ResetEventStatus, operation=Event_DemEventParameter_ECU1_DTC20.ResetEventStatus
        Ev_CPFF_DemEventParameter_ECU1_DTC20: start-on-event=ClearPrestoredFreezeFrame, operation=Event_DemEventParameter_ECU1_DTC20.ClearPrestoredFreezeFrame
        Ev_PFF_DemEventParameter_ECU1_DTC20: start-on-event=PrestoreFreezeFrame, operation=Event_DemEventParameter_ECU1_DTC20.PrestoreFreezeFrame
        Ev_RDS_DemEventParameter_ECU1_DTC20: start-on-event=ResetEventDebounceStatus, operation=Event_DemEventParameter_ECU1_DTC20.ResetEventDebounceStatus
        Ev_SES_DemEventParameter_ECU1_DTC21: start-on-event=SetEventStatus, operation=Event_DemEventParameter_ECU1_DTC21.SetEventStatus
        Ev_SESWE_DemEventParameter_ECU1_DTC21: start-on-event=SetEventStatusWithEnvdata, operation=Event_DemEventParameter_ECU1_DTC21.SetEventStatusWithEnvdata
        Ev_RES_DemEventParameter_ECU1_DTC21: start-on-event=ResetEventStatus, operation=Event_DemEventParameter_ECU1_DTC21.ResetEventStatus
        Ev_CPFF_DemEventParameter_ECU1_DTC21: start-on-event=ClearPrestoredFreezeFrame, operation=Event_DemEventParameter_ECU1_DTC21.ClearPrestoredFreezeFrame
        Ev_PFF_DemEventParameter_ECU1_DTC21: start-on-event=PrestoreFreezeFrame, operation=Event_DemEventParameter_ECU1_DTC21.PrestoreFreezeFrame
        Ev_RDS_DemEventParameter_ECU1_DTC21: start-on-event=ResetEventDebounceStatus, operation=Event_DemEventParameter_ECU1_DTC21.ResetEventDebounceStatus
        Ev_SES_DemEventParameter_ECU1_DTC22: start-on-event=SetEventStatus, operation=Event_DemEventParameter_ECU1_DTC22.SetEventStatus
        Ev_SESWE_DemEventParameter_ECU1_DTC22: start-on-event=SetEventStatusWithEnvdata, operation=Event_DemEventParameter_ECU1_DTC22.SetEventStatusWithEnvdata
        Ev_RES_DemEventParameter_ECU1_DTC22: start-on-event=ResetEventStatus, operation=Event_DemEventParameter_ECU1_DTC22.ResetEventStatus
        Ev_CPFF_DemEventParameter_ECU1_DTC22: start-on-event=ClearPrestoredFreezeFrame, operation=Event_DemEventParameter_ECU1_DTC22.ClearPrestoredFreezeFrame
        Ev_PFF_DemEventParameter_ECU1_DTC22: start-on-event=PrestoreFreezeFrame, operation=Event_DemEventParameter_ECU1_DTC22.PrestoreFreezeFrame
        Ev_RDS_DemEventParameter_ECU1_DTC22: start-on-event=ResetEventDebounceStatus, operation=Event_DemEventParameter_ECU1_DTC22.ResetEventDebounceStatus
        Ev_SES_DemEventParameter_ECU1_DTC23: start-on-event=SetEventStatus, operation=Event_DemEventParameter_ECU1_DTC23.SetEventStatus
        Ev_SESWE_DemEventParameter_ECU1_DTC23: start-on-event=SetEventStatusWithEnvdata, operation=Event_DemEventParameter_ECU1_DTC23.SetEventStatusWithEnvdata
        Ev_RES_DemEventParameter_ECU1_DTC23: start-on-event=ResetEventStatus, operation=Event_DemEventParameter_ECU1_DTC23.ResetEventStatus
        Ev_CPFF_DemEventParameter_ECU1_DTC23: start-on-event=ClearPrestoredFreezeFrame, operation=Event_DemEventParameter_ECU1_DTC23.ClearPrestoredFreezeFrame
        Ev_PFF_DemEventParameter_ECU1_DTC23: start-on-event=PrestoreFreezeFrame, operation=Event_DemEventParameter_ECU1_DTC23.PrestoreFreezeFrame
        Ev_RDS_DemEventParameter_ECU1_DTC23: start-on-event=ResetEventDebounceStatus, operation=Event_DemEventParameter_ECU1_DTC23.ResetEventDebounceStatus
        Ev_SES_DemEventParameter_ECU1_DTC24: start-on-event=SetEventStatus, operation=Event_DemEventParameter_ECU1_DTC24.SetEventStatus
        Ev_SESWE_DemEventParameter_ECU1_DTC24: start-on-event=SetEventStatusWithEnvdata, operation=Event_DemEventParameter_ECU1_DTC24.SetEventStatusWithEnvdata
        Ev_RES_DemEventParameter_ECU1_DTC24: start-on-event=ResetEventStatus, operation=Event_DemEventParameter_ECU1_DTC24.ResetEventStatus
        Ev_CPFF_DemEventParameter_ECU1_DTC24: start-on-event=ClearPrestoredFreezeFrame, operation=Event_DemEventParameter_ECU1_DTC24.ClearPrestoredFreezeFrame
        Ev_PFF_DemEventParameter_ECU1_DTC24: start-on-event=PrestoreFreezeFrame, operation=Event_DemEventParameter_ECU1_DTC24.PrestoreFreezeFrame
        Ev_RDS_DemEventParameter_ECU1_DTC24: start-on-event=ResetEventDebounceStatus, operation=Event_DemEventParameter_ECU1_DTC24.ResetEventDebounceStatus
        Ev_SES_DemEventParameter_ECU1_DTC25: start-on-event=SetEventStatus, operation=Event_DemEventParameter_ECU1_DTC25.SetEventStatus
        Ev_SESWE_DemEventParameter_ECU1_DTC25: start-on-event=SetEventStatusWithEnvdata, operation=Event_DemEventParameter_ECU1_DTC25.SetEventStatusWithEnvdata
        Ev_RES_DemEventParameter_ECU1_DTC25: start-on-event=ResetEventStatus, operation=Event_DemEventParameter_ECU1_DTC25.ResetEventStatus
        Ev_CPFF_DemEventParameter_ECU1_DTC25: start-on-event=ClearPrestoredFreezeFrame, operation=Event_DemEventParameter_ECU1_DTC25.ClearPrestoredFreezeFrame
        Ev_PFF_DemEventParameter_ECU1_DTC25: start-on-event=PrestoreFreezeFrame, operation=Event_DemEventParameter_ECU1_DTC25.PrestoreFreezeFrame
        Ev_RDS_DemEventParameter_ECU1_DTC25: start-on-event=ResetEventDebounceStatus, operation=Event_DemEventParameter_ECU1_DTC25.ResetEventDebounceStatus
        Ev_SES_DemEventParameter_ECU1_DTC26: start-on-event=SetEventStatus, operation=Event_DemEventParameter_ECU1_DTC26.SetEventStatus
        Ev_SESWE_DemEventParameter_ECU1_DTC26: start-on-event=SetEventStatusWithEnvdata, operation=Event_DemEventParameter_ECU1_DTC26.SetEventStatusWithEnvdata
        Ev_RES_DemEventParameter_ECU1_DTC26: start-on-event=ResetEventStatus, operation=Event_DemEventParameter_ECU1_DTC26.ResetEventStatus
        Ev_CPFF_DemEventParameter_ECU1_DTC26: start-on-event=ClearPrestoredFreezeFrame, operation=Event_DemEventParameter_ECU1_DTC26.ClearPrestoredFreezeFrame
        Ev_PFF_DemEventParameter_ECU1_DTC26: start-on-event=PrestoreFreezeFrame, operation=Event_DemEventParameter_ECU1_DTC26.PrestoreFreezeFrame
        Ev_RDS_DemEventParameter_ECU1_DTC26: start-on-event=ResetEventDebounceStatus, operation=Event_DemEventParameter_ECU1_DTC26.ResetEventDebounceStatus
        Ev_SES_DemEventParameter_ECU1_DTC27: start-on-event=SetEventStatus, operation=Event_DemEventParameter_ECU1_DTC27.SetEventStatus
        Ev_SESWE_DemEventParameter_ECU1_DTC27: start-on-event=SetEventStatusWithEnvdata, operation=Event_DemEventParameter_ECU1_DTC27.SetEventStatusWithEnvdata
        Ev_RES_DemEventParameter_ECU1_DTC27: start-on-event=ResetEventStatus, operation=Event_DemEventParameter_ECU1_DTC27.ResetEventStatus
        Ev_CPFF_DemEventParameter_ECU1_DTC27: start-on-event=ClearPrestoredFreezeFrame, operation=Event_DemEventParameter_ECU1_DTC27.ClearPrestoredFreezeFrame
        Ev_PFF_DemEventParameter_ECU1_DTC27: start-on-event=PrestoreFreezeFrame, operation=Event_DemEventParameter_ECU1_DTC27.PrestoreFreezeFrame
        Ev_RDS_DemEventParameter_ECU1_DTC27: start-on-event=ResetEventDebounceStatus, operation=Event_DemEventParameter_ECU1_DTC27.ResetEventDebounceStatus
        Ev_SES_DemEventParameter_ECU1_DTC28: start-on-event=SetEventStatus, operation=Event_DemEventParameter_ECU1_DTC28.SetEventStatus
        Ev_SESWE_DemEventParameter_ECU1_DTC28: start-on-event=SetEventStatusWithEnvdata, operation=Event_DemEventParameter_ECU1_DTC28.SetEventStatusWithEnvdata
        Ev_RES_DemEventParameter_ECU1_DTC28: start-on-event=ResetEventStatus, operation=Event_DemEventParameter_ECU1_DTC28.ResetEventStatus
        Ev_CPFF_DemEventParameter_ECU1_DTC28: start-on-event=ClearPrestoredFreezeFrame, operation=Event_DemEventParameter_ECU1_DTC28.ClearPrestoredFreezeFrame
        Ev_PFF_DemEventParameter_ECU1_DTC28: start-on-event=PrestoreFreezeFrame, operation=Event_DemEventParameter_ECU1_DTC28.PrestoreFreezeFrame
        Ev_RDS_DemEventParameter_ECU1_DTC28: start-on-event=ResetEventDebounceStatus, operation=Event_DemEventParameter_ECU1_DTC28.ResetEventDebounceStatus
        Ev_SES_DemEventParameter_ECU1_DTC29: start-on-event=SetEventStatus, operation=Event_DemEventParameter_ECU1_DTC29.SetEventStatus
        Ev_SESWE_DemEventParameter_ECU1_DTC29: start-on-event=SetEventStatusWithEnvdata, operation=Event_DemEventParameter_ECU1_DTC29.SetEventStatusWithEnvdata
        Ev_RES_DemEventParameter_ECU1_DTC29: start-on-event=ResetEventStatus, operation=Event_DemEventParameter_ECU1_DTC29.ResetEventStatus
        Ev_CPFF_DemEventParameter_ECU1_DTC29: start-on-event=ClearPrestoredFreezeFrame, operation=Event_DemEventParameter_ECU1_DTC29.ClearPrestoredFreezeFrame
        Ev_PFF_DemEventParameter_ECU1_DTC29: start-on-event=PrestoreFreezeFrame, operation=Event_DemEventParameter_ECU1_DTC29.PrestoreFreezeFrame
        Ev_RDS_DemEventParameter_ECU1_DTC29: start-on-event=ResetEventDebounceStatus, operation=Event_DemEventParameter_ECU1_DTC29.ResetEventDebounceStatus
        Ev_SES_DemEventParameter_ECU1_DTC30: start-on-event=SetEventStatus, operation=Event_DemEventParameter_ECU1_DTC30.SetEventStatus
        Ev_SESWE_DemEventParameter_ECU1_DTC30: start-on-event=SetEventStatusWithEnvdata, operation=Event_DemEventParameter_ECU1_DTC30.SetEventStatusWithEnvdata
        Ev_RES_DemEventParameter_ECU1_DTC30: start-on-event=ResetEventStatus, operation=Event_DemEventParameter_ECU1_DTC30.ResetEventStatus
        Ev_CPFF_DemEventParameter_ECU1_DTC30: start-on-event=ClearPrestoredFreezeFrame, operation=Event_DemEventParameter_ECU1_DTC30.ClearPrestoredFreezeFrame
        Ev_PFF_DemEventParameter_ECU1_DTC30: start-on-event=PrestoreFreezeFrame, operation=Event_DemEventParameter_ECU1_DTC30.PrestoreFreezeFrame
        Ev_RDS_DemEventParameter_ECU1_DTC30: start-on-event=ResetEventDebounceStatus, operation=Event_DemEventParameter_ECU1_DTC30.ResetEventDebounceStatus
        Ev_SES_DemEventParameter_ECU1_DTC31: start-on-event=SetEventStatus, operation=Event_DemEventParameter_ECU1_DTC31.SetEventStatus
        Ev_SESWE_DemEventParameter_ECU1_DTC31: start-on-event=SetEventStatusWithEnvdata, operation=Event_DemEventParameter_ECU1_DTC31.SetEventStatusWithEnvdata
        Ev_RES_DemEventParameter_ECU1_DTC31: start-on-event=ResetEventStatus, operation=Event_DemEventParameter_ECU1_DTC31.ResetEventStatus
        Ev_CPFF_DemEventParameter_ECU1_DTC31: start-on-event=ClearPrestoredFreezeFrame, operation=Event_DemEventParameter_ECU1_DTC31.ClearPrestoredFreezeFrame
        Ev_PFF_DemEventParameter_ECU1_DTC31: start-on-event=PrestoreFreezeFrame, operation=Event_DemEventParameter_ECU1_DTC31.PrestoreFreezeFrame
        Ev_RDS_DemEventParameter_ECU1_DTC31: start-on-event=ResetEventDebounceStatus, operation=Event_DemEventParameter_ECU1_DTC31.ResetEventDebounceStatus
        Ev_SES_DemEventParameter_ECU1_DTC32: start-on-event=SetEventStatus, operation=Event_DemEventParameter_ECU1_DTC32.SetEventStatus
        Ev_SESWE_DemEventParameter_ECU1_DTC32: start-on-event=SetEventStatusWithEnvdata, operation=Event_DemEventParameter_ECU1_DTC32.SetEventStatusWithEnvdata
        Ev_RES_DemEventParameter_ECU1_DTC32: start-on-event=ResetEventStatus, operation=Event_DemEventParameter_ECU1_DTC32.ResetEventStatus
        Ev_CPFF_DemEventParameter_ECU1_DTC32: start-on-event=ClearPrestoredFreezeFrame, operation=Event_DemEventParameter_ECU1_DTC32.ClearPrestoredFreezeFrame
        Ev_PFF_DemEventParameter_ECU1_DTC32: start-on-event=PrestoreFreezeFrame, operation=Event_DemEventParameter_ECU1_DTC32.PrestoreFreezeFrame
        Ev_RDS_DemEventParameter_ECU1_DTC32: start-on-event=ResetEventDebounceStatus, operation=Event_DemEventParameter_ECU1_DTC32.ResetEventDebounceStatus
        Ev_SES_DemEventParameter_ECU1_DTC33: start-on-event=SetEventStatus, operation=Event_DemEventParameter_ECU1_DTC33.SetEventStatus
        Ev_SESWE_DemEventParameter_ECU1_DTC33: start-on-event=SetEventStatusWithEnvdata, operation=Event_DemEventParameter_ECU1_DTC33.SetEventStatusWithEnvdata
        Ev_RES_DemEventParameter_ECU1_DTC33: start-on-event=ResetEventStatus, operation=Event_DemEventParameter_ECU1_DTC33.ResetEventStatus
        Ev_CPFF_DemEventParameter_ECU1_DTC33: start-on-event=ClearPrestoredFreezeFrame, operation=Event_DemEventParameter_ECU1_DTC33.ClearPrestoredFreezeFrame
        Ev_PFF_DemEventParameter_ECU1_DTC33: start-on-event=PrestoreFreezeFrame, operation=Event_DemEventParameter_ECU1_DTC33.PrestoreFreezeFrame
        Ev_RDS_DemEventParameter_ECU1_DTC33: start-on-event=ResetEventDebounceStatus, operation=Event_DemEventParameter_ECU1_DTC33.ResetEventDebounceStatus
        Ev_SES_DemEventParameter_ECU1_DTC34: start-on-event=SetEventStatus, operation=Event_DemEventParameter_ECU1_DTC34.SetEventStatus
        Ev_SESWE_DemEventParameter_ECU1_DTC34: start-on-event=SetEventStatusWithEnvdata, operation=Event_DemEventParameter_ECU1_DTC34.SetEventStatusWithEnvdata
        Ev_RES_DemEventParameter_ECU1_DTC34: start-on-event=ResetEventStatus, operation=Event_DemEventParameter_ECU1_DTC34.ResetEventStatus
        Ev_CPFF_DemEventParameter_ECU1_DTC34: start-on-event=ClearPrestoredFreezeFrame, operation=Event_DemEventParameter_ECU1_DTC34.ClearPrestoredFreezeFrame
        Ev_PFF_DemEventParameter_ECU1_DTC34: start-on-event=PrestoreFreezeFrame, operation=Event_DemEventParameter_ECU1_DTC34.PrestoreFreezeFrame
        Ev_RDS_DemEventParameter_ECU1_DTC34: start-on-event=ResetEventDebounceStatus, operation=Event_DemEventParameter_ECU1_DTC34.ResetEventDebounceStatus
        Ev_SES_DemEventParameter_ECU1_DTC35: start-on-event=SetEventStatus, operation=Event_DemEventParameter_ECU1_DTC35.SetEventStatus
        Ev_SESWE_DemEventParameter_ECU1_DTC35: start-on-event=SetEventStatusWithEnvdata, operation=Event_DemEventParameter_ECU1_DTC35.SetEventStatusWithEnvdata
        Ev_RES_DemEventParameter_ECU1_DTC35: start-on-event=ResetEventStatus, operation=Event_DemEventParameter_ECU1_DTC35.ResetEventStatus
        Ev_CPFF_DemEventParameter_ECU1_DTC35: start-on-event=ClearPrestoredFreezeFrame, operation=Event_DemEventParameter_ECU1_DTC35.ClearPrestoredFreezeFrame
        Ev_PFF_DemEventParameter_ECU1_DTC35: start-on-event=PrestoreFreezeFrame, operation=Event_DemEventParameter_ECU1_DTC35.PrestoreFreezeFrame
        Ev_RDS_DemEventParameter_ECU1_DTC35: start-on-event=ResetEventDebounceStatus, operation=Event_DemEventParameter_ECU1_DTC35.ResetEventDebounceStatus
        Ev_SES_DemEventParameter_ECU1_DTC36: start-on-event=SetEventStatus, operation=Event_DemEventParameter_ECU1_DTC36.SetEventStatus
        Ev_SESWE_DemEventParameter_ECU1_DTC36: start-on-event=SetEventStatusWithEnvdata, operation=Event_DemEventParameter_ECU1_DTC36.SetEventStatusWithEnvdata
        Ev_RES_DemEventParameter_ECU1_DTC36: start-on-event=ResetEventStatus, operation=Event_DemEventParameter_ECU1_DTC36.ResetEventStatus
        Ev_CPFF_DemEventParameter_ECU1_DTC36: start-on-event=ClearPrestoredFreezeFrame, operation=Event_DemEventParameter_ECU1_DTC36.ClearPrestoredFreezeFrame
        Ev_PFF_DemEventParameter_ECU1_DTC36: start-on-event=PrestoreFreezeFrame, operation=Event_DemEventParameter_ECU1_DTC36.PrestoreFreezeFrame
        Ev_RDS_DemEventParameter_ECU1_DTC36: start-on-event=ResetEventDebounceStatus, operation=Event_DemEventParameter_ECU1_DTC36.ResetEventDebounceStatus
        Ev_SES_DemEventParameter_ECU1_DTC37: start-on-event=SetEventStatus, operation=Event_DemEventParameter_ECU1_DTC37.SetEventStatus
        Ev_SESWE_DemEventParameter_ECU1_DTC37: start-on-event=SetEventStatusWithEnvdata, operation=Event_DemEventParameter_ECU1_DTC37.SetEventStatusWithEnvdata
        Ev_RES_DemEventParameter_ECU1_DTC37: start-on-event=ResetEventStatus, operation=Event_DemEventParameter_ECU1_DTC37.ResetEventStatus
        Ev_CPFF_DemEventParameter_ECU1_DTC37: start-on-event=ClearPrestoredFreezeFrame, operation=Event_DemEventParameter_ECU1_DTC37.ClearPrestoredFreezeFrame
        Ev_PFF_DemEventParameter_ECU1_DTC37: start-on-event=PrestoreFreezeFrame, operation=Event_DemEventParameter_ECU1_DTC37.PrestoreFreezeFrame
        Ev_RDS_DemEventParameter_ECU1_DTC37: start-on-event=ResetEventDebounceStatus, operation=Event_DemEventParameter_ECU1_DTC37.ResetEventDebounceStatus
        Ev_SES_DemEventParameter_ECU1_DTC38: start-on-event=SetEventStatus, operation=Event_DemEventParameter_ECU1_DTC38.SetEventStatus
        Ev_SESWE_DemEventParameter_ECU1_DTC38: start-on-event=SetEventStatusWithEnvdata, operation=Event_DemEventParameter_ECU1_DTC38.SetEventStatusWithEnvdata
        Ev_RES_DemEventParameter_ECU1_DTC38: start-on-event=ResetEventStatus, operation=Event_DemEventParameter_ECU1_DTC38.ResetEventStatus
        Ev_CPFF_DemEventParameter_ECU1_DTC38: start-on-event=ClearPrestoredFreezeFrame, operation=Event_DemEventParameter_ECU1_DTC38.ClearPrestoredFreezeFrame
        Ev_PFF_DemEventParameter_ECU1_DTC38: start-on-event=PrestoreFreezeFrame, operation=Event_DemEventParameter_ECU1_DTC38.PrestoreFreezeFrame
        Ev_RDS_DemEventParameter_ECU1_DTC38: start-on-event=ResetEventDebounceStatus, operation=Event_DemEventParameter_ECU1_DTC38.ResetEventDebounceStatus
        Ev_SES_DemEventParameter_ECU1_DTC39: start-on-event=SetEventStatus, operation=Event_DemEventParameter_ECU1_DTC39.SetEventStatus
        Ev_SESWE_DemEventParameter_ECU1_DTC39: start-on-event=SetEventStatusWithEnvdata, operation=Event_DemEventParameter_ECU1_DTC39.SetEventStatusWithEnvdata
        Ev_RES_DemEventParameter_ECU1_DTC39: start-on-event=ResetEventStatus, operation=Event_DemEventParameter_ECU1_DTC39.ResetEventStatus
        Ev_CPFF_DemEventParameter_ECU1_DTC39: start-on-event=ClearPrestoredFreezeFrame, operation=Event_DemEventParameter_ECU1_DTC39.ClearPrestoredFreezeFrame
        Ev_PFF_DemEventParameter_ECU1_DTC39: start-on-event=PrestoreFreezeFrame, operation=Event_DemEventParameter_ECU1_DTC39.PrestoreFreezeFrame
        Ev_RDS_DemEventParameter_ECU1_DTC39: start-on-event=ResetEventDebounceStatus, operation=Event_DemEventParameter_ECU1_DTC39.ResetEventDebounceStatus
        Ev_SES_DemEventParameter_ECU1_DTC40: start-on-event=SetEventStatus, operation=Event_DemEventParameter_ECU1_DTC40.SetEventStatus
        Ev_SESWE_DemEventParameter_ECU1_DTC40: start-on-event=SetEventStatusWithEnvdata, operation=Event_DemEventParameter_ECU1_DTC40.SetEventStatusWithEnvdata
        Ev_RES_DemEventParameter_ECU1_DTC40: start-on-event=ResetEventStatus, operation=Event_DemEventParameter_ECU1_DTC40.ResetEventStatus
        Ev_CPFF_DemEventParameter_ECU1_DTC40: start-on-event=ClearPrestoredFreezeFrame, operation=Event_DemEventParameter_ECU1_DTC40.ClearPrestoredFreezeFrame
        Ev_PFF_DemEventParameter_ECU1_DTC40: start-on-event=PrestoreFreezeFrame, operation=Event_DemEventParameter_ECU1_DTC40.PrestoreFreezeFrame
        Ev_RDS_DemEventParameter_ECU1_DTC40: start-on-event=ResetEventDebounceStatus, operation=Event_DemEventParameter_ECU1_DTC40.ResetEventDebounceStatus
        Ev_SES_DemEventParameter_ECU1_DTC41: start-on-event=SetEventStatus, operation=Event_DemEventParameter_ECU1_DTC41.SetEventStatus
        Ev_SESWE_DemEventParameter_ECU1_DTC41: start-on-event=SetEventStatusWithEnvdata, operation=Event_DemEventParameter_ECU1_DTC41.SetEventStatusWithEnvdata
        Ev_RES_DemEventParameter_ECU1_DTC41: start-on-event=ResetEventStatus, operation=Event_DemEventParameter_ECU1_DTC41.ResetEventStatus
        Ev_CPFF_DemEventParameter_ECU1_DTC41: start-on-event=ClearPrestoredFreezeFrame, operation=Event_DemEventParameter_ECU1_DTC41.ClearPrestoredFreezeFrame
        Ev_PFF_DemEventParameter_ECU1_DTC41: start-on-event=PrestoreFreezeFrame, operation=Event_DemEventParameter_ECU1_DTC41.PrestoreFreezeFrame
        Ev_RDS_DemEventParameter_ECU1_DTC41: start-on-event=ResetEventDebounceStatus, operation=Event_DemEventParameter_ECU1_DTC41.ResetEventDebounceStatus
        Ev_SES_DemEventParameter_ECU1_DTC42: start-on-event=SetEventStatus, operation=Event_DemEventParameter_ECU1_DTC42.SetEventStatus
        Ev_SESWE_DemEventParameter_ECU1_DTC42: start-on-event=SetEventStatusWithEnvdata, operation=Event_DemEventParameter_ECU1_DTC42.SetEventStatusWithEnvdata
        Ev_RES_DemEventParameter_ECU1_DTC42: start-on-event=ResetEventStatus, operation=Event_DemEventParameter_ECU1_DTC42.ResetEventStatus
        Ev_CPFF_DemEventParameter_ECU1_DTC42: start-on-event=ClearPrestoredFreezeFrame, operation=Event_DemEventParameter_ECU1_DTC42.ClearPrestoredFreezeFrame
        Ev_PFF_DemEventParameter_ECU1_DTC42: start-on-event=PrestoreFreezeFrame, operation=Event_DemEventParameter_ECU1_DTC42.PrestoreFreezeFrame
        Ev_RDS_DemEventParameter_ECU1_DTC42: start-on-event=ResetEventDebounceStatus, operation=Event_DemEventParameter_ECU1_DTC42.ResetEventDebounceStatus
        Ev_SES_DemEventParameter_ECU1_DTC43: start-on-event=SetEventStatus, operation=Event_DemEventParameter_ECU1_DTC43.SetEventStatus
        Ev_SESWE_DemEventParameter_ECU1_DTC43: start-on-event=SetEventStatusWithEnvdata, operation=Event_DemEventParameter_ECU1_DTC43.SetEventStatusWithEnvdata
        Ev_RES_DemEventParameter_ECU1_DTC43: start-on-event=ResetEventStatus, operation=Event_DemEventParameter_ECU1_DTC43.ResetEventStatus
        Ev_CPFF_DemEventParameter_ECU1_DTC43: start-on-event=ClearPrestoredFreezeFrame, operation=Event_DemEventParameter_ECU1_DTC43.ClearPrestoredFreezeFrame
        Ev_PFF_DemEventParameter_ECU1_DTC43: start-on-event=PrestoreFreezeFrame, operation=Event_DemEventParameter_ECU1_DTC43.PrestoreFreezeFrame
        Ev_RDS_DemEventParameter_ECU1_DTC43: start-on-event=ResetEventDebounceStatus, operation=Event_DemEventParameter_ECU1_DTC43.ResetEventDebounceStatus
        Ev_SES_DemEventParameter_ECU1_DTC44: start-on-event=SetEventStatus, operation=Event_DemEventParameter_ECU1_DTC44.SetEventStatus
        Ev_SESWE_DemEventParameter_ECU1_DTC44: start-on-event=SetEventStatusWithEnvdata, operation=Event_DemEventParameter_ECU1_DTC44.SetEventStatusWithEnvdata
        Ev_RES_DemEventParameter_ECU1_DTC44: start-on-event=ResetEventStatus, operation=Event_DemEventParameter_ECU1_DTC44.ResetEventStatus
        Ev_CPFF_DemEventParameter_ECU1_DTC44: start-on-event=ClearPrestoredFreezeFrame, operation=Event_DemEventParameter_ECU1_DTC44.ClearPrestoredFreezeFrame
        Ev_PFF_DemEventParameter_ECU1_DTC44: start-on-event=PrestoreFreezeFrame, operation=Event_DemEventParameter_ECU1_DTC44.PrestoreFreezeFrame
        Ev_RDS_DemEventParameter_ECU1_DTC44: start-on-event=ResetEventDebounceStatus, operation=Event_DemEventParameter_ECU1_DTC44.ResetEventDebounceStatus
        Ev_SES_DemEventParameter_ECU1_DTC45: start-on-event=SetEventStatus, operation=Event_DemEventParameter_ECU1_DTC45.SetEventStatus
        Ev_SESWE_DemEventParameter_ECU1_DTC45: start-on-event=SetEventStatusWithEnvdata, operation=Event_DemEventParameter_ECU1_DTC45.SetEventStatusWithEnvdata
        Ev_RES_DemEventParameter_ECU1_DTC45: start-on-event=ResetEventStatus, operation=Event_DemEventParameter_ECU1_DTC45.ResetEventStatus
        Ev_CPFF_DemEventParameter_ECU1_DTC45: start-on-event=ClearPrestoredFreezeFrame, operation=Event_DemEventParameter_ECU1_DTC45.ClearPrestoredFreezeFrame
        Ev_PFF_DemEventParameter_ECU1_DTC45: start-on-event=PrestoreFreezeFrame, operation=Event_DemEventParameter_ECU1_DTC45.PrestoreFreezeFrame
        Ev_RDS_DemEventParameter_ECU1_DTC45: start-on-event=ResetEventDebounceStatus, operation=Event_DemEventParameter_ECU1_DTC45.ResetEventDebounceStatus
        Ev_SES_DemEventParameter_ECU1_DTC46: start-on-event=SetEventStatus, operation=Event_DemEventParameter_ECU1_DTC46.SetEventStatus
        Ev_SESWE_DemEventParameter_ECU1_DTC46: start-on-event=SetEventStatusWithEnvdata, operation=Event_DemEventParameter_ECU1_DTC46.SetEventStatusWithEnvdata
        Ev_RES_DemEventParameter_ECU1_DTC46: start-on-event=ResetEventStatus, operation=Event_DemEventParameter_ECU1_DTC46.ResetEventStatus
        Ev_CPFF_DemEventParameter_ECU1_DTC46: start-on-event=ClearPrestoredFreezeFrame, operation=Event_DemEventParameter_ECU1_DTC46.ClearPrestoredFreezeFrame
        Ev_PFF_DemEventParameter_ECU1_DTC46: start-on-event=PrestoreFreezeFrame, operation=Event_DemEventParameter_ECU1_DTC46.PrestoreFreezeFrame
        Ev_RDS_DemEventParameter_ECU1_DTC46: start-on-event=ResetEventDebounceStatus, operation=Event_DemEventParameter_ECU1_DTC46.ResetEventDebounceStatus
        Ev_SES_DemEventParameter_ECU1_DTC47: start-on-event=SetEventStatus, operation=Event_DemEventParameter_ECU1_DTC47.SetEventStatus
        Ev_SESWE_DemEventParameter_ECU1_DTC47: start-on-event=SetEventStatusWithEnvdata, operation=Event_DemEventParameter_ECU1_DTC47.SetEventStatusWithEnvdata
        Ev_RES_DemEventParameter_ECU1_DTC47: start-on-event=ResetEventStatus, operation=Event_DemEventParameter_ECU1_DTC47.ResetEventStatus
        Ev_CPFF_DemEventParameter_ECU1_DTC47: start-on-event=ClearPrestoredFreezeFrame, operation=Event_DemEventParameter_ECU1_DTC47.ClearPrestoredFreezeFrame
        Ev_PFF_DemEventParameter_ECU1_DTC47: start-on-event=PrestoreFreezeFrame, operation=Event_DemEventParameter_ECU1_DTC47.PrestoreFreezeFrame
        Ev_RDS_DemEventParameter_ECU1_DTC47: start-on-event=ResetEventDebounceStatus, operation=Event_DemEventParameter_ECU1_DTC47.ResetEventDebounceStatus
        Ev_SES_DemEventParameter_ECU1_DTC48: start-on-event=SetEventStatus, operation=Event_DemEventParameter_ECU1_DTC48.SetEventStatus
        Ev_SESWE_DemEventParameter_ECU1_DTC48: start-on-event=SetEventStatusWithEnvdata, operation=Event_DemEventParameter_ECU1_DTC48.SetEventStatusWithEnvdata
        Ev_RES_DemEventParameter_ECU1_DTC48: start-on-event=ResetEventStatus, operation=Event_DemEventParameter_ECU1_DTC48.ResetEventStatus
        Ev_CPFF_DemEventParameter_ECU1_DTC48: start-on-event=ClearPrestoredFreezeFrame, operation=Event_DemEventParameter_ECU1_DTC48.ClearPrestoredFreezeFrame
        Ev_PFF_DemEventParameter_ECU1_DTC48: start-on-event=PrestoreFreezeFrame, operation=Event_DemEventParameter_ECU1_DTC48.PrestoreFreezeFrame
        Ev_RDS_DemEventParameter_ECU1_DTC48: start-on-event=ResetEventDebounceStatus, operation=Event_DemEventParameter_ECU1_DTC48.ResetEventDebounceStatus
        Ev_SES_DemEventParameter_ECU1_DTC49: start-on-event=SetEventStatus, operation=Event_DemEventParameter_ECU1_DTC49.SetEventStatus
        Ev_SESWE_DemEventParameter_ECU1_DTC49: start-on-event=SetEventStatusWithEnvdata, operation=Event_DemEventParameter_ECU1_DTC49.SetEventStatusWithEnvdata
        Ev_RES_DemEventParameter_ECU1_DTC49: start-on-event=ResetEventStatus, operation=Event_DemEventParameter_ECU1_DTC49.ResetEventStatus
        Ev_CPFF_DemEventParameter_ECU1_DTC49: start-on-event=ClearPrestoredFreezeFrame, operation=Event_DemEventParameter_ECU1_DTC49.ClearPrestoredFreezeFrame
        Ev_PFF_DemEventParameter_ECU1_DTC49: start-on-event=PrestoreFreezeFrame, operation=Event_DemEventParameter_ECU1_DTC49.PrestoreFreezeFrame
        Ev_RDS_DemEventParameter_ECU1_DTC49: start-on-event=ResetEventDebounceStatus, operation=Event_DemEventParameter_ECU1_DTC49.ResetEventDebounceStatus
        Ev_SES_DemEventParameter_ECU1_DTC50: start-on-event=SetEventStatus, operation=Event_DemEventParameter_ECU1_DTC50.SetEventStatus
        Ev_SESWE_DemEventParameter_ECU1_DTC50: start-on-event=SetEventStatusWithEnvdata, operation=Event_DemEventParameter_ECU1_DTC50.SetEventStatusWithEnvdata
        Ev_RES_DemEventParameter_ECU1_DTC50: start-on-event=ResetEventStatus, operation=Event_DemEventParameter_ECU1_DTC50.ResetEventStatus
        Ev_CPFF_DemEventParameter_ECU1_DTC50: start-on-event=ClearPrestoredFreezeFrame, operation=Event_DemEventParameter_ECU1_DTC50.ClearPrestoredFreezeFrame
        Ev_PFF_DemEventParameter_ECU1_DTC50: start-on-event=PrestoreFreezeFrame, operation=Event_DemEventParameter_ECU1_DTC50.PrestoreFreezeFrame
        Ev_RDS_DemEventParameter_ECU1_DTC50: start-on-event=ResetEventDebounceStatus, operation=Event_DemEventParameter_ECU1_DTC50.ResetEventDebounceStatus
        Ev_SES_DemEventParameter_ECU1_DTC51: start-on-event=SetEventStatus, operation=Event_DemEventParameter_ECU1_DTC51.SetEventStatus
        Ev_SESWE_DemEventParameter_ECU1_DTC51: start-on-event=SetEventStatusWithEnvdata, operation=Event_DemEventParameter_ECU1_DTC51.SetEventStatusWithEnvdata
        Ev_RES_DemEventParameter_ECU1_DTC51: start-on-event=ResetEventStatus, operation=Event_DemEventParameter_ECU1_DTC51.ResetEventStatus
        Ev_CPFF_DemEventParameter_ECU1_DTC51: start-on-event=ClearPrestoredFreezeFrame, operation=Event_DemEventParameter_ECU1_DTC51.ClearPrestoredFreezeFrame
        Ev_PFF_DemEventParameter_ECU1_DTC51: start-on-event=PrestoreFreezeFrame, operation=Event_DemEventParameter_ECU1_DTC51.PrestoreFreezeFrame
        Ev_RDS_DemEventParameter_ECU1_DTC51: start-on-event=ResetEventDebounceStatus, operation=Event_DemEventParameter_ECU1_DTC51.ResetEventDebounceStatus
        Ev_SES_DemEventParameter_ECU1_DTC52: start-on-event=SetEventStatus, operation=Event_DemEventParameter_ECU1_DTC52.SetEventStatus
        Ev_SESWE_DemEventParameter_ECU1_DTC52: start-on-event=SetEventStatusWithEnvdata, operation=Event_DemEventParameter_ECU1_DTC52.SetEventStatusWithEnvdata
        Ev_RES_DemEventParameter_ECU1_DTC52: start-on-event=ResetEventStatus, operation=Event_DemEventParameter_ECU1_DTC52.ResetEventStatus
        Ev_CPFF_DemEventParameter_ECU1_DTC52: start-on-event=ClearPrestoredFreezeFrame, operation=Event_DemEventParameter_ECU1_DTC52.ClearPrestoredFreezeFrame
        Ev_PFF_DemEventParameter_ECU1_DTC52: start-on-event=PrestoreFreezeFrame, operation=Event_DemEventParameter_ECU1_DTC52.PrestoreFreezeFrame
        Ev_RDS_DemEventParameter_ECU1_DTC52: start-on-event=ResetEventDebounceStatus, operation=Event_DemEventParameter_ECU1_DTC52.ResetEventDebounceStatus
        Ev_SES_DemEventParameter_ECU1_DTC53: start-on-event=SetEventStatus, operation=Event_DemEventParameter_ECU1_DTC53.SetEventStatus
        Ev_SESWE_DemEventParameter_ECU1_DTC53: start-on-event=SetEventStatusWithEnvdata, operation=Event_DemEventParameter_ECU1_DTC53.SetEventStatusWithEnvdata
        Ev_RES_DemEventParameter_ECU1_DTC53: start-on-event=ResetEventStatus, operation=Event_DemEventParameter_ECU1_DTC53.ResetEventStatus
        Ev_CPFF_DemEventParameter_ECU1_DTC53: start-on-event=ClearPrestoredFreezeFrame, operation=Event_DemEventParameter_ECU1_DTC53.ClearPrestoredFreezeFrame
        Ev_PFF_DemEventParameter_ECU1_DTC53: start-on-event=PrestoreFreezeFrame, operation=Event_DemEventParameter_ECU1_DTC53.PrestoreFreezeFrame
        Ev_RDS_DemEventParameter_ECU1_DTC53: start-on-event=ResetEventDebounceStatus, operation=Event_DemEventParameter_ECU1_DTC53.ResetEventDebounceStatus
        Ev_SES_DemEventParameter_ECU1_DTC54: start-on-event=SetEventStatus, operation=Event_DemEventParameter_ECU1_DTC54.SetEventStatus
        Ev_SESWE_DemEventParameter_ECU1_DTC54: start-on-event=SetEventStatusWithEnvdata, operation=Event_DemEventParameter_ECU1_DTC54.SetEventStatusWithEnvdata
        Ev_RES_DemEventParameter_ECU1_DTC54: start-on-event=ResetEventStatus, operation=Event_DemEventParameter_ECU1_DTC54.ResetEventStatus
        Ev_CPFF_DemEventParameter_ECU1_DTC54: start-on-event=ClearPrestoredFreezeFrame, operation=Event_DemEventParameter_ECU1_DTC54.ClearPrestoredFreezeFrame
        Ev_PFF_DemEventParameter_ECU1_DTC54: start-on-event=PrestoreFreezeFrame, operation=Event_DemEventParameter_ECU1_DTC54.PrestoreFreezeFrame
        Ev_RDS_DemEventParameter_ECU1_DTC54: start-on-event=ResetEventDebounceStatus, operation=Event_DemEventParameter_ECU1_DTC54.ResetEventDebounceStatus
        Ev_SES_DemEventParameter_ECU1_DTC55: start-on-event=SetEventStatus, operation=Event_DemEventParameter_ECU1_DTC55.SetEventStatus
        Ev_SESWE_DemEventParameter_ECU1_DTC55: start-on-event=SetEventStatusWithEnvdata, operation=Event_DemEventParameter_ECU1_DTC55.SetEventStatusWithEnvdata
        Ev_RES_DemEventParameter_ECU1_DTC55: start-on-event=ResetEventStatus, operation=Event_DemEventParameter_ECU1_DTC55.ResetEventStatus
        Ev_CPFF_DemEventParameter_ECU1_DTC55: start-on-event=ClearPrestoredFreezeFrame, operation=Event_DemEventParameter_ECU1_DTC55.ClearPrestoredFreezeFrame
        Ev_PFF_DemEventParameter_ECU1_DTC55: start-on-event=PrestoreFreezeFrame, operation=Event_DemEventParameter_ECU1_DTC55.PrestoreFreezeFrame
        Ev_RDS_DemEventParameter_ECU1_DTC55: start-on-event=ResetEventDebounceStatus, operation=Event_DemEventParameter_ECU1_DTC55.ResetEventDebounceStatus
        Ev_SES_DemEventParameter_ECU1_DTC56: start-on-event=SetEventStatus, operation=Event_DemEventParameter_ECU1_DTC56.SetEventStatus
        Ev_SESWE_DemEventParameter_ECU1_DTC56: start-on-event=SetEventStatusWithEnvdata, operation=Event_DemEventParameter_ECU1_DTC56.SetEventStatusWithEnvdata
        Ev_RES_DemEventParameter_ECU1_DTC56: start-on-event=ResetEventStatus, operation=Event_DemEventParameter_ECU1_DTC56.ResetEventStatus
        Ev_CPFF_DemEventParameter_ECU1_DTC56: start-on-event=ClearPrestoredFreezeFrame, operation=Event_DemEventParameter_ECU1_DTC56.ClearPrestoredFreezeFrame
        Ev_PFF_DemEventParameter_ECU1_DTC56: start-on-event=PrestoreFreezeFrame, operation=Event_DemEventParameter_ECU1_DTC56.PrestoreFreezeFrame
        Ev_RDS_DemEventParameter_ECU1_DTC56: start-on-event=ResetEventDebounceStatus, operation=Event_DemEventParameter_ECU1_DTC56.ResetEventDebounceStatus
        Ev_SES_DemEventParameter_ECU1_DTC57: start-on-event=SetEventStatus, operation=Event_DemEventParameter_ECU1_DTC57.SetEventStatus
        Ev_SESWE_DemEventParameter_ECU1_DTC57: start-on-event=SetEventStatusWithEnvdata, operation=Event_DemEventParameter_ECU1_DTC57.SetEventStatusWithEnvdata
        Ev_RES_DemEventParameter_ECU1_DTC57: start-on-event=ResetEventStatus, operation=Event_DemEventParameter_ECU1_DTC57.ResetEventStatus
        Ev_CPFF_DemEventParameter_ECU1_DTC57: start-on-event=ClearPrestoredFreezeFrame, operation=Event_DemEventParameter_ECU1_DTC57.ClearPrestoredFreezeFrame
        Ev_PFF_DemEventParameter_ECU1_DTC57: start-on-event=PrestoreFreezeFrame, operation=Event_DemEventParameter_ECU1_DTC57.PrestoreFreezeFrame
        Ev_RDS_DemEventParameter_ECU1_DTC57: start-on-event=ResetEventDebounceStatus, operation=Event_DemEventParameter_ECU1_DTC57.ResetEventDebounceStatus
        Ev_SES_DemEventParameter_ECU1_DTC58: start-on-event=SetEventStatus, operation=Event_DemEventParameter_ECU1_DTC58.SetEventStatus
        Ev_SESWE_DemEventParameter_ECU1_DTC58: start-on-event=SetEventStatusWithEnvdata, operation=Event_DemEventParameter_ECU1_DTC58.SetEventStatusWithEnvdata
        Ev_RES_DemEventParameter_ECU1_DTC58: start-on-event=ResetEventStatus, operation=Event_DemEventParameter_ECU1_DTC58.ResetEventStatus
        Ev_CPFF_DemEventParameter_ECU1_DTC58: start-on-event=ClearPrestoredFreezeFrame, operation=Event_DemEventParameter_ECU1_DTC58.ClearPrestoredFreezeFrame
        Ev_PFF_DemEventParameter_ECU1_DTC58: start-on-event=PrestoreFreezeFrame, operation=Event_DemEventParameter_ECU1_DTC58.PrestoreFreezeFrame
        Ev_RDS_DemEventParameter_ECU1_DTC58: start-on-event=ResetEventDebounceStatus, operation=Event_DemEventParameter_ECU1_DTC58.ResetEventDebounceStatus
        Ev_SES_DemEventParameter_ECU1_DTC59: start-on-event=SetEventStatus, operation=Event_DemEventParameter_ECU1_DTC59.SetEventStatus
        Ev_SESWE_DemEventParameter_ECU1_DTC59: start-on-event=SetEventStatusWithEnvdata, operation=Event_DemEventParameter_ECU1_DTC59.SetEventStatusWithEnvdata
        Ev_RES_DemEventParameter_ECU1_DTC59: start-on-event=ResetEventStatus, operation=Event_DemEventParameter_ECU1_DTC59.ResetEventStatus
        Ev_CPFF_DemEventParameter_ECU1_DTC59: start-on-event=ClearPrestoredFreezeFrame, operation=Event_DemEventParameter_ECU1_DTC59.ClearPrestoredFreezeFrame
        Ev_PFF_DemEventParameter_ECU1_DTC59: start-on-event=PrestoreFreezeFrame, operation=Event_DemEventParameter_ECU1_DTC59.PrestoreFreezeFrame
        Ev_RDS_DemEventParameter_ECU1_DTC59: start-on-event=ResetEventDebounceStatus, operation=Event_DemEventParameter_ECU1_DTC59.ResetEventDebounceStatus
        Ev_SES_DemEventParameter_ECU1_DTC60: start-on-event=SetEventStatus, operation=Event_DemEventParameter_ECU1_DTC60.SetEventStatus
        Ev_SESWE_DemEventParameter_ECU1_DTC60: start-on-event=SetEventStatusWithEnvdata, operation=Event_DemEventParameter_ECU1_DTC60.SetEventStatusWithEnvdata
        Ev_RES_DemEventParameter_ECU1_DTC60: start-on-event=ResetEventStatus, operation=Event_DemEventParameter_ECU1_DTC60.ResetEventStatus
        Ev_CPFF_DemEventParameter_ECU1_DTC60: start-on-event=ClearPrestoredFreezeFrame, operation=Event_DemEventParameter_ECU1_DTC60.ClearPrestoredFreezeFrame
        Ev_PFF_DemEventParameter_ECU1_DTC60: start-on-event=PrestoreFreezeFrame, operation=Event_DemEventParameter_ECU1_DTC60.PrestoreFreezeFrame
        Ev_RDS_DemEventParameter_ECU1_DTC60: start-on-event=ResetEventDebounceStatus, operation=Event_DemEventParameter_ECU1_DTC60.ResetEventDebounceStatus
        Ev_SES_DemEventParameter_ECU1_DTC61: start-on-event=SetEventStatus, operation=Event_DemEventParameter_ECU1_DTC61.SetEventStatus
        Ev_SESWE_DemEventParameter_ECU1_DTC61: start-on-event=SetEventStatusWithEnvdata, operation=Event_DemEventParameter_ECU1_DTC61.SetEventStatusWithEnvdata
        Ev_RES_DemEventParameter_ECU1_DTC61: start-on-event=ResetEventStatus, operation=Event_DemEventParameter_ECU1_DTC61.ResetEventStatus
        Ev_CPFF_DemEventParameter_ECU1_DTC61: start-on-event=ClearPrestoredFreezeFrame, operation=Event_DemEventParameter_ECU1_DTC61.ClearPrestoredFreezeFrame
        Ev_PFF_DemEventParameter_ECU1_DTC61: start-on-event=PrestoreFreezeFrame, operation=Event_DemEventParameter_ECU1_DTC61.PrestoreFreezeFrame
        Ev_RDS_DemEventParameter_ECU1_DTC61: start-on-event=ResetEventDebounceStatus, operation=Event_DemEventParameter_ECU1_DTC61.ResetEventDebounceStatus
        Ev_SES_DemEventParameter_ECU1_DTC62: start-on-event=SetEventStatus, operation=Event_DemEventParameter_ECU1_DTC62.SetEventStatus
        Ev_SESWE_DemEventParameter_ECU1_DTC62: start-on-event=SetEventStatusWithEnvdata, operation=Event_DemEventParameter_ECU1_DTC62.SetEventStatusWithEnvdata
        Ev_RES_DemEventParameter_ECU1_DTC62: start-on-event=ResetEventStatus, operation=Event_DemEventParameter_ECU1_DTC62.ResetEventStatus
        Ev_CPFF_DemEventParameter_ECU1_DTC62: start-on-event=ClearPrestoredFreezeFrame, operation=Event_DemEventParameter_ECU1_DTC62.ClearPrestoredFreezeFrame
        Ev_PFF_DemEventParameter_ECU1_DTC62: start-on-event=PrestoreFreezeFrame, operation=Event_DemEventParameter_ECU1_DTC62.PrestoreFreezeFrame
        Ev_RDS_DemEventParameter_ECU1_DTC62: start-on-event=ResetEventDebounceStatus, operation=Event_DemEventParameter_ECU1_DTC62.ResetEventDebounceStatus
        Ev_SES_DemEventParameter_ECU1_DTC63: start-on-event=SetEventStatus, operation=Event_DemEventParameter_ECU1_DTC63.SetEventStatus
        Ev_SESWE_DemEventParameter_ECU1_DTC63: start-on-event=SetEventStatusWithEnvdata, operation=Event_DemEventParameter_ECU1_DTC63.SetEventStatusWithEnvdata
        Ev_RES_DemEventParameter_ECU1_DTC63: start-on-event=ResetEventStatus, operation=Event_DemEventParameter_ECU1_DTC63.ResetEventStatus
        Ev_CPFF_DemEventParameter_ECU1_DTC63: start-on-event=ClearPrestoredFreezeFrame, operation=Event_DemEventParameter_ECU1_DTC63.ClearPrestoredFreezeFrame
        Ev_PFF_DemEventParameter_ECU1_DTC63: start-on-event=PrestoreFreezeFrame, operation=Event_DemEventParameter_ECU1_DTC63.PrestoreFreezeFrame
        Ev_RDS_DemEventParameter_ECU1_DTC63: start-on-event=ResetEventDebounceStatus, operation=Event_DemEventParameter_ECU1_DTC63.ResetEventDebounceStatus
        Ev_SES_DemEventParameter_ECU1_DTC64: start-on-event=SetEventStatus, operation=Event_DemEventParameter_ECU1_DTC64.SetEventStatus
        Ev_SESWE_DemEventParameter_ECU1_DTC64: start-on-event=SetEventStatusWithEnvdata, operation=Event_DemEventParameter_ECU1_DTC64.SetEventStatusWithEnvdata
        Ev_RES_DemEventParameter_ECU1_DTC64: start-on-event=ResetEventStatus, operation=Event_DemEventParameter_ECU1_DTC64.ResetEventStatus
        Ev_CPFF_DemEventParameter_ECU1_DTC64: start-on-event=ClearPrestoredFreezeFrame, operation=Event_DemEventParameter_ECU1_DTC64.ClearPrestoredFreezeFrame
        Ev_PFF_DemEventParameter_ECU1_DTC64: start-on-event=PrestoreFreezeFrame, operation=Event_DemEventParameter_ECU1_DTC64.PrestoreFreezeFrame
        Ev_RDS_DemEventParameter_ECU1_DTC64: start-on-event=ResetEventDebounceStatus, operation=Event_DemEventParameter_ECU1_DTC64.ResetEventDebounceStatus
        Ev_SES_DemEventParameter_ECU1_DTC65: start-on-event=SetEventStatus, operation=Event_DemEventParameter_ECU1_DTC65.SetEventStatus
        Ev_SESWE_DemEventParameter_ECU1_DTC65: start-on-event=SetEventStatusWithEnvdata, operation=Event_DemEventParameter_ECU1_DTC65.SetEventStatusWithEnvdata
        Ev_RES_DemEventParameter_ECU1_DTC65: start-on-event=ResetEventStatus, operation=Event_DemEventParameter_ECU1_DTC65.ResetEventStatus
        Ev_CPFF_DemEventParameter_ECU1_DTC65: start-on-event=ClearPrestoredFreezeFrame, operation=Event_DemEventParameter_ECU1_DTC65.ClearPrestoredFreezeFrame
        Ev_PFF_DemEventParameter_ECU1_DTC65: start-on-event=PrestoreFreezeFrame, operation=Event_DemEventParameter_ECU1_DTC65.PrestoreFreezeFrame
        Ev_RDS_DemEventParameter_ECU1_DTC65: start-on-event=ResetEventDebounceStatus, operation=Event_DemEventParameter_ECU1_DTC65.ResetEventDebounceStatus
        Ev_SES_DemEventParameter_ECU1_DTC66: start-on-event=SetEventStatus, operation=Event_DemEventParameter_ECU1_DTC66.SetEventStatus
        Ev_SESWE_DemEventParameter_ECU1_DTC66: start-on-event=SetEventStatusWithEnvdata, operation=Event_DemEventParameter_ECU1_DTC66.SetEventStatusWithEnvdata
        Ev_RES_DemEventParameter_ECU1_DTC66: start-on-event=ResetEventStatus, operation=Event_DemEventParameter_ECU1_DTC66.ResetEventStatus
        Ev_CPFF_DemEventParameter_ECU1_DTC66: start-on-event=ClearPrestoredFreezeFrame, operation=Event_DemEventParameter_ECU1_DTC66.ClearPrestoredFreezeFrame
        Ev_PFF_DemEventParameter_ECU1_DTC66: start-on-event=PrestoreFreezeFrame, operation=Event_DemEventParameter_ECU1_DTC66.PrestoreFreezeFrame
        Ev_RDS_DemEventParameter_ECU1_DTC66: start-on-event=ResetEventDebounceStatus, operation=Event_DemEventParameter_ECU1_DTC66.ResetEventDebounceStatus
        Ev_SES_DemEventParameter_ECU1_DTC67: start-on-event=SetEventStatus, operation=Event_DemEventParameter_ECU1_DTC67.SetEventStatus
        Ev_SESWE_DemEventParameter_ECU1_DTC67: start-on-event=SetEventStatusWithEnvdata, operation=Event_DemEventParameter_ECU1_DTC67.SetEventStatusWithEnvdata
        Ev_RES_DemEventParameter_ECU1_DTC67: start-on-event=ResetEventStatus, operation=Event_DemEventParameter_ECU1_DTC67.ResetEventStatus
        Ev_CPFF_DemEventParameter_ECU1_DTC67: start-on-event=ClearPrestoredFreezeFrame, operation=Event_DemEventParameter_ECU1_DTC67.ClearPrestoredFreezeFrame
        Ev_PFF_DemEventParameter_ECU1_DTC67: start-on-event=PrestoreFreezeFrame, operation=Event_DemEventParameter_ECU1_DTC67.PrestoreFreezeFrame
        Ev_RDS_DemEventParameter_ECU1_DTC67: start-on-event=ResetEventDebounceStatus, operation=Event_DemEventParameter_ECU1_DTC67.ResetEventDebounceStatus
        Ev_SES_DemEventParameter_ECU1_DTC68: start-on-event=SetEventStatus, operation=Event_DemEventParameter_ECU1_DTC68.SetEventStatus
        Ev_SESWE_DemEventParameter_ECU1_DTC68: start-on-event=SetEventStatusWithEnvdata, operation=Event_DemEventParameter_ECU1_DTC68.SetEventStatusWithEnvdata
        Ev_RES_DemEventParameter_ECU1_DTC68: start-on-event=ResetEventStatus, operation=Event_DemEventParameter_ECU1_DTC68.ResetEventStatus
        Ev_CPFF_DemEventParameter_ECU1_DTC68: start-on-event=ClearPrestoredFreezeFrame, operation=Event_DemEventParameter_ECU1_DTC68.ClearPrestoredFreezeFrame
        Ev_PFF_DemEventParameter_ECU1_DTC68: start-on-event=PrestoreFreezeFrame, operation=Event_DemEventParameter_ECU1_DTC68.PrestoreFreezeFrame
        Ev_RDS_DemEventParameter_ECU1_DTC68: start-on-event=ResetEventDebounceStatus, operation=Event_DemEventParameter_ECU1_DTC68.ResetEventDebounceStatus
        Ev_SES_DemEventParameter_ECU1_DTC69: start-on-event=SetEventStatus, operation=Event_DemEventParameter_ECU1_DTC69.SetEventStatus
        Ev_SESWE_DemEventParameter_ECU1_DTC69: start-on-event=SetEventStatusWithEnvdata, operation=Event_DemEventParameter_ECU1_DTC69.SetEventStatusWithEnvdata
        Ev_RES_DemEventParameter_ECU1_DTC69: start-on-event=ResetEventStatus, operation=Event_DemEventParameter_ECU1_DTC69.ResetEventStatus
        Ev_CPFF_DemEventParameter_ECU1_DTC69: start-on-event=ClearPrestoredFreezeFrame, operation=Event_DemEventParameter_ECU1_DTC69.ClearPrestoredFreezeFrame
        Ev_PFF_DemEventParameter_ECU1_DTC69: start-on-event=PrestoreFreezeFrame, operation=Event_DemEventParameter_ECU1_DTC69.PrestoreFreezeFrame
        Ev_RDS_DemEventParameter_ECU1_DTC69: start-on-event=ResetEventDebounceStatus, operation=Event_DemEventParameter_ECU1_DTC69.ResetEventDebounceStatus
        Ev_SES_DemEventParameter_ECU1_DTC70: start-on-event=SetEventStatus, operation=Event_DemEventParameter_ECU1_DTC70.SetEventStatus
        Ev_SESWE_DemEventParameter_ECU1_DTC70: start-on-event=SetEventStatusWithEnvdata, operation=Event_DemEventParameter_ECU1_DTC70.SetEventStatusWithEnvdata
        Ev_RES_DemEventParameter_ECU1_DTC70: start-on-event=ResetEventStatus, operation=Event_DemEventParameter_ECU1_DTC70.ResetEventStatus
        Ev_CPFF_DemEventParameter_ECU1_DTC70: start-on-event=ClearPrestoredFreezeFrame, operation=Event_DemEventParameter_ECU1_DTC70.ClearPrestoredFreezeFrame
        Ev_PFF_DemEventParameter_ECU1_DTC70: start-on-event=PrestoreFreezeFrame, operation=Event_DemEventParameter_ECU1_DTC70.PrestoreFreezeFrame
        Ev_RDS_DemEventParameter_ECU1_DTC70: start-on-event=ResetEventDebounceStatus, operation=Event_DemEventParameter_ECU1_DTC70.ResetEventDebounceStatus
        Ev_SES_DemEventParameter_ECU1_DTC71: start-on-event=SetEventStatus, operation=Event_DemEventParameter_ECU1_DTC71.SetEventStatus
        Ev_SESWE_DemEventParameter_ECU1_DTC71: start-on-event=SetEventStatusWithEnvdata, operation=Event_DemEventParameter_ECU1_DTC71.SetEventStatusWithEnvdata
        Ev_RES_DemEventParameter_ECU1_DTC71: start-on-event=ResetEventStatus, operation=Event_DemEventParameter_ECU1_DTC71.ResetEventStatus
        Ev_CPFF_DemEventParameter_ECU1_DTC71: start-on-event=ClearPrestoredFreezeFrame, operation=Event_DemEventParameter_ECU1_DTC71.ClearPrestoredFreezeFrame
        Ev_PFF_DemEventParameter_ECU1_DTC71: start-on-event=PrestoreFreezeFrame, operation=Event_DemEventParameter_ECU1_DTC71.PrestoreFreezeFrame
        Ev_RDS_DemEventParameter_ECU1_DTC71: start-on-event=ResetEventDebounceStatus, operation=Event_DemEventParameter_ECU1_DTC71.ResetEventDebounceStatus
        Ev_SES_DemEventParameter_ECU1_DTC72: start-on-event=SetEventStatus, operation=Event_DemEventParameter_ECU1_DTC72.SetEventStatus
        Ev_SESWE_DemEventParameter_ECU1_DTC72: start-on-event=SetEventStatusWithEnvdata, operation=Event_DemEventParameter_ECU1_DTC72.SetEventStatusWithEnvdata
        Ev_RES_DemEventParameter_ECU1_DTC72: start-on-event=ResetEventStatus, operation=Event_DemEventParameter_ECU1_DTC72.ResetEventStatus
        Ev_CPFF_DemEventParameter_ECU1_DTC72: start-on-event=ClearPrestoredFreezeFrame, operation=Event_DemEventParameter_ECU1_DTC72.ClearPrestoredFreezeFrame
        Ev_PFF_DemEventParameter_ECU1_DTC72: start-on-event=PrestoreFreezeFrame, operation=Event_DemEventParameter_ECU1_DTC72.PrestoreFreezeFrame
        Ev_RDS_DemEventParameter_ECU1_DTC72: start-on-event=ResetEventDebounceStatus, operation=Event_DemEventParameter_ECU1_DTC72.ResetEventDebounceStatus
        Ev_SES_DemEventParameter_ECU1_DTC73: start-on-event=SetEventStatus, operation=Event_DemEventParameter_ECU1_DTC73.SetEventStatus
        Ev_SESWE_DemEventParameter_ECU1_DTC73: start-on-event=SetEventStatusWithEnvdata, operation=Event_DemEventParameter_ECU1_DTC73.SetEventStatusWithEnvdata
        Ev_RES_DemEventParameter_ECU1_DTC73: start-on-event=ResetEventStatus, operation=Event_DemEventParameter_ECU1_DTC73.ResetEventStatus
        Ev_CPFF_DemEventParameter_ECU1_DTC73: start-on-event=ClearPrestoredFreezeFrame, operation=Event_DemEventParameter_ECU1_DTC73.ClearPrestoredFreezeFrame
        Ev_PFF_DemEventParameter_ECU1_DTC73: start-on-event=PrestoreFreezeFrame, operation=Event_DemEventParameter_ECU1_DTC73.PrestoreFreezeFrame
        Ev_RDS_DemEventParameter_ECU1_DTC73: start-on-event=ResetEventDebounceStatus, operation=Event_DemEventParameter_ECU1_DTC73.ResetEventDebounceStatus
        Ev_SES_DemEventParameter_ECU1_DTC74: start-on-event=SetEventStatus, operation=Event_DemEventParameter_ECU1_DTC74.SetEventStatus
        Ev_SESWE_DemEventParameter_ECU1_DTC74: start-on-event=SetEventStatusWithEnvdata, operation=Event_DemEventParameter_ECU1_DTC74.SetEventStatusWithEnvdata
        Ev_RES_DemEventParameter_ECU1_DTC74: start-on-event=ResetEventStatus, operation=Event_DemEventParameter_ECU1_DTC74.ResetEventStatus
        Ev_CPFF_DemEventParameter_ECU1_DTC74: start-on-event=ClearPrestoredFreezeFrame, operation=Event_DemEventParameter_ECU1_DTC74.ClearPrestoredFreezeFrame
        Ev_PFF_DemEventParameter_ECU1_DTC74: start-on-event=PrestoreFreezeFrame, operation=Event_DemEventParameter_ECU1_DTC74.PrestoreFreezeFrame
        Ev_RDS_DemEventParameter_ECU1_DTC74: start-on-event=ResetEventDebounceStatus, operation=Event_DemEventParameter_ECU1_DTC74.ResetEventDebounceStatus
        Ev_SES_DemEventParameter_ECU1_DTC75: start-on-event=SetEventStatus, operation=Event_DemEventParameter_ECU1_DTC75.SetEventStatus
        Ev_SESWE_DemEventParameter_ECU1_DTC75: start-on-event=SetEventStatusWithEnvdata, operation=Event_DemEventParameter_ECU1_DTC75.SetEventStatusWithEnvdata
        Ev_RES_DemEventParameter_ECU1_DTC75: start-on-event=ResetEventStatus, operation=Event_DemEventParameter_ECU1_DTC75.ResetEventStatus
        Ev_CPFF_DemEventParameter_ECU1_DTC75: start-on-event=ClearPrestoredFreezeFrame, operation=Event_DemEventParameter_ECU1_DTC75.ClearPrestoredFreezeFrame
        Ev_PFF_DemEventParameter_ECU1_DTC75: start-on-event=PrestoreFreezeFrame, operation=Event_DemEventParameter_ECU1_DTC75.PrestoreFreezeFrame
        Ev_RDS_DemEventParameter_ECU1_DTC75: start-on-event=ResetEventDebounceStatus, operation=Event_DemEventParameter_ECU1_DTC75.ResetEventDebounceStatus
        Ev_SES_DemEventParameter_ECU1_DTC76: start-on-event=SetEventStatus, operation=Event_DemEventParameter_ECU1_DTC76.SetEventStatus
        Ev_SESWE_DemEventParameter_ECU1_DTC76: start-on-event=SetEventStatusWithEnvdata, operation=Event_DemEventParameter_ECU1_DTC76.SetEventStatusWithEnvdata
        Ev_RES_DemEventParameter_ECU1_DTC76: start-on-event=ResetEventStatus, operation=Event_DemEventParameter_ECU1_DTC76.ResetEventStatus
        Ev_CPFF_DemEventParameter_ECU1_DTC76: start-on-event=ClearPrestoredFreezeFrame, operation=Event_DemEventParameter_ECU1_DTC76.ClearPrestoredFreezeFrame
        Ev_PFF_DemEventParameter_ECU1_DTC76: start-on-event=PrestoreFreezeFrame, operation=Event_DemEventParameter_ECU1_DTC76.PrestoreFreezeFrame
        Ev_RDS_DemEventParameter_ECU1_DTC76: start-on-event=ResetEventDebounceStatus, operation=Event_DemEventParameter_ECU1_DTC76.ResetEventDebounceStatus
        Ev_SES_DemEventParameter_ECU1_DTC77: start-on-event=SetEventStatus, operation=Event_DemEventParameter_ECU1_DTC77.SetEventStatus
        Ev_SESWE_DemEventParameter_ECU1_DTC77: start-on-event=SetEventStatusWithEnvdata, operation=Event_DemEventParameter_ECU1_DTC77.SetEventStatusWithEnvdata
        Ev_RES_DemEventParameter_ECU1_DTC77: start-on-event=ResetEventStatus, operation=Event_DemEventParameter_ECU1_DTC77.ResetEventStatus
        Ev_CPFF_DemEventParameter_ECU1_DTC77: start-on-event=ClearPrestoredFreezeFrame, operation=Event_DemEventParameter_ECU1_DTC77.ClearPrestoredFreezeFrame
        Ev_PFF_DemEventParameter_ECU1_DTC77: start-on-event=PrestoreFreezeFrame, operation=Event_DemEventParameter_ECU1_DTC77.PrestoreFreezeFrame
        Ev_RDS_DemEventParameter_ECU1_DTC77: start-on-event=ResetEventDebounceStatus, operation=Event_DemEventParameter_ECU1_DTC77.ResetEventDebounceStatus
        Ev_SES_DemEventParameter_ECU1_DTC78: start-on-event=SetEventStatus, operation=Event_DemEventParameter_ECU1_DTC78.SetEventStatus
        Ev_SESWE_DemEventParameter_ECU1_DTC78: start-on-event=SetEventStatusWithEnvdata, operation=Event_DemEventParameter_ECU1_DTC78.SetEventStatusWithEnvdata
        Ev_RES_DemEventParameter_ECU1_DTC78: start-on-event=ResetEventStatus, operation=Event_DemEventParameter_ECU1_DTC78.ResetEventStatus
        Ev_CPFF_DemEventParameter_ECU1_DTC78: start-on-event=ClearPrestoredFreezeFrame, operation=Event_DemEventParameter_ECU1_DTC78.ClearPrestoredFreezeFrame
        Ev_PFF_DemEventParameter_ECU1_DTC78: start-on-event=PrestoreFreezeFrame, operation=Event_DemEventParameter_ECU1_DTC78.PrestoreFreezeFrame
        Ev_RDS_DemEventParameter_ECU1_DTC78: start-on-event=ResetEventDebounceStatus, operation=Event_DemEventParameter_ECU1_DTC78.ResetEventDebounceStatus
        Ev_SES_DemEventParameter_ECU1_DTC79: start-on-event=SetEventStatus, operation=Event_DemEventParameter_ECU1_DTC79.SetEventStatus
        Ev_SESWE_DemEventParameter_ECU1_DTC79: start-on-event=SetEventStatusWithEnvdata, operation=Event_DemEventParameter_ECU1_DTC79.SetEventStatusWithEnvdata
        Ev_RES_DemEventParameter_ECU1_DTC79: start-on-event=ResetEventStatus, operation=Event_DemEventParameter_ECU1_DTC79.ResetEventStatus
        Ev_CPFF_DemEventParameter_ECU1_DTC79: start-on-event=ClearPrestoredFreezeFrame, operation=Event_DemEventParameter_ECU1_DTC79.ClearPrestoredFreezeFrame
        Ev_PFF_DemEventParameter_ECU1_DTC79: start-on-event=PrestoreFreezeFrame, operation=Event_DemEventParameter_ECU1_DTC79.PrestoreFreezeFrame
        Ev_RDS_DemEventParameter_ECU1_DTC79: start-on-event=ResetEventDebounceStatus, operation=Event_DemEventParameter_ECU1_DTC79.ResetEventDebounceStatus
        Ev_SES_DemEventParameter_ECU1_DTC80: start-on-event=SetEventStatus, operation=Event_DemEventParameter_ECU1_DTC80.SetEventStatus
        Ev_SESWE_DemEventParameter_ECU1_DTC80: start-on-event=SetEventStatusWithEnvdata, operation=Event_DemEventParameter_ECU1_DTC80.SetEventStatusWithEnvdata
        Ev_RES_DemEventParameter_ECU1_DTC80: start-on-event=ResetEventStatus, operation=Event_DemEventParameter_ECU1_DTC80.ResetEventStatus
        Ev_CPFF_DemEventParameter_ECU1_DTC80: start-on-event=ClearPrestoredFreezeFrame, operation=Event_DemEventParameter_ECU1_DTC80.ClearPrestoredFreezeFrame
        Ev_PFF_DemEventParameter_ECU1_DTC80: start-on-event=PrestoreFreezeFrame, operation=Event_DemEventParameter_ECU1_DTC80.PrestoreFreezeFrame
        Ev_RDS_DemEventParameter_ECU1_DTC80: start-on-event=ResetEventDebounceStatus, operation=Event_DemEventParameter_ECU1_DTC80.ResetEventDebounceStatus
        Ev_SES_DemEventParameter_ECU1_DTC81: start-on-event=SetEventStatus, operation=Event_DemEventParameter_ECU1_DTC81.SetEventStatus
        Ev_SESWE_DemEventParameter_ECU1_DTC81: start-on-event=SetEventStatusWithEnvdata, operation=Event_DemEventParameter_ECU1_DTC81.SetEventStatusWithEnvdata
        Ev_RES_DemEventParameter_ECU1_DTC81: start-on-event=ResetEventStatus, operation=Event_DemEventParameter_ECU1_DTC81.ResetEventStatus
        Ev_CPFF_DemEventParameter_ECU1_DTC81: start-on-event=ClearPrestoredFreezeFrame, operation=Event_DemEventParameter_ECU1_DTC81.ClearPrestoredFreezeFrame
        Ev_PFF_DemEventParameter_ECU1_DTC81: start-on-event=PrestoreFreezeFrame, operation=Event_DemEventParameter_ECU1_DTC81.PrestoreFreezeFrame
        Ev_RDS_DemEventParameter_ECU1_DTC81: start-on-event=ResetEventDebounceStatus, operation=Event_DemEventParameter_ECU1_DTC81.ResetEventDebounceStatus
        Ev_SES_DemEventParameter_ECU1_DTC82: start-on-event=SetEventStatus, operation=Event_DemEventParameter_ECU1_DTC82.SetEventStatus
        Ev_SESWE_DemEventParameter_ECU1_DTC82: start-on-event=SetEventStatusWithEnvdata, operation=Event_DemEventParameter_ECU1_DTC82.SetEventStatusWithEnvdata
        Ev_RES_DemEventParameter_ECU1_DTC82: start-on-event=ResetEventStatus, operation=Event_DemEventParameter_ECU1_DTC82.ResetEventStatus
        Ev_CPFF_DemEventParameter_ECU1_DTC82: start-on-event=ClearPrestoredFreezeFrame, operation=Event_DemEventParameter_ECU1_DTC82.ClearPrestoredFreezeFrame
        Ev_PFF_DemEventParameter_ECU1_DTC82: start-on-event=PrestoreFreezeFrame, operation=Event_DemEventParameter_ECU1_DTC82.PrestoreFreezeFrame
        Ev_RDS_DemEventParameter_ECU1_DTC82: start-on-event=ResetEventDebounceStatus, operation=Event_DemEventParameter_ECU1_DTC82.ResetEventDebounceStatus
        Ev_SES_DemEventParameter_ECU1_DTC83: start-on-event=SetEventStatus, operation=Event_DemEventParameter_ECU1_DTC83.SetEventStatus
        Ev_SESWE_DemEventParameter_ECU1_DTC83: start-on-event=SetEventStatusWithEnvdata, operation=Event_DemEventParameter_ECU1_DTC83.SetEventStatusWithEnvdata
        Ev_RES_DemEventParameter_ECU1_DTC83: start-on-event=ResetEventStatus, operation=Event_DemEventParameter_ECU1_DTC83.ResetEventStatus
        Ev_CPFF_DemEventParameter_ECU1_DTC83: start-on-event=ClearPrestoredFreezeFrame, operation=Event_DemEventParameter_ECU1_DTC83.ClearPrestoredFreezeFrame
        Ev_PFF_DemEventParameter_ECU1_DTC83: start-on-event=PrestoreFreezeFrame, operation=Event_DemEventParameter_ECU1_DTC83.PrestoreFreezeFrame
        Ev_RDS_DemEventParameter_ECU1_DTC83: start-on-event=ResetEventDebounceStatus, operation=Event_DemEventParameter_ECU1_DTC83.ResetEventDebounceStatus
        Ev_SES_DemEventParameter_ECU1_DTC84: start-on-event=SetEventStatus, operation=Event_DemEventParameter_ECU1_DTC84.SetEventStatus
        Ev_SESWE_DemEventParameter_ECU1_DTC84: start-on-event=SetEventStatusWithEnvdata, operation=Event_DemEventParameter_ECU1_DTC84.SetEventStatusWithEnvdata
        Ev_RES_DemEventParameter_ECU1_DTC84: start-on-event=ResetEventStatus, operation=Event_DemEventParameter_ECU1_DTC84.ResetEventStatus
        Ev_CPFF_DemEventParameter_ECU1_DTC84: start-on-event=ClearPrestoredFreezeFrame, operation=Event_DemEventParameter_ECU1_DTC84.ClearPrestoredFreezeFrame
        Ev_PFF_DemEventParameter_ECU1_DTC84: start-on-event=PrestoreFreezeFrame, operation=Event_DemEventParameter_ECU1_DTC84.PrestoreFreezeFrame
        Ev_RDS_DemEventParameter_ECU1_DTC84: start-on-event=ResetEventDebounceStatus, operation=Event_DemEventParameter_ECU1_DTC84.ResetEventDebounceStatus
        Ev_SES_DemEventParameter_ECU1_DTC85: start-on-event=SetEventStatus, operation=Event_DemEventParameter_ECU1_DTC85.SetEventStatus
        Ev_SESWE_DemEventParameter_ECU1_DTC85: start-on-event=SetEventStatusWithEnvdata, operation=Event_DemEventParameter_ECU1_DTC85.SetEventStatusWithEnvdata
        Ev_RES_DemEventParameter_ECU1_DTC85: start-on-event=ResetEventStatus, operation=Event_DemEventParameter_ECU1_DTC85.ResetEventStatus
        Ev_CPFF_DemEventParameter_ECU1_DTC85: start-on-event=ClearPrestoredFreezeFrame, operation=Event_DemEventParameter_ECU1_DTC85.ClearPrestoredFreezeFrame
        Ev_PFF_DemEventParameter_ECU1_DTC85: start-on-event=PrestoreFreezeFrame, operation=Event_DemEventParameter_ECU1_DTC85.PrestoreFreezeFrame
        Ev_RDS_DemEventParameter_ECU1_DTC85: start-on-event=ResetEventDebounceStatus, operation=Event_DemEventParameter_ECU1_DTC85.ResetEventDebounceStatus
        Ev_SES_DemEventParameter_ECU1_DTC86: start-on-event=SetEventStatus, operation=Event_DemEventParameter_ECU1_DTC86.SetEventStatus
        Ev_SESWE_DemEventParameter_ECU1_DTC86: start-on-event=SetEventStatusWithEnvdata, operation=Event_DemEventParameter_ECU1_DTC86.SetEventStatusWithEnvdata
        Ev_RES_DemEventParameter_ECU1_DTC86: start-on-event=ResetEventStatus, operation=Event_DemEventParameter_ECU1_DTC86.ResetEventStatus
        Ev_CPFF_DemEventParameter_ECU1_DTC86: start-on-event=ClearPrestoredFreezeFrame, operation=Event_DemEventParameter_ECU1_DTC86.ClearPrestoredFreezeFrame
        Ev_PFF_DemEventParameter_ECU1_DTC86: start-on-event=PrestoreFreezeFrame, operation=Event_DemEventParameter_ECU1_DTC86.PrestoreFreezeFrame
        Ev_RDS_DemEventParameter_ECU1_DTC86: start-on-event=ResetEventDebounceStatus, operation=Event_DemEventParameter_ECU1_DTC86.ResetEventDebounceStatus
        Ev_SES_DemEventParameter_ECU1_DTC87: start-on-event=SetEventStatus, operation=Event_DemEventParameter_ECU1_DTC87.SetEventStatus
        Ev_SESWE_DemEventParameter_ECU1_DTC87: start-on-event=SetEventStatusWithEnvdata, operation=Event_DemEventParameter_ECU1_DTC87.SetEventStatusWithEnvdata
        Ev_RES_DemEventParameter_ECU1_DTC87: start-on-event=ResetEventStatus, operation=Event_DemEventParameter_ECU1_DTC87.ResetEventStatus
        Ev_CPFF_DemEventParameter_ECU1_DTC87: start-on-event=ClearPrestoredFreezeFrame, operation=Event_DemEventParameter_ECU1_DTC87.ClearPrestoredFreezeFrame
        Ev_PFF_DemEventParameter_ECU1_DTC87: start-on-event=PrestoreFreezeFrame, operation=Event_DemEventParameter_ECU1_DTC87.PrestoreFreezeFrame
        Ev_RDS_DemEventParameter_ECU1_DTC87: start-on-event=ResetEventDebounceStatus, operation=Event_DemEventParameter_ECU1_DTC87.ResetEventDebounceStatus
        Ev_SES_DemEventParameter_ECU1_DTC88: start-on-event=SetEventStatus, operation=Event_DemEventParameter_ECU1_DTC88.SetEventStatus
        Ev_SESWE_DemEventParameter_ECU1_DTC88: start-on-event=SetEventStatusWithEnvdata, operation=Event_DemEventParameter_ECU1_DTC88.SetEventStatusWithEnvdata
        Ev_RES_DemEventParameter_ECU1_DTC88: start-on-event=ResetEventStatus, operation=Event_DemEventParameter_ECU1_DTC88.ResetEventStatus
        Ev_CPFF_DemEventParameter_ECU1_DTC88: start-on-event=ClearPrestoredFreezeFrame, operation=Event_DemEventParameter_ECU1_DTC88.ClearPrestoredFreezeFrame
        Ev_PFF_DemEventParameter_ECU1_DTC88: start-on-event=PrestoreFreezeFrame, operation=Event_DemEventParameter_ECU1_DTC88.PrestoreFreezeFrame
        Ev_RDS_DemEventParameter_ECU1_DTC88: start-on-event=ResetEventDebounceStatus, operation=Event_DemEventParameter_ECU1_DTC88.ResetEventDebounceStatus
        Ev_SES_DemEventParameter_ECU1_DTC89: start-on-event=SetEventStatus, operation=Event_DemEventParameter_ECU1_DTC89.SetEventStatus
        Ev_SESWE_DemEventParameter_ECU1_DTC89: start-on-event=SetEventStatusWithEnvdata, operation=Event_DemEventParameter_ECU1_DTC89.SetEventStatusWithEnvdata
        Ev_RES_DemEventParameter_ECU1_DTC89: start-on-event=ResetEventStatus, operation=Event_DemEventParameter_ECU1_DTC89.ResetEventStatus
        Ev_CPFF_DemEventParameter_ECU1_DTC89: start-on-event=ClearPrestoredFreezeFrame, operation=Event_DemEventParameter_ECU1_DTC89.ClearPrestoredFreezeFrame
        Ev_PFF_DemEventParameter_ECU1_DTC89: start-on-event=PrestoreFreezeFrame, operation=Event_DemEventParameter_ECU1_DTC89.PrestoreFreezeFrame
        Ev_RDS_DemEventParameter_ECU1_DTC89: start-on-event=ResetEventDebounceStatus, operation=Event_DemEventParameter_ECU1_DTC89.ResetEventDebounceStatus
        Ev_SES_DemEventParameter_ECU1_DTC90: start-on-event=SetEventStatus, operation=Event_DemEventParameter_ECU1_DTC90.SetEventStatus
        Ev_SESWE_DemEventParameter_ECU1_DTC90: start-on-event=SetEventStatusWithEnvdata, operation=Event_DemEventParameter_ECU1_DTC90.SetEventStatusWithEnvdata
        Ev_RES_DemEventParameter_ECU1_DTC90: start-on-event=ResetEventStatus, operation=Event_DemEventParameter_ECU1_DTC90.ResetEventStatus
        Ev_CPFF_DemEventParameter_ECU1_DTC90: start-on-event=ClearPrestoredFreezeFrame, operation=Event_DemEventParameter_ECU1_DTC90.ClearPrestoredFreezeFrame
        Ev_PFF_DemEventParameter_ECU1_DTC90: start-on-event=PrestoreFreezeFrame, operation=Event_DemEventParameter_ECU1_DTC90.PrestoreFreezeFrame
        Ev_RDS_DemEventParameter_ECU1_DTC90: start-on-event=ResetEventDebounceStatus, operation=Event_DemEventParameter_ECU1_DTC90.ResetEventDebounceStatus
        Ev_SES_DemEventParameter_ECU1_DTC91: start-on-event=SetEventStatus, operation=Event_DemEventParameter_ECU1_DTC91.SetEventStatus
        Ev_SESWE_DemEventParameter_ECU1_DTC91: start-on-event=SetEventStatusWithEnvdata, operation=Event_DemEventParameter_ECU1_DTC91.SetEventStatusWithEnvdata
        Ev_RES_DemEventParameter_ECU1_DTC91: start-on-event=ResetEventStatus, operation=Event_DemEventParameter_ECU1_DTC91.ResetEventStatus
        Ev_CPFF_DemEventParameter_ECU1_DTC91: start-on-event=ClearPrestoredFreezeFrame, operation=Event_DemEventParameter_ECU1_DTC91.ClearPrestoredFreezeFrame
        Ev_PFF_DemEventParameter_ECU1_DTC91: start-on-event=PrestoreFreezeFrame, operation=Event_DemEventParameter_ECU1_DTC91.PrestoreFreezeFrame
        Ev_RDS_DemEventParameter_ECU1_DTC91: start-on-event=ResetEventDebounceStatus, operation=Event_DemEventParameter_ECU1_DTC91.ResetEventDebounceStatus
        Ev_SES_DemEventParameter_ECU1_DTC92: start-on-event=SetEventStatus, operation=Event_DemEventParameter_ECU1_DTC92.SetEventStatus
        Ev_SESWE_DemEventParameter_ECU1_DTC92: start-on-event=SetEventStatusWithEnvdata, operation=Event_DemEventParameter_ECU1_DTC92.SetEventStatusWithEnvdata
        Ev_RES_DemEventParameter_ECU1_DTC92: start-on-event=ResetEventStatus, operation=Event_DemEventParameter_ECU1_DTC92.ResetEventStatus
        Ev_CPFF_DemEventParameter_ECU1_DTC92: start-on-event=ClearPrestoredFreezeFrame, operation=Event_DemEventParameter_ECU1_DTC92.ClearPrestoredFreezeFrame
        Ev_PFF_DemEventParameter_ECU1_DTC92: start-on-event=PrestoreFreezeFrame, operation=Event_DemEventParameter_ECU1_DTC92.PrestoreFreezeFrame
        Ev_RDS_DemEventParameter_ECU1_DTC92: start-on-event=ResetEventDebounceStatus, operation=Event_DemEventParameter_ECU1_DTC92.ResetEventDebounceStatus
        Ev_SES_DemEventParameter_ECU1_DTC93: start-on-event=SetEventStatus, operation=Event_DemEventParameter_ECU1_DTC93.SetEventStatus
        Ev_SESWE_DemEventParameter_ECU1_DTC93: start-on-event=SetEventStatusWithEnvdata, operation=Event_DemEventParameter_ECU1_DTC93.SetEventStatusWithEnvdata
        Ev_RES_DemEventParameter_ECU1_DTC93: start-on-event=ResetEventStatus, operation=Event_DemEventParameter_ECU1_DTC93.ResetEventStatus
        Ev_CPFF_DemEventParameter_ECU1_DTC93: start-on-event=ClearPrestoredFreezeFrame, operation=Event_DemEventParameter_ECU1_DTC93.ClearPrestoredFreezeFrame
        Ev_PFF_DemEventParameter_ECU1_DTC93: start-on-event=PrestoreFreezeFrame, operation=Event_DemEventParameter_ECU1_DTC93.PrestoreFreezeFrame
        Ev_RDS_DemEventParameter_ECU1_DTC93: start-on-event=ResetEventDebounceStatus, operation=Event_DemEventParameter_ECU1_DTC93.ResetEventDebounceStatus
        Ev_SES_DemEventParameter_ECU1_DTC94: start-on-event=SetEventStatus, operation=Event_DemEventParameter_ECU1_DTC94.SetEventStatus
        Ev_SESWE_DemEventParameter_ECU1_DTC94: start-on-event=SetEventStatusWithEnvdata, operation=Event_DemEventParameter_ECU1_DTC94.SetEventStatusWithEnvdata
        Ev_RES_DemEventParameter_ECU1_DTC94: start-on-event=ResetEventStatus, operation=Event_DemEventParameter_ECU1_DTC94.ResetEventStatus
        Ev_CPFF_DemEventParameter_ECU1_DTC94: start-on-event=ClearPrestoredFreezeFrame, operation=Event_DemEventParameter_ECU1_DTC94.ClearPrestoredFreezeFrame
        Ev_PFF_DemEventParameter_ECU1_DTC94: start-on-event=PrestoreFreezeFrame, operation=Event_DemEventParameter_ECU1_DTC94.PrestoreFreezeFrame
        Ev_RDS_DemEventParameter_ECU1_DTC94: start-on-event=ResetEventDebounceStatus, operation=Event_DemEventParameter_ECU1_DTC94.ResetEventDebounceStatus
        Ev_SES_DemEventParameter_ECU1_DTC95: start-on-event=SetEventStatus, operation=Event_DemEventParameter_ECU1_DTC95.SetEventStatus
        Ev_SESWE_DemEventParameter_ECU1_DTC95: start-on-event=SetEventStatusWithEnvdata, operation=Event_DemEventParameter_ECU1_DTC95.SetEventStatusWithEnvdata
        Ev_RES_DemEventParameter_ECU1_DTC95: start-on-event=ResetEventStatus, operation=Event_DemEventParameter_ECU1_DTC95.ResetEventStatus
        Ev_CPFF_DemEventParameter_ECU1_DTC95: start-on-event=ClearPrestoredFreezeFrame, operation=Event_DemEventParameter_ECU1_DTC95.ClearPrestoredFreezeFrame
        Ev_PFF_DemEventParameter_ECU1_DTC95: start-on-event=PrestoreFreezeFrame, operation=Event_DemEventParameter_ECU1_DTC95.PrestoreFreezeFrame
        Ev_RDS_DemEventParameter_ECU1_DTC95: start-on-event=ResetEventDebounceStatus, operation=Event_DemEventParameter_ECU1_DTC95.ResetEventDebounceStatus
        Ev_SES_DemEventParameter_ECU1_DTC96: start-on-event=SetEventStatus, operation=Event_DemEventParameter_ECU1_DTC96.SetEventStatus
        Ev_SESWE_DemEventParameter_ECU1_DTC96: start-on-event=SetEventStatusWithEnvdata, operation=Event_DemEventParameter_ECU1_DTC96.SetEventStatusWithEnvdata
        Ev_RES_DemEventParameter_ECU1_DTC96: start-on-event=ResetEventStatus, operation=Event_DemEventParameter_ECU1_DTC96.ResetEventStatus
        Ev_CPFF_DemEventParameter_ECU1_DTC96: start-on-event=ClearPrestoredFreezeFrame, operation=Event_DemEventParameter_ECU1_DTC96.ClearPrestoredFreezeFrame
        Ev_PFF_DemEventParameter_ECU1_DTC96: start-on-event=PrestoreFreezeFrame, operation=Event_DemEventParameter_ECU1_DTC96.PrestoreFreezeFrame
        Ev_RDS_DemEventParameter_ECU1_DTC96: start-on-event=ResetEventDebounceStatus, operation=Event_DemEventParameter_ECU1_DTC96.ResetEventDebounceStatus
        Ev_SES_DemEventParameter_ECU1_DTC97: start-on-event=SetEventStatus, operation=Event_DemEventParameter_ECU1_DTC97.SetEventStatus
        Ev_SESWE_DemEventParameter_ECU1_DTC97: start-on-event=SetEventStatusWithEnvdata, operation=Event_DemEventParameter_ECU1_DTC97.SetEventStatusWithEnvdata
        Ev_RES_DemEventParameter_ECU1_DTC97: start-on-event=ResetEventStatus, operation=Event_DemEventParameter_ECU1_DTC97.ResetEventStatus
        Ev_CPFF_DemEventParameter_ECU1_DTC97: start-on-event=ClearPrestoredFreezeFrame, operation=Event_DemEventParameter_ECU1_DTC97.ClearPrestoredFreezeFrame
        Ev_PFF_DemEventParameter_ECU1_DTC97: start-on-event=PrestoreFreezeFrame, operation=Event_DemEventParameter_ECU1_DTC97.PrestoreFreezeFrame
        Ev_RDS_DemEventParameter_ECU1_DTC97: start-on-event=ResetEventDebounceStatus, operation=Event_DemEventParameter_ECU1_DTC97.ResetEventDebounceStatus
        Ev_SES_DemEventParameter_ECU1_DTC98: start-on-event=SetEventStatus, operation=Event_DemEventParameter_ECU1_DTC98.SetEventStatus
        Ev_SESWE_DemEventParameter_ECU1_DTC98: start-on-event=SetEventStatusWithEnvdata, operation=Event_DemEventParameter_ECU1_DTC98.SetEventStatusWithEnvdata
        Ev_RES_DemEventParameter_ECU1_DTC98: start-on-event=ResetEventStatus, operation=Event_DemEventParameter_ECU1_DTC98.ResetEventStatus
        Ev_CPFF_DemEventParameter_ECU1_DTC98: start-on-event=ClearPrestoredFreezeFrame, operation=Event_DemEventParameter_ECU1_DTC98.ClearPrestoredFreezeFrame
        Ev_PFF_DemEventParameter_ECU1_DTC98: start-on-event=PrestoreFreezeFrame, operation=Event_DemEventParameter_ECU1_DTC98.PrestoreFreezeFrame
        Ev_RDS_DemEventParameter_ECU1_DTC98: start-on-event=ResetEventDebounceStatus, operation=Event_DemEventParameter_ECU1_DTC98.ResetEventDebounceStatus
        Ev_SES_DemEventParameter_ECU1_DTC99: start-on-event=SetEventStatus, operation=Event_DemEventParameter_ECU1_DTC99.SetEventStatus
        Ev_SESWE_DemEventParameter_ECU1_DTC99: start-on-event=SetEventStatusWithEnvdata, operation=Event_DemEventParameter_ECU1_DTC99.SetEventStatusWithEnvdata
        Ev_RES_DemEventParameter_ECU1_DTC99: start-on-event=ResetEventStatus, operation=Event_DemEventParameter_ECU1_DTC99.ResetEventStatus
        Ev_CPFF_DemEventParameter_ECU1_DTC99: start-on-event=ClearPrestoredFreezeFrame, operation=Event_DemEventParameter_ECU1_DTC99.ClearPrestoredFreezeFrame
        Ev_PFF_DemEventParameter_ECU1_DTC99: start-on-event=PrestoreFreezeFrame, operation=Event_DemEventParameter_ECU1_DTC99.PrestoreFreezeFrame
        Ev_RDS_DemEventParameter_ECU1_DTC99: start-on-event=ResetEventDebounceStatus, operation=Event_DemEventParameter_ECU1_DTC99.ResetEventDebounceStatus
        Ev_SES_DemEventParameter_ECU2_DTC00: start-on-event=SetEventStatus, operation=Event_DemEventParameter_ECU2_DTC00.SetEventStatus
        Ev_SESWE_DemEventParameter_ECU2_DTC00: start-on-event=SetEventStatusWithEnvdata, operation=Event_DemEventParameter_ECU2_DTC00.SetEventStatusWithEnvdata
        Ev_RES_DemEventParameter_ECU2_DTC00: start-on-event=ResetEventStatus, operation=Event_DemEventParameter_ECU2_DTC00.ResetEventStatus
        Ev_CPFF_DemEventParameter_ECU2_DTC00: start-on-event=ClearPrestoredFreezeFrame, operation=Event_DemEventParameter_ECU2_DTC00.ClearPrestoredFreezeFrame
        Ev_PFF_DemEventParameter_ECU2_DTC00: start-on-event=PrestoreFreezeFrame, operation=Event_DemEventParameter_ECU2_DTC00.PrestoreFreezeFrame
        Ev_RDS_DemEventParameter_ECU2_DTC00: start-on-event=ResetEventDebounceStatus, operation=Event_DemEventParameter_ECU2_DTC00.ResetEventDebounceStatus
        Ev_SES_DemEventParameter_ECU2_DTC01: start-on-event=SetEventStatus, operation=Event_DemEventParameter_ECU2_DTC01.SetEventStatus
        Ev_SESWE_DemEventParameter_ECU2_DTC01: start-on-event=SetEventStatusWithEnvdata, operation=Event_DemEventParameter_ECU2_DTC01.SetEventStatusWithEnvdata
        Ev_RES_DemEventParameter_ECU2_DTC01: start-on-event=ResetEventStatus, operation=Event_DemEventParameter_ECU2_DTC01.ResetEventStatus
        Ev_CPFF_DemEventParameter_ECU2_DTC01: start-on-event=ClearPrestoredFreezeFrame, operation=Event_DemEventParameter_ECU2_DTC01.ClearPrestoredFreezeFrame
        Ev_PFF_DemEventParameter_ECU2_DTC01: start-on-event=PrestoreFreezeFrame, operation=Event_DemEventParameter_ECU2_DTC01.PrestoreFreezeFrame
        Ev_RDS_DemEventParameter_ECU2_DTC01: start-on-event=ResetEventDebounceStatus, operation=Event_DemEventParameter_ECU2_DTC01.ResetEventDebounceStatus
        Ev_SES_DemEventParameter_ECU2_DTC02: start-on-event=SetEventStatus, operation=Event_DemEventParameter_ECU2_DTC02.SetEventStatus
        Ev_SESWE_DemEventParameter_ECU2_DTC02: start-on-event=SetEventStatusWithEnvdata, operation=Event_DemEventParameter_ECU2_DTC02.SetEventStatusWithEnvdata
        Ev_RES_DemEventParameter_ECU2_DTC02: start-on-event=ResetEventStatus, operation=Event_DemEventParameter_ECU2_DTC02.ResetEventStatus
        Ev_CPFF_DemEventParameter_ECU2_DTC02: start-on-event=ClearPrestoredFreezeFrame, operation=Event_DemEventParameter_ECU2_DTC02.ClearPrestoredFreezeFrame
        Ev_PFF_DemEventParameter_ECU2_DTC02: start-on-event=PrestoreFreezeFrame, operation=Event_DemEventParameter_ECU2_DTC02.PrestoreFreezeFrame
        Ev_RDS_DemEventParameter_ECU2_DTC02: start-on-event=ResetEventDebounceStatus, operation=Event_DemEventParameter_ECU2_DTC02.ResetEventDebounceStatus
        Ev_SES_DemEventParameter_ECU2_DTC03: start-on-event=SetEventStatus, operation=Event_DemEventParameter_ECU2_DTC03.SetEventStatus
        Ev_SESWE_DemEventParameter_ECU2_DTC03: start-on-event=SetEventStatusWithEnvdata, operation=Event_DemEventParameter_ECU2_DTC03.SetEventStatusWithEnvdata
        Ev_RES_DemEventParameter_ECU2_DTC03: start-on-event=ResetEventStatus, operation=Event_DemEventParameter_ECU2_DTC03.ResetEventStatus
        Ev_CPFF_DemEventParameter_ECU2_DTC03: start-on-event=ClearPrestoredFreezeFrame, operation=Event_DemEventParameter_ECU2_DTC03.ClearPrestoredFreezeFrame
        Ev_PFF_DemEventParameter_ECU2_DTC03: start-on-event=PrestoreFreezeFrame, operation=Event_DemEventParameter_ECU2_DTC03.PrestoreFreezeFrame
        Ev_RDS_DemEventParameter_ECU2_DTC03: start-on-event=ResetEventDebounceStatus, operation=Event_DemEventParameter_ECU2_DTC03.ResetEventDebounceStatus
        Ev_SES_DemEventParameter_ECU2_DTC04: start-on-event=SetEventStatus, operation=Event_DemEventParameter_ECU2_DTC04.SetEventStatus
        Ev_SESWE_DemEventParameter_ECU2_DTC04: start-on-event=SetEventStatusWithEnvdata, operation=Event_DemEventParameter_ECU2_DTC04.SetEventStatusWithEnvdata
        Ev_RES_DemEventParameter_ECU2_DTC04: start-on-event=ResetEventStatus, operation=Event_DemEventParameter_ECU2_DTC04.ResetEventStatus
        Ev_CPFF_DemEventParameter_ECU2_DTC04: start-on-event=ClearPrestoredFreezeFrame, operation=Event_DemEventParameter_ECU2_DTC04.ClearPrestoredFreezeFrame
        Ev_PFF_DemEventParameter_ECU2_DTC04: start-on-event=PrestoreFreezeFrame, operation=Event_DemEventParameter_ECU2_DTC04.PrestoreFreezeFrame
        Ev_RDS_DemEventParameter_ECU2_DTC04: start-on-event=ResetEventDebounceStatus, operation=Event_DemEventParameter_ECU2_DTC04.ResetEventDebounceStatus
        Ev_SES_DemEventParameter_ECU2_DTC05: start-on-event=SetEventStatus, operation=Event_DemEventParameter_ECU2_DTC05.SetEventStatus
        Ev_SESWE_DemEventParameter_ECU2_DTC05: start-on-event=SetEventStatusWithEnvdata, operation=Event_DemEventParameter_ECU2_DTC05.SetEventStatusWithEnvdata
        Ev_RES_DemEventParameter_ECU2_DTC05: start-on-event=ResetEventStatus, operation=Event_DemEventParameter_ECU2_DTC05.ResetEventStatus
        Ev_CPFF_DemEventParameter_ECU2_DTC05: start-on-event=ClearPrestoredFreezeFrame, operation=Event_DemEventParameter_ECU2_DTC05.ClearPrestoredFreezeFrame
        Ev_PFF_DemEventParameter_ECU2_DTC05: start-on-event=PrestoreFreezeFrame, operation=Event_DemEventParameter_ECU2_DTC05.PrestoreFreezeFrame
        Ev_RDS_DemEventParameter_ECU2_DTC05: start-on-event=ResetEventDebounceStatus, operation=Event_DemEventParameter_ECU2_DTC05.ResetEventDebounceStatus
        Ev_SES_DemEventParameter_ECU2_DTC06: start-on-event=SetEventStatus, operation=Event_DemEventParameter_ECU2_DTC06.SetEventStatus
        Ev_SESWE_DemEventParameter_ECU2_DTC06: start-on-event=SetEventStatusWithEnvdata, operation=Event_DemEventParameter_ECU2_DTC06.SetEventStatusWithEnvdata
        Ev_RES_DemEventParameter_ECU2_DTC06: start-on-event=ResetEventStatus, operation=Event_DemEventParameter_ECU2_DTC06.ResetEventStatus
        Ev_CPFF_DemEventParameter_ECU2_DTC06: start-on-event=ClearPrestoredFreezeFrame, operation=Event_DemEventParameter_ECU2_DTC06.ClearPrestoredFreezeFrame
        Ev_PFF_DemEventParameter_ECU2_DTC06: start-on-event=PrestoreFreezeFrame, operation=Event_DemEventParameter_ECU2_DTC06.PrestoreFreezeFrame
        Ev_RDS_DemEventParameter_ECU2_DTC06: start-on-event=ResetEventDebounceStatus, operation=Event_DemEventParameter_ECU2_DTC06.ResetEventDebounceStatus
        Ev_SES_DemEventParameter_ECU2_DTC07: start-on-event=SetEventStatus, operation=Event_DemEventParameter_ECU2_DTC07.SetEventStatus
        Ev_SESWE_DemEventParameter_ECU2_DTC07: start-on-event=SetEventStatusWithEnvdata, operation=Event_DemEventParameter_ECU2_DTC07.SetEventStatusWithEnvdata
        Ev_RES_DemEventParameter_ECU2_DTC07: start-on-event=ResetEventStatus, operation=Event_DemEventParameter_ECU2_DTC07.ResetEventStatus
        Ev_CPFF_DemEventParameter_ECU2_DTC07: start-on-event=ClearPrestoredFreezeFrame, operation=Event_DemEventParameter_ECU2_DTC07.ClearPrestoredFreezeFrame
        Ev_PFF_DemEventParameter_ECU2_DTC07: start-on-event=PrestoreFreezeFrame, operation=Event_DemEventParameter_ECU2_DTC07.PrestoreFreezeFrame
        Ev_RDS_DemEventParameter_ECU2_DTC07: start-on-event=ResetEventDebounceStatus, operation=Event_DemEventParameter_ECU2_DTC07.ResetEventDebounceStatus
        Ev_SES_DemEventParameter_ECU2_DTC08: start-on-event=SetEventStatus, operation=Event_DemEventParameter_ECU2_DTC08.SetEventStatus
        Ev_SESWE_DemEventParameter_ECU2_DTC08: start-on-event=SetEventStatusWithEnvdata, operation=Event_DemEventParameter_ECU2_DTC08.SetEventStatusWithEnvdata
        Ev_RES_DemEventParameter_ECU2_DTC08: start-on-event=ResetEventStatus, operation=Event_DemEventParameter_ECU2_DTC08.ResetEventStatus
        Ev_CPFF_DemEventParameter_ECU2_DTC08: start-on-event=ClearPrestoredFreezeFrame, operation=Event_DemEventParameter_ECU2_DTC08.ClearPrestoredFreezeFrame
        Ev_PFF_DemEventParameter_ECU2_DTC08: start-on-event=PrestoreFreezeFrame, operation=Event_DemEventParameter_ECU2_DTC08.PrestoreFreezeFrame
        Ev_RDS_DemEventParameter_ECU2_DTC08: start-on-event=ResetEventDebounceStatus, operation=Event_DemEventParameter_ECU2_DTC08.ResetEventDebounceStatus
        Ev_SES_DemEventParameter_ECU2_DTC09: start-on-event=SetEventStatus, operation=Event_DemEventParameter_ECU2_DTC09.SetEventStatus
        Ev_SESWE_DemEventParameter_ECU2_DTC09: start-on-event=SetEventStatusWithEnvdata, operation=Event_DemEventParameter_ECU2_DTC09.SetEventStatusWithEnvdata
        Ev_RES_DemEventParameter_ECU2_DTC09: start-on-event=ResetEventStatus, operation=Event_DemEventParameter_ECU2_DTC09.ResetEventStatus
        Ev_CPFF_DemEventParameter_ECU2_DTC09: start-on-event=ClearPrestoredFreezeFrame, operation=Event_DemEventParameter_ECU2_DTC09.ClearPrestoredFreezeFrame
        Ev_PFF_DemEventParameter_ECU2_DTC09: start-on-event=PrestoreFreezeFrame, operation=Event_DemEventParameter_ECU2_DTC09.PrestoreFreezeFrame
        Ev_RDS_DemEventParameter_ECU2_DTC09: start-on-event=ResetEventDebounceStatus, operation=Event_DemEventParameter_ECU2_DTC09.ResetEventDebounceStatus
        Ev_SES_DemEventParameter_ECU2_DTC10: start-on-event=SetEventStatus, operation=Event_DemEventParameter_ECU2_DTC10.SetEventStatus
        Ev_SESWE_DemEventParameter_ECU2_DTC10: start-on-event=SetEventStatusWithEnvdata, operation=Event_DemEventParameter_ECU2_DTC10.SetEventStatusWithEnvdata
        Ev_RES_DemEventParameter_ECU2_DTC10: start-on-event=ResetEventStatus, operation=Event_DemEventParameter_ECU2_DTC10.ResetEventStatus
        Ev_CPFF_DemEventParameter_ECU2_DTC10: start-on-event=ClearPrestoredFreezeFrame, operation=Event_DemEventParameter_ECU2_DTC10.ClearPrestoredFreezeFrame
        Ev_PFF_DemEventParameter_ECU2_DTC10: start-on-event=PrestoreFreezeFrame, operation=Event_DemEventParameter_ECU2_DTC10.PrestoreFreezeFrame
        Ev_RDS_DemEventParameter_ECU2_DTC10: start-on-event=ResetEventDebounceStatus, operation=Event_DemEventParameter_ECU2_DTC10.ResetEventDebounceStatus
        Ev_SES_DemEventParameter_ECU2_DTC11: start-on-event=SetEventStatus, operation=Event_DemEventParameter_ECU2_DTC11.SetEventStatus
        Ev_SESWE_DemEventParameter_ECU2_DTC11: start-on-event=SetEventStatusWithEnvdata, operation=Event_DemEventParameter_ECU2_DTC11.SetEventStatusWithEnvdata
        Ev_RES_DemEventParameter_ECU2_DTC11: start-on-event=ResetEventStatus, operation=Event_DemEventParameter_ECU2_DTC11.ResetEventStatus
        Ev_CPFF_DemEventParameter_ECU2_DTC11: start-on-event=ClearPrestoredFreezeFrame, operation=Event_DemEventParameter_ECU2_DTC11.ClearPrestoredFreezeFrame
        Ev_PFF_DemEventParameter_ECU2_DTC11: start-on-event=PrestoreFreezeFrame, operation=Event_DemEventParameter_ECU2_DTC11.PrestoreFreezeFrame
        Ev_RDS_DemEventParameter_ECU2_DTC11: start-on-event=ResetEventDebounceStatus, operation=Event_DemEventParameter_ECU2_DTC11.ResetEventDebounceStatus
        Ev_SES_DemEventParameter_ECU2_DTC12: start-on-event=SetEventStatus, operation=Event_DemEventParameter_ECU2_DTC12.SetEventStatus
        Ev_SESWE_DemEventParameter_ECU2_DTC12: start-on-event=SetEventStatusWithEnvdata, operation=Event_DemEventParameter_ECU2_DTC12.SetEventStatusWithEnvdata
        Ev_RES_DemEventParameter_ECU2_DTC12: start-on-event=ResetEventStatus, operation=Event_DemEventParameter_ECU2_DTC12.ResetEventStatus
        Ev_CPFF_DemEventParameter_ECU2_DTC12: start-on-event=ClearPrestoredFreezeFrame, operation=Event_DemEventParameter_ECU2_DTC12.ClearPrestoredFreezeFrame
        Ev_PFF_DemEventParameter_ECU2_DTC12: start-on-event=PrestoreFreezeFrame, operation=Event_DemEventParameter_ECU2_DTC12.PrestoreFreezeFrame
        Ev_RDS_DemEventParameter_ECU2_DTC12: start-on-event=ResetEventDebounceStatus, operation=Event_DemEventParameter_ECU2_DTC12.ResetEventDebounceStatus
        Ev_SES_DemEventParameter_ECU2_DTC13: start-on-event=SetEventStatus, operation=Event_DemEventParameter_ECU2_DTC13.SetEventStatus
        Ev_SESWE_DemEventParameter_ECU2_DTC13: start-on-event=SetEventStatusWithEnvdata, operation=Event_DemEventParameter_ECU2_DTC13.SetEventStatusWithEnvdata
        Ev_RES_DemEventParameter_ECU2_DTC13: start-on-event=ResetEventStatus, operation=Event_DemEventParameter_ECU2_DTC13.ResetEventStatus
        Ev_CPFF_DemEventParameter_ECU2_DTC13: start-on-event=ClearPrestoredFreezeFrame, operation=Event_DemEventParameter_ECU2_DTC13.ClearPrestoredFreezeFrame
        Ev_PFF_DemEventParameter_ECU2_DTC13: start-on-event=PrestoreFreezeFrame, operation=Event_DemEventParameter_ECU2_DTC13.PrestoreFreezeFrame
        Ev_RDS_DemEventParameter_ECU2_DTC13: start-on-event=ResetEventDebounceStatus, operation=Event_DemEventParameter_ECU2_DTC13.ResetEventDebounceStatus
        Ev_SES_DemEventParameter_ECU2_DTC14: start-on-event=SetEventStatus, operation=Event_DemEventParameter_ECU2_DTC14.SetEventStatus
        Ev_SESWE_DemEventParameter_ECU2_DTC14: start-on-event=SetEventStatusWithEnvdata, operation=Event_DemEventParameter_ECU2_DTC14.SetEventStatusWithEnvdata
        Ev_RES_DemEventParameter_ECU2_DTC14: start-on-event=ResetEventStatus, operation=Event_DemEventParameter_ECU2_DTC14.ResetEventStatus
        Ev_CPFF_DemEventParameter_ECU2_DTC14: start-on-event=ClearPrestoredFreezeFrame, operation=Event_DemEventParameter_ECU2_DTC14.ClearPrestoredFreezeFrame
        Ev_PFF_DemEventParameter_ECU2_DTC14: start-on-event=PrestoreFreezeFrame, operation=Event_DemEventParameter_ECU2_DTC14.PrestoreFreezeFrame
        Ev_RDS_DemEventParameter_ECU2_DTC14: start-on-event=ResetEventDebounceStatus, operation=Event_DemEventParameter_ECU2_DTC14.ResetEventDebounceStatus
        Ev_SES_DemEventParameter_ECU2_DTC15: start-on-event=SetEventStatus, operation=Event_DemEventParameter_ECU2_DTC15.SetEventStatus
        Ev_SESWE_DemEventParameter_ECU2_DTC15: start-on-event=SetEventStatusWithEnvdata, operation=Event_DemEventParameter_ECU2_DTC15.SetEventStatusWithEnvdata
        Ev_RES_DemEventParameter_ECU2_DTC15: start-on-event=ResetEventStatus, operation=Event_DemEventParameter_ECU2_DTC15.ResetEventStatus
        Ev_CPFF_DemEventParameter_ECU2_DTC15: start-on-event=ClearPrestoredFreezeFrame, operation=Event_DemEventParameter_ECU2_DTC15.ClearPrestoredFreezeFrame
        Ev_PFF_DemEventParameter_ECU2_DTC15: start-on-event=PrestoreFreezeFrame, operation=Event_DemEventParameter_ECU2_DTC15.PrestoreFreezeFrame
        Ev_RDS_DemEventParameter_ECU2_DTC15: start-on-event=ResetEventDebounceStatus, operation=Event_DemEventParameter_ECU2_DTC15.ResetEventDebounceStatus
        Ev_SES_DemEventParameter_ECU2_DTC16: start-on-event=SetEventStatus, operation=Event_DemEventParameter_ECU2_DTC16.SetEventStatus
        Ev_SESWE_DemEventParameter_ECU2_DTC16: start-on-event=SetEventStatusWithEnvdata, operation=Event_DemEventParameter_ECU2_DTC16.SetEventStatusWithEnvdata
        Ev_RES_DemEventParameter_ECU2_DTC16: start-on-event=ResetEventStatus, operation=Event_DemEventParameter_ECU2_DTC16.ResetEventStatus
        Ev_CPFF_DemEventParameter_ECU2_DTC16: start-on-event=ClearPrestoredFreezeFrame, operation=Event_DemEventParameter_ECU2_DTC16.ClearPrestoredFreezeFrame
        Ev_PFF_DemEventParameter_ECU2_DTC16: start-on-event=PrestoreFreezeFrame, operation=Event_DemEventParameter_ECU2_DTC16.PrestoreFreezeFrame
        Ev_RDS_DemEventParameter_ECU2_DTC16: start-on-event=ResetEventDebounceStatus, operation=Event_DemEventParameter_ECU2_DTC16.ResetEventDebounceStatus
        Ev_SES_DemEventParameter_ECU2_DTC17: start-on-event=SetEventStatus, operation=Event_DemEventParameter_ECU2_DTC17.SetEventStatus
        Ev_SESWE_DemEventParameter_ECU2_DTC17: start-on-event=SetEventStatusWithEnvdata, operation=Event_DemEventParameter_ECU2_DTC17.SetEventStatusWithEnvdata
        Ev_RES_DemEventParameter_ECU2_DTC17: start-on-event=ResetEventStatus, operation=Event_DemEventParameter_ECU2_DTC17.ResetEventStatus
        Ev_CPFF_DemEventParameter_ECU2_DTC17: start-on-event=ClearPrestoredFreezeFrame, operation=Event_DemEventParameter_ECU2_DTC17.ClearPrestoredFreezeFrame
        Ev_PFF_DemEventParameter_ECU2_DTC17: start-on-event=PrestoreFreezeFrame, operation=Event_DemEventParameter_ECU2_DTC17.PrestoreFreezeFrame
        Ev_RDS_DemEventParameter_ECU2_DTC17: start-on-event=ResetEventDebounceStatus, operation=Event_DemEventParameter_ECU2_DTC17.ResetEventDebounceStatus
        Ev_SES_DemEventParameter_ECU2_DTC18: start-on-event=SetEventStatus, operation=Event_DemEventParameter_ECU2_DTC18.SetEventStatus
        Ev_SESWE_DemEventParameter_ECU2_DTC18: start-on-event=SetEventStatusWithEnvdata, operation=Event_DemEventParameter_ECU2_DTC18.SetEventStatusWithEnvdata
        Ev_RES_DemEventParameter_ECU2_DTC18: start-on-event=ResetEventStatus, operation=Event_DemEventParameter_ECU2_DTC18.ResetEventStatus
        Ev_CPFF_DemEventParameter_ECU2_DTC18: start-on-event=ClearPrestoredFreezeFrame, operation=Event_DemEventParameter_ECU2_DTC18.ClearPrestoredFreezeFrame
        Ev_PFF_DemEventParameter_ECU2_DTC18: start-on-event=PrestoreFreezeFrame, operation=Event_DemEventParameter_ECU2_DTC18.PrestoreFreezeFrame
        Ev_RDS_DemEventParameter_ECU2_DTC18: start-on-event=ResetEventDebounceStatus, operation=Event_DemEventParameter_ECU2_DTC18.ResetEventDebounceStatus
        Ev_SES_DemEventParameter_ECU2_DTC19: start-on-event=SetEventStatus, operation=Event_DemEventParameter_ECU2_DTC19.SetEventStatus
        Ev_SESWE_DemEventParameter_ECU2_DTC19: start-on-event=SetEventStatusWithEnvdata, operation=Event_DemEventParameter_ECU2_DTC19.SetEventStatusWithEnvdata
        Ev_RES_DemEventParameter_ECU2_DTC19: start-on-event=ResetEventStatus, operation=Event_DemEventParameter_ECU2_DTC19.ResetEventStatus
        Ev_CPFF_DemEventParameter_ECU2_DTC19: start-on-event=ClearPrestoredFreezeFrame, operation=Event_DemEventParameter_ECU2_DTC19.ClearPrestoredFreezeFrame
        Ev_PFF_DemEventParameter_ECU2_DTC19: start-on-event=PrestoreFreezeFrame, operation=Event_DemEventParameter_ECU2_DTC19.PrestoreFreezeFrame
        Ev_RDS_DemEventParameter_ECU2_DTC19: start-on-event=ResetEventDebounceStatus, operation=Event_DemEventParameter_ECU2_DTC19.ResetEventDebounceStatus
        Ev_SES_DemEventParameter_ECU2_DTC20: start-on-event=SetEventStatus, operation=Event_DemEventParameter_ECU2_DTC20.SetEventStatus
        Ev_SESWE_DemEventParameter_ECU2_DTC20: start-on-event=SetEventStatusWithEnvdata, operation=Event_DemEventParameter_ECU2_DTC20.SetEventStatusWithEnvdata
        Ev_RES_DemEventParameter_ECU2_DTC20: start-on-event=ResetEventStatus, operation=Event_DemEventParameter_ECU2_DTC20.ResetEventStatus
        Ev_CPFF_DemEventParameter_ECU2_DTC20: start-on-event=ClearPrestoredFreezeFrame, operation=Event_DemEventParameter_ECU2_DTC20.ClearPrestoredFreezeFrame
        Ev_PFF_DemEventParameter_ECU2_DTC20: start-on-event=PrestoreFreezeFrame, operation=Event_DemEventParameter_ECU2_DTC20.PrestoreFreezeFrame
        Ev_RDS_DemEventParameter_ECU2_DTC20: start-on-event=ResetEventDebounceStatus, operation=Event_DemEventParameter_ECU2_DTC20.ResetEventDebounceStatus
        Ev_SES_DemEventParameter_ECU2_DTC21: start-on-event=SetEventStatus, operation=Event_DemEventParameter_ECU2_DTC21.SetEventStatus
        Ev_SESWE_DemEventParameter_ECU2_DTC21: start-on-event=SetEventStatusWithEnvdata, operation=Event_DemEventParameter_ECU2_DTC21.SetEventStatusWithEnvdata
        Ev_RES_DemEventParameter_ECU2_DTC21: start-on-event=ResetEventStatus, operation=Event_DemEventParameter_ECU2_DTC21.ResetEventStatus
        Ev_CPFF_DemEventParameter_ECU2_DTC21: start-on-event=ClearPrestoredFreezeFrame, operation=Event_DemEventParameter_ECU2_DTC21.ClearPrestoredFreezeFrame
        Ev_PFF_DemEventParameter_ECU2_DTC21: start-on-event=PrestoreFreezeFrame, operation=Event_DemEventParameter_ECU2_DTC21.PrestoreFreezeFrame
        Ev_RDS_DemEventParameter_ECU2_DTC21: start-on-event=ResetEventDebounceStatus, operation=Event_DemEventParameter_ECU2_DTC21.ResetEventDebounceStatus
        Ev_SES_DemEventParameter_ECU2_DTC22: start-on-event=SetEventStatus, operation=Event_DemEventParameter_ECU2_DTC22.SetEventStatus
        Ev_SESWE_DemEventParameter_ECU2_DTC22: start-on-event=SetEventStatusWithEnvdata, operation=Event_DemEventParameter_ECU2_DTC22.SetEventStatusWithEnvdata
        Ev_RES_DemEventParameter_ECU2_DTC22: start-on-event=ResetEventStatus, operation=Event_DemEventParameter_ECU2_DTC22.ResetEventStatus
        Ev_CPFF_DemEventParameter_ECU2_DTC22: start-on-event=ClearPrestoredFreezeFrame, operation=Event_DemEventParameter_ECU2_DTC22.ClearPrestoredFreezeFrame
        Ev_PFF_DemEventParameter_ECU2_DTC22: start-on-event=PrestoreFreezeFrame, operation=Event_DemEventParameter_ECU2_DTC22.PrestoreFreezeFrame
        Ev_RDS_DemEventParameter_ECU2_DTC22: start-on-event=ResetEventDebounceStatus, operation=Event_DemEventParameter_ECU2_DTC22.ResetEventDebounceStatus
        Ev_SES_DemEventParameter_ECU2_DTC23: start-on-event=SetEventStatus, operation=Event_DemEventParameter_ECU2_DTC23.SetEventStatus
        Ev_SESWE_DemEventParameter_ECU2_DTC23: start-on-event=SetEventStatusWithEnvdata, operation=Event_DemEventParameter_ECU2_DTC23.SetEventStatusWithEnvdata
        Ev_RES_DemEventParameter_ECU2_DTC23: start-on-event=ResetEventStatus, operation=Event_DemEventParameter_ECU2_DTC23.ResetEventStatus
        Ev_CPFF_DemEventParameter_ECU2_DTC23: start-on-event=ClearPrestoredFreezeFrame, operation=Event_DemEventParameter_ECU2_DTC23.ClearPrestoredFreezeFrame
        Ev_PFF_DemEventParameter_ECU2_DTC23: start-on-event=PrestoreFreezeFrame, operation=Event_DemEventParameter_ECU2_DTC23.PrestoreFreezeFrame
        Ev_RDS_DemEventParameter_ECU2_DTC23: start-on-event=ResetEventDebounceStatus, operation=Event_DemEventParameter_ECU2_DTC23.ResetEventDebounceStatus
        Ev_SES_DemEventParameter_ECU2_DTC24: start-on-event=SetEventStatus, operation=Event_DemEventParameter_ECU2_DTC24.SetEventStatus
        Ev_SESWE_DemEventParameter_ECU2_DTC24: start-on-event=SetEventStatusWithEnvdata, operation=Event_DemEventParameter_ECU2_DTC24.SetEventStatusWithEnvdata
        Ev_RES_DemEventParameter_ECU2_DTC24: start-on-event=ResetEventStatus, operation=Event_DemEventParameter_ECU2_DTC24.ResetEventStatus
        Ev_CPFF_DemEventParameter_ECU2_DTC24: start-on-event=ClearPrestoredFreezeFrame, operation=Event_DemEventParameter_ECU2_DTC24.ClearPrestoredFreezeFrame
        Ev_PFF_DemEventParameter_ECU2_DTC24: start-on-event=PrestoreFreezeFrame, operation=Event_DemEventParameter_ECU2_DTC24.PrestoreFreezeFrame
        Ev_RDS_DemEventParameter_ECU2_DTC24: start-on-event=ResetEventDebounceStatus, operation=Event_DemEventParameter_ECU2_DTC24.ResetEventDebounceStatus
        Ev_SES_DemEventParameter_ECU2_DTC25: start-on-event=SetEventStatus, operation=Event_DemEventParameter_ECU2_DTC25.SetEventStatus
        Ev_SESWE_DemEventParameter_ECU2_DTC25: start-on-event=SetEventStatusWithEnvdata, operation=Event_DemEventParameter_ECU2_DTC25.SetEventStatusWithEnvdata
        Ev_RES_DemEventParameter_ECU2_DTC25: start-on-event=ResetEventStatus, operation=Event_DemEventParameter_ECU2_DTC25.ResetEventStatus
        Ev_CPFF_DemEventParameter_ECU2_DTC25: start-on-event=ClearPrestoredFreezeFrame, operation=Event_DemEventParameter_ECU2_DTC25.ClearPrestoredFreezeFrame
        Ev_PFF_DemEventParameter_ECU2_DTC25: start-on-event=PrestoreFreezeFrame, operation=Event_DemEventParameter_ECU2_DTC25.PrestoreFreezeFrame
        Ev_RDS_DemEventParameter_ECU2_DTC25: start-on-event=ResetEventDebounceStatus, operation=Event_DemEventParameter_ECU2_DTC25.ResetEventDebounceStatus
        Ev_SES_DemEventParameter_ECU2_DTC26: start-on-event=SetEventStatus, operation=Event_DemEventParameter_ECU2_DTC26.SetEventStatus
        Ev_SESWE_DemEventParameter_ECU2_DTC26: start-on-event=SetEventStatusWithEnvdata, operation=Event_DemEventParameter_ECU2_DTC26.SetEventStatusWithEnvdata
        Ev_RES_DemEventParameter_ECU2_DTC26: start-on-event=ResetEventStatus, operation=Event_DemEventParameter_ECU2_DTC26.ResetEventStatus
        Ev_CPFF_DemEventParameter_ECU2_DTC26: start-on-event=ClearPrestoredFreezeFrame, operation=Event_DemEventParameter_ECU2_DTC26.ClearPrestoredFreezeFrame
        Ev_PFF_DemEventParameter_ECU2_DTC26: start-on-event=PrestoreFreezeFrame, operation=Event_DemEventParameter_ECU2_DTC26.PrestoreFreezeFrame
        Ev_RDS_DemEventParameter_ECU2_DTC26: start-on-event=ResetEventDebounceStatus, operation=Event_DemEventParameter_ECU2_DTC26.ResetEventDebounceStatus
        Ev_SES_DemEventParameter_ECU2_DTC27: start-on-event=SetEventStatus, operation=Event_DemEventParameter_ECU2_DTC27.SetEventStatus
        Ev_SESWE_DemEventParameter_ECU2_DTC27: start-on-event=SetEventStatusWithEnvdata, operation=Event_DemEventParameter_ECU2_DTC27.SetEventStatusWithEnvdata
        Ev_RES_DemEventParameter_ECU2_DTC27: start-on-event=ResetEventStatus, operation=Event_DemEventParameter_ECU2_DTC27.ResetEventStatus
        Ev_CPFF_DemEventParameter_ECU2_DTC27: start-on-event=ClearPrestoredFreezeFrame, operation=Event_DemEventParameter_ECU2_DTC27.ClearPrestoredFreezeFrame
        Ev_PFF_DemEventParameter_ECU2_DTC27: start-on-event=PrestoreFreezeFrame, operation=Event_DemEventParameter_ECU2_DTC27.PrestoreFreezeFrame
        Ev_RDS_DemEventParameter_ECU2_DTC27: start-on-event=ResetEventDebounceStatus, operation=Event_DemEventParameter_ECU2_DTC27.ResetEventDebounceStatus
        Ev_SES_DemEventParameter_ECU2_DTC28: start-on-event=SetEventStatus, operation=Event_DemEventParameter_ECU2_DTC28.SetEventStatus
        Ev_SESWE_DemEventParameter_ECU2_DTC28: start-on-event=SetEventStatusWithEnvdata, operation=Event_DemEventParameter_ECU2_DTC28.SetEventStatusWithEnvdata
        Ev_RES_DemEventParameter_ECU2_DTC28: start-on-event=ResetEventStatus, operation=Event_DemEventParameter_ECU2_DTC28.ResetEventStatus
        Ev_CPFF_DemEventParameter_ECU2_DTC28: start-on-event=ClearPrestoredFreezeFrame, operation=Event_DemEventParameter_ECU2_DTC28.ClearPrestoredFreezeFrame
        Ev_PFF_DemEventParameter_ECU2_DTC28: start-on-event=PrestoreFreezeFrame, operation=Event_DemEventParameter_ECU2_DTC28.PrestoreFreezeFrame
